VERSION "HNNBNNNYNNNNNNNNNNNNNNNNNNNNNNNNNNNNNNNNNN/4/%%%/4/'%**4NNN///"

NS_ :

BS_:

BU_: AWC BAP_Tester BMC_MLBevo BMS_MV BMS_NV DCDC_800V_PAG DCDC_HV DCDC_HV_02 DCDC_IHEV FCU_MLBevo_FCEV Gateway Gateway_PAG Ladegeraet_2 Ladegeraet_Konzern LE1 LE2 LE2_3_MLBevo_LB LE_MLBevo LE_MLBevo_LB Sub_Gateway TME

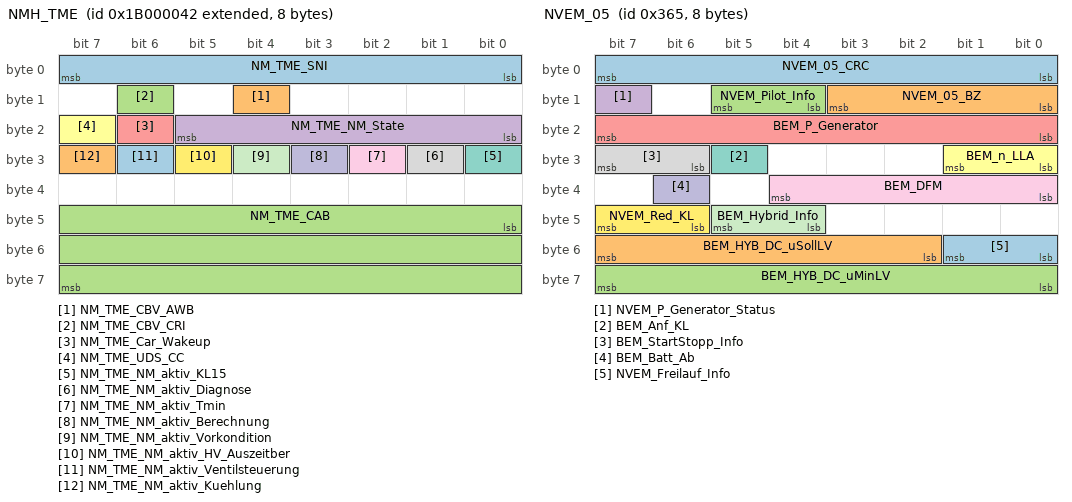
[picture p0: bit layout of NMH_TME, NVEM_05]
BO_ 2600468546 NMH_TME: 8 TME
 SG_ NM_TME_SNI : 0|8@1+ (1,0) [0|255] ""  AWC,BMC_MLBevo,BMS_MV,BMS_NV,DCDC_800V_PAG,DCDC_HV,DCDC_HV_02,DCDC_IHEV,FCU_MLBevo_FCEV,Gateway,Gateway_PAG,Ladegeraet_2,Ladegeraet_Konzern,LE1,LE2,LE2_3_MLBevo_LB,LE_MLBevo,Sub_Gateway
 SG_ NM_TME_CBV_AWB : 12|1@1+ (1,0) [0|1] ""  Gateway,Gateway_PAG
 SG_ NM_TME_CBV_CRI : 14|1@1+ (1,0) [0|1] ""  AWC,BMC_MLBevo,BMS_MV,BMS_NV,DCDC_800V_PAG,DCDC_HV,DCDC_HV_02,DCDC_IHEV,FCU_MLBevo_FCEV,Gateway,Gateway_PAG,Ladegeraet_2,Ladegeraet_Konzern,LE1,LE2,LE2_3_MLBevo_LB,LE_MLBevo,Sub_Gateway
 SG_ NM_TME_NM_State : 16|6@1+ (1,0) [0|63] "" Vector__XXX
 SG_ NM_TME_Car_Wakeup : 22|1@1+ (1,0) [0|1] ""  Gateway,Gateway_PAG
 SG_ NM_TME_UDS_CC : 23|1@1+ (1,0) [0|1] "" Vector__XXX
 SG_ NM_TME_NM_aktiv_KL15 : 24|1@1+ (1,0) [0|1] "" Vector__XXX
 SG_ NM_TME_NM_aktiv_Diagnose : 25|1@1+ (1,0) [0|1] "" Vector__XXX
 SG_ NM_TME_NM_aktiv_Tmin : 26|1@1+ (1,0) [0|1] "" Vector__XXX
 SG_ NM_TME_NM_aktiv_Berechnung : 27|1@1+ (1,0) [0|1] "" Vector__XXX
 SG_ NM_TME_NM_aktiv_Vorkondition : 28|1@1+ (1,0) [0|1] "" Vector__XXX
 SG_ NM_TME_NM_aktiv_HV_Auszeitber : 29|1@1+ (1,0) [0|1] "" Vector__XXX
 SG_ NM_TME_NM_aktiv_Ventilsteuerung : 30|1@1+ (1,0) [0|1] "" Vector__XXX
 SG_ NM_TME_NM_aktiv_Kuehlung : 31|1@1+ (1,0) [0|1] "" Vector__XXX
 SG_ NM_TME_CAB : 40|24@1+ (1,0) [0|16777215] ""  AWC,BMC_MLBevo,BMS_MV,BMS_NV,DCDC_800V_PAG,DCDC_HV,DCDC_HV_02,DCDC_IHEV,FCU_MLBevo_FCEV,Gateway,Gateway_PAG,Ladegeraet_2,Ladegeraet_Konzern,LE1,LE2,LE2_3_MLBevo_LB,LE_MLBevo,Sub_Gateway

BO_ 1635 NVEM_02: 8 Gateway
 SG_ BEM_02_Abschaltstufen : 0|3@1+ (1,0) [0|7] ""  AWC,BMC_MLBevo,DCDC_800V_PAG,DCDC_HV,DCDC_HV_02,Ladegeraet_2,Ladegeraet_Konzern,TME
 SG_ BEM_STH_Zielzeit : 3|4@1+ (5,0) [0|60] "Unit_Minut"  TME
 SG_ BEM_MMI_Vorwarnung : 7|1@1+ (1,0) [0|1] "" Vector__XXX
 SG_ NVEM_Anf_SD_schalten : 15|1@1+ (1,0) [0|1] "" Vector__XXX
 SG_ BEM_Generatordiagnose : 16|2@1+ (1,0) [0|3] "" Vector__XXX
 SG_ BEM_Red_Innengeblaese : 18|2@1+ (1,0) [0|3] ""  TME
 SG_ BEM_STH_Einschaltverbot : 20|1@1+ (1,0) [0|1] ""  TME
 SG_ BEM_HL_Regelung_Status : 21|3@1+ (1,0) [0|7] "" Vector__XXX
 SG_ BEM_Ladezustand : 24|4@1+ (10,0) [0|100] "Unit_PerCent" Vector__XXX
 SG_ BEM_Batteriediagnose : 28|3@1+ (1,0) [0|7] "" Vector__XXX
 SG_ MIB_Stromsparmodus : 31|1@1+ (1,0) [0|1] "" Vector__XXX
 SG_ BEM_REK_aktiv : 37|1@1+ (1,0) [0|1] "" Vector__XXX
 SG_ NVEM_Last_Anf : 38|2@1+ (1,0) [0|3] "" Vector__XXX
 SG_ BEM_UBDM : 40|8@1+ (0.05,5) [5.05|17.7] "Unit_Volt"  AWC,Ladegeraet_2,Ladegeraet_Konzern
 SG_ BEM_UGenSoll : 48|6@1+ (0.1,10.6) [10.6|16] "Unit_Volt" Vector__XXX
 SG_ BEM_Anf_KL15_schalten : 54|2@1+ (1,0) [0|3] "" Vector__XXX
 SG_ NVEM_Batterie_Service : 56|2@1+ (1,0) [0|3] "" Vector__XXX
 SG_ NVEM_Freigabe_OnlineUpdate : 58|1@1+ (1,0) [0|1] ""  AWC
 SG_ NVEM_Freigabe_ORU4 : 59|2@1+ (1,0) [0|3] "" Vector__XXX

BO_ 869 NVEM_05: 8 Gateway
 SG_ NVEM_05_CRC : 0|8@1+ (1,0) [0|255] "" Vector__XXX
 SG_ NVEM_05_BZ : 8|4@1+ (1,0) [0|15] "" Vector__XXX
 SG_ NVEM_Pilot_Info : 12|2@1+ (1,0) [0|3] "" Vector__XXX
 SG_ NVEM_P_Generator_Status : 15|1@1+ (1,0) [0|1] "" Vector__XXX
 SG_ BEM_P_Generator : 16|8@1+ (50,0) [0|12700] "Unit_Watt" Vector__XXX
 SG_ BEM_n_LLA : 24|2@1+ (1,0) [0|3] "" Vector__XXX
 SG_ BEM_Anf_KL : 29|1@1+ (1,0) [0|1] "" Vector__XXX
 SG_ BEM_StartStopp_Info : 30|2@1+ (1,0) [0|3] "" Vector__XXX
 SG_ BEM_DFM : 32|5@1+ (3.225,0.025) [0.025|100] "" Vector__XXX
 SG_ BEM_Batt_Ab : 38|1@1+ (1,0) [0|1] ""  DCDC_800V_PAG,DCDC_IHEV
 SG_ BEM_Hybrid_Info : 44|2@1+ (1,0) [0|3] "" Vector__XXX
 SG_ NVEM_Red_KL : 46|2@1+ (1,0) [0|3] ""  TME
 SG_ NVEM_Freilauf_Info : 48|2@1+ (1,0) [0|3] "" Vector__XXX
 SG_ BEM_HYB_DC_uSollLV : 50|6@1+ (0.1,10.6) [10.6|16] "Unit_Volt"  DCDC_800V_PAG,DCDC_HV,LE_MLBevo
 SG_ BEM_HYB_DC_uMinLV : 56|8@1+ (0.1,0) [0|25.3] "Unit_Volt" Vector__XXX

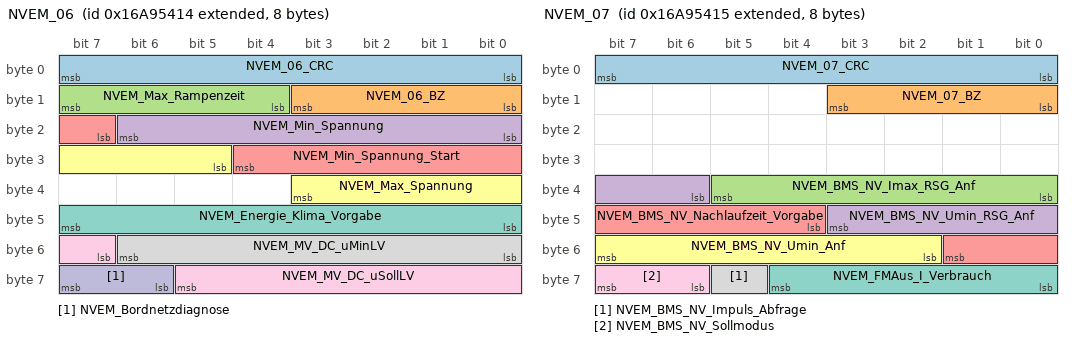
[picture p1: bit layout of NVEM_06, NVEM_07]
BO_ 2527679508 NVEM_06: 8 Gateway
 SG_ NVEM_06_CRC : 0|8@1+ (1,0) [0|255] "" Vector__XXX
 SG_ NVEM_06_BZ : 8|4@1+ (1,0) [0|15] "" Vector__XXX
 SG_ NVEM_Max_Rampenzeit : 12|4@1+ (1,0) [0|15] "" Vector__XXX
 SG_ NVEM_Min_Spannung : 16|7@1+ (0.05,10.6) [10.6|16] "Unit_Volt" Vector__XXX
 SG_ NVEM_Min_Spannung_Start : 23|6@1+ (0.1,7) [7|13.1] "Unit_Volt"  BMS_NV
 SG_ NVEM_Max_Spannung : 29|7@1+ (0.05,10.6) [10.6|16] "Unit_Volt" Vector__XXX
 SG_ NVEM_Energie_Klima_Vorgabe : 40|8@1+ (10,0) [0|2530] "Unit_WattHour" Vector__XXX
 SG_ NVEM_MV_DC_uMinLV : 48|7@1+ (0.1,3.5) [3.5|16] "Unit_Volt"  DCDC_IHEV
 SG_ NVEM_MV_DC_uSollLV : 55|7@1+ (0.05,10.6) [10.6|16] "Unit_Volt"  DCDC_IHEV
 SG_ NVEM_Bordnetzdiagnose : 62|2@1+ (1,0) [0|3] "" Vector__XXX

BO_ 2527679509 NVEM_07: 8 Gateway
 SG_ NVEM_07_CRC : 0|8@1+ (1,0) [0|255] ""  BMS_NV
 SG_ NVEM_07_BZ : 8|4@1+ (1,0) [0|15] ""  BMS_NV
 SG_ NVEM_BMS_NV_Imax_RSG_Anf : 32|6@1+ (20,0) [0|1220] "Unit_Amper"  BMS_NV
 SG_ NVEM_BMS_NV_Umin_RSG_Anf : 38|6@1+ (0.1,7) [7|13.1] "Unit_Volt"  BMS_NV
 SG_ NVEM_BMS_NV_Nachlaufzeit_Vorgabe : 44|6@1+ (1,0) [0|60] "Unit_Minut"  BMS_NV
 SG_ NVEM_BMS_NV_Umin_Anf : 50|6@1+ (0.1,9) [9|15.1] "Unit_Volt"  BMS_NV
 SG_ NVEM_FMAus_I_Verbrauch : 56|5@1+ (5,0) [0|145] "Unit_Amper"  BMS_NV
 SG_ NVEM_BMS_NV_Impuls_Abfrage : 61|1@1+ (1,0) [0|1] ""  BMS_NV
 SG_ NVEM_BMS_NV_Sollmodus : 62|2@1+ (1,0) [0|3] ""  BMS_NV

BO_ 527 NVEM_10: 8 Gateway
 SG_ NVEM_DC_uSoll_NV : 56|8@1+ (0.025,10.6) [10.6|16] "Unit_Volt"  DCDC_HV

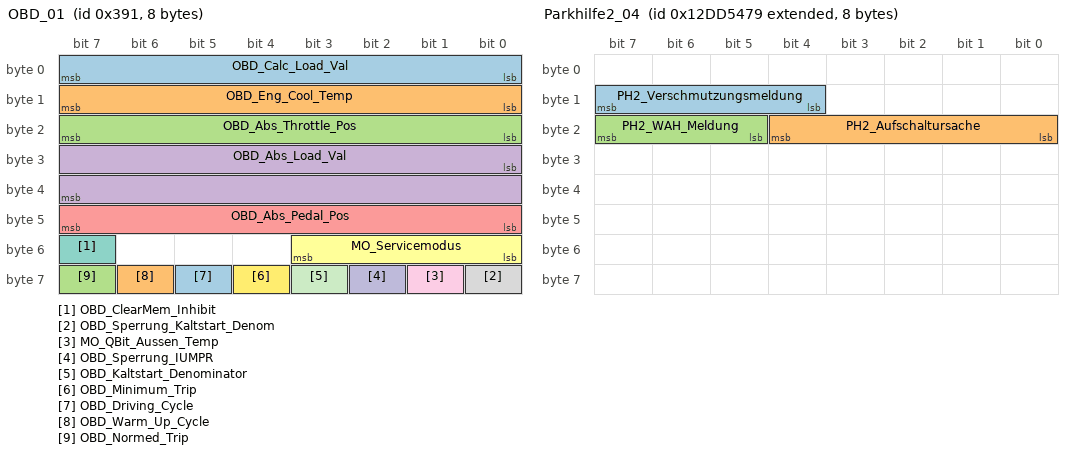
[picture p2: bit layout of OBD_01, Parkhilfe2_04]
BO_ 913 OBD_01: 8 Gateway
 SG_ OBD_Calc_Load_Val : 0|8@1+ (0.392156862745098,0) [0|100] "Unit_PerCent"  BMC_MLBevo,BMS_MV,FCU_MLBevo_FCEV,TME
 SG_ OBD_Eng_Cool_Temp : 8|8@1+ (1,-40) [-40|215] "Unit_DegreCelsi"  BMC_MLBevo,BMS_MV,FCU_MLBevo_FCEV,TME
 SG_ OBD_Abs_Throttle_Pos : 16|8@1+ (0.392156862745098,0) [0|100] "Unit_PerCent"  BMC_MLBevo,BMS_MV,TME
 SG_ OBD_Abs_Load_Val : 24|16@1+ (0.392156862745098,0) [0|25700] "Unit_PerCent"  BMC_MLBevo,BMS_MV,TME
 SG_ OBD_Abs_Pedal_Pos : 40|8@1+ (0.392156862745098,0) [0|100] "Unit_PerCent"  BMC_MLBevo,BMS_MV,FCU_MLBevo_FCEV,TME
 SG_ MO_Servicemodus : 48|4@1+ (1,0) [0|15] "" Vector__XXX
 SG_ OBD_ClearMem_Inhibit : 55|1@1+ (1,0) [0|1] ""  BMC_MLBevo,FCU_MLBevo_FCEV,TME
 SG_ OBD_Sperrung_Kaltstart_Denom : 56|1@1+ (1,0) [0|1] ""  FCU_MLBevo_FCEV,TME
 SG_ MO_QBit_Aussen_Temp : 57|1@1+ (1,0) [0|1] ""  BMC_MLBevo,Ladegeraet_Konzern,TME
 SG_ OBD_Sperrung_IUMPR : 58|1@1+ (1,0) [0|1] ""  AWC,BMC_MLBevo,BMS_MV,FCU_MLBevo_FCEV,Ladegeraet_2,Ladegeraet_Konzern,TME
 SG_ OBD_Kaltstart_Denominator : 59|1@1+ (1,0) [0|1] ""  BMC_MLBevo,BMS_MV,FCU_MLBevo_FCEV,TME
 SG_ OBD_Minimum_Trip : 60|1@1+ (1,0) [0|1] ""  AWC,BMC_MLBevo,BMS_MV,FCU_MLBevo_FCEV,Ladegeraet_2,Ladegeraet_Konzern,TME
 SG_ OBD_Driving_Cycle : 61|1@1+ (1,0) [0|1] ""  AWC,BMC_MLBevo,BMS_MV,FCU_MLBevo_FCEV,Ladegeraet_2,Ladegeraet_Konzern,TME
 SG_ OBD_Warm_Up_Cycle : 62|1@1+ (1,0) [0|1] ""  AWC,BMC_MLBevo,BMS_MV,DCDC_HV_02,DCDC_IHEV,FCU_MLBevo_FCEV,Ladegeraet_2,Ladegeraet_Konzern,TME
 SG_ OBD_Normed_Trip : 63|1@1+ (1,0) [0|1] ""  AWC,BMC_MLBevo,BMS_MV,FCU_MLBevo_FCEV,Ladegeraet_2,Ladegeraet_Konzern,TME

BO_ 2549875343 OBDC_AWC_Req: 8 Gateway
 SG_ OBDC_AWC_Req_Data : 0|64@1+ (1,0) [0|1.84467440737096E+019] ""  AWC

BO_ 2550006415 OBDC_AWC_Resp: 8 AWC
 SG_ OBDC_AWC_Resp_Data : 0|64@1+ (1,0) [0|1.84467440737096E+019] ""  Gateway,Gateway_PAG

BO_ 2549875374 OBDC_BattRegelung_Req: 8 Gateway
 SG_ OBDC_BattRegelung_Req_Data : 0|64@1+ (1,0) [0|1.84467440737096E+019] ""  BMS_NV

BO_ 2550006446 OBDC_BattRegelung_Resp: 8 BMS_NV
 SG_ OBDC_BattRegelung_Resp_Data : 0|64@1+ (1,0) [0|1.84467440737096E+019] ""  Gateway,Gateway_PAG

BO_ 2549875356 OBDC_BMS_48V_Req: 8 Gateway
 SG_ OBDC_BMS_48V_Req_Data : 0|64@1+ (1,0) [0|1.84467440737096E+019] ""  BMS_MV

BO_ 2550006428 OBDC_BMS_48V_Resp: 8 BMS_MV
 SG_ OBDC_BMS_48V_Resp_Data : 0|64@1+ (1,0) [0|1.84467440737096E+019] ""  Gateway,Gateway_PAG

BO_ 2549875399 OBDC_DCDC_HV_02_Req: 8 Gateway
 SG_ OBDC_DCDC_HV_02_Req_Data : 0|64@1+ (1,0) [0|1.84467440737096E+019] ""  DCDC_HV_02

BO_ 2550006471 OBDC_DCDC_HV_02_Resp: 8 DCDC_HV_02
 SG_ OBDC_DCDC_HV_02_Resp_Data : 0|64@1+ (1,0) [0|1.84467440737096E+019] ""  Gateway,Gateway_PAG

BO_ 2549875407 OBDC_DCDC_HV_03_Req: 8 Gateway
 SG_ OBDC_DCDC_HV_03_Req_Data : 0|64@1+ (1,0) [0|1.84467440737096E+019] ""  FCU_MLBevo_FCEV

BO_ 2550006479 OBDC_DCDC_HV_03_Resp: 8 FCU_MLBevo_FCEV
 SG_ OBDC_DCDC_HV_03_Resp_Data : 0|64@1+ (1,0) [0|1.84467440737096E+019] ""  Gateway

BO_ 2549875383 OBDC_DCDC_HV_Req: 8 Gateway
 SG_ OBDC_DCDC_HV_Req_Data : 0|64@1+ (1,0) [0|1.84467440737096E+019] ""  DCDC_800V_PAG,DCDC_HV

BO_ 2550006455 OBDC_DCDC_HV_Resp: 8 DCDC_800V_PAG
 SG_ OBDC_DCDC_HV_Resp_Data : 0|64@1+ (1,0) [0|1.84467440737096E+019] "Unit_None"  Gateway,Gateway_PAG

BO_ 2549875265 OBDC_DCDC_Req: 8 Gateway
 SG_ OBDC_DCDC_Req_Data : 0|64@1+ (1,0) [0|1.84467440737096E+019] ""  DCDC_IHEV

BO_ 2550006337 OBDC_DCDC_Resp: 8 DCDC_IHEV
 SG_ OBDC_DCDC_Resp_Data : 0|64@1+ (1,0) [0|1.84467440737096E+019] ""  Gateway,Gateway_PAG

BO_ 2549875381 OBDC_FCU_Req: 8 Gateway
 SG_ OBDC_FCU_Req_Data : 0|64@1+ (1,0) [0|1.84467440737096E+019] ""  FCU_MLBevo_FCEV

BO_ 2550006453 OBDC_FCU_Resp: 8 FCU_MLBevo_FCEV
 SG_ OBDC_FCU_Resp_Data : 0|64@1+ (1,0) [0|1.84467440737096E+019] ""  Gateway

BO_ 2549940736 OBDC_Funktionaler_Req_All: 8 Gateway
 SG_ OBDC_Funktionaler_Req_All_Data : 0|64@1+ (1,0) [0|1.84467440737096E+019] ""  AWC,BMC_MLBevo,BMS_MV,BMS_NV,DCDC_800V_PAG,DCDC_HV,DCDC_HV_02,DCDC_IHEV,FCU_MLBevo_FCEV,Ladegeraet_2,Ladegeraet_Konzern,TME

BO_ 2549875323 OBDC_Hybrid_01_Req: 8 Gateway
 SG_ OBDC_Hybrid_01_Req_Data : 0|64@1+ (1,0) [0|1.84467440737096E+019] ""  BMC_MLBevo

BO_ 2550006395 OBDC_Hybrid_01_Resp: 8 BMC_MLBevo
 SG_ OBDC_Hybrid_01_Resp_Data : 0|64@1+ (1,0) [0|1.84467440737096E+019] ""  Gateway,Gateway_PAG

BO_ 2549875398 OBDC_Ladegeraet_2_Req: 8 Gateway
 SG_ OBDC_Ladegeraet_2_Req_Data : 0|64@1+ (1,0) [0|1.84467440737096E+019] ""  Ladegeraet_2

BO_ 2550006470 OBDC_Ladegeraet_2_Resp: 8 Ladegeraet_2
 SG_ OBDC_Ladegeraet_2_Resp_Data : 0|64@1+ (1,0) [0|1.84467440737096E+019] ""  Gateway,Gateway_PAG

BO_ 2549875268 OBDC_Ladegeraet_Req: 8 Gateway
 SG_ OBDC_Ladegeraet_Req_Data : 0|64@1+ (1,0) [0|1.84467440737096E+019] ""  Ladegeraet_Konzern

BO_ 2550006340 OBDC_Ladegeraet_Resp: 8 Ladegeraet_Konzern
 SG_ OBDC_Ladegeraet_Resp_Data : 0|64@1+ (1,0) [0|1.84467440737096E+019] ""  Gateway,Gateway_PAG

BO_ 2549903568 OBDC_SSN_BJB_Req: 8 Gateway
 SG_ OBDC_SSN_BJB_Req_Data : 0|64@1+ (1,0) [0|1.84467440737096E+019] ""  BMC_MLBevo

BO_ 2550034640 OBDC_SSN_BJB_Resp: 8 BMC_MLBevo
 SG_ OBDC_SSN_BJB_Resp_Data : 0|64@1+ (1,0) [0|1.84467440737096E+019] ""  Gateway,Gateway_PAG

BO_ 2549903569 OBDC_SSN_CMC_01_Req: 8 Gateway
 SG_ OBDC_SSN_CMC_01_Req_Data : 0|64@1+ (1,0) [0|1.84467440737096E+019] ""  BMC_MLBevo

BO_ 2550034641 OBDC_SSN_CMC_01_Resp: 8 BMC_MLBevo
 SG_ OBDC_SSN_CMC_01_Resp_Data : 0|64@1+ (1,0) [0|1.84467440737096E+019] ""  Gateway,Gateway_PAG

BO_ 2549903570 OBDC_SSN_CMC_02_Req: 8 Gateway
 SG_ OBDC_SSN_CMC_02_Req_Data : 0|64@1+ (1,0) [0|1.84467440737096E+019] ""  BMC_MLBevo

BO_ 2550034642 OBDC_SSN_CMC_02_Resp: 8 BMC_MLBevo
 SG_ OBDC_SSN_CMC_02_Resp_Data : 0|64@1+ (1,0) [0|1.84467440737096E+019] ""  Gateway,Gateway_PAG

BO_ 2549903571 OBDC_SSN_CMC_03_Req: 8 Gateway
 SG_ OBDC_SSN_CMC_03_Req_Data : 0|64@1+ (1,0) [0|1.84467440737096E+019] ""  BMC_MLBevo

BO_ 2550034643 OBDC_SSN_CMC_03_Resp: 8 BMC_MLBevo
 SG_ OBDC_SSN_CMC_03_Resp_Data : 0|64@1+ (1,0) [0|1.84467440737096E+019] ""  Gateway,Gateway_PAG

BO_ 2549903572 OBDC_SSN_CMC_04_Req: 8 Gateway
 SG_ OBDC_SSN_CMC_04_Req_Data : 0|64@1+ (1,0) [0|1.84467440737096E+019] ""  BMC_MLBevo

BO_ 2550034644 OBDC_SSN_CMC_04_Resp: 8 BMC_MLBevo
 SG_ OBDC_SSN_CMC_04_Resp_Data : 0|64@1+ (1,0) [0|1.84467440737096E+019] ""  Gateway,Gateway_PAG

BO_ 2549903573 OBDC_SSN_CMC_05_Req: 8 Gateway
 SG_ OBDC_SSN_CMC_05_Req_Data : 0|64@1+ (1,0) [0|1.84467440737096E+019] ""  BMC_MLBevo

BO_ 2550034645 OBDC_SSN_CMC_05_Resp: 8 BMC_MLBevo
 SG_ OBDC_SSN_CMC_05_Resp_Data : 0|64@1+ (1,0) [0|1.84467440737096E+019] ""  Gateway,Gateway_PAG

BO_ 2549903574 OBDC_SSN_CMC_06_Req: 8 Gateway
 SG_ OBDC_SSN_CMC_06_Req_Data : 0|64@1+ (1,0) [0|1.84467440737096E+019] ""  BMC_MLBevo

BO_ 2550034646 OBDC_SSN_CMC_06_Resp: 8 BMC_MLBevo
 SG_ OBDC_SSN_CMC_06_Resp_Data : 0|64@1+ (1,0) [0|1.84467440737096E+019] ""  Gateway,Gateway_PAG

BO_ 2549903575 OBDC_SSN_CMC_07_Req: 8 Gateway
 SG_ OBDC_SSN_CMC_07_Req_Data : 0|64@1+ (1,0) [0|1.84467440737096E+019] ""  BMC_MLBevo

BO_ 2550034647 OBDC_SSN_CMC_07_Resp: 8 BMC_MLBevo
 SG_ OBDC_SSN_CMC_07_Resp_Data : 0|64@1+ (1,0) [0|1.84467440737096E+019] ""  Gateway,Gateway_PAG

BO_ 2549903576 OBDC_SSN_CMC_08_Req: 8 Gateway
 SG_ OBDC_SSN_CMC_08_Req_Data : 0|64@1+ (1,0) [0|1.84467440737096E+019] ""  BMC_MLBevo

BO_ 2550034648 OBDC_SSN_CMC_08_Resp: 8 BMC_MLBevo
 SG_ OBDC_SSN_CMC_08_Resp_Data : 0|64@1+ (1,0) [0|1.84467440737096E+019] ""  Gateway,Gateway_PAG

BO_ 2549903577 OBDC_SSN_CMC_09_Req: 8 Gateway
 SG_ OBDC_SSN_CMC_09_Req_Data : 0|64@1+ (1,0) [0|1.84467440737096E+019] ""  BMC_MLBevo

BO_ 2550034649 OBDC_SSN_CMC_09_Resp: 8 BMC_MLBevo
 SG_ OBDC_SSN_CMC_09_Resp_Data : 0|64@1+ (1,0) [0|1.84467440737096E+019] ""  Gateway,Gateway_PAG

BO_ 2549903578 OBDC_SSN_CMC_10_Req: 8 Gateway
 SG_ OBDC_SSN_CMC_10_Req_Data : 0|64@1+ (1,0) [0|1.84467440737096E+019] ""  BMC_MLBevo

BO_ 2550034650 OBDC_SSN_CMC_10_Resp: 8 BMC_MLBevo
 SG_ OBDC_SSN_CMC_10_Resp_Data : 0|64@1+ (1,0) [0|1.84467440737096E+019] ""  Gateway,Gateway_PAG

BO_ 2549903579 OBDC_SSN_CMC_11_Req: 8 Gateway
 SG_ OBDC_SSN_CMC_11_Req_Data : 0|64@1+ (1,0) [0|1.84467440737096E+019] ""  BMC_MLBevo

BO_ 2550034651 OBDC_SSN_CMC_11_Resp: 8 BMC_MLBevo
 SG_ OBDC_SSN_CMC_11_Resp_Data : 0|64@1+ (1,0) [0|1.84467440737096E+019] ""  Gateway,Gateway_PAG

BO_ 2549903580 OBDC_SSN_CMC_12_Req: 8 Gateway
 SG_ OBDC_SSN_CMC_12_Req_Data : 0|64@1+ (1,0) [0|1.84467440737096E+019] ""  BMC_MLBevo

BO_ 2550034652 OBDC_SSN_CMC_12_Resp: 8 BMC_MLBevo
 SG_ OBDC_SSN_CMC_12_Resp_Data : 0|64@1+ (1,0) [0|1.84467440737096E+019] ""  Gateway,Gateway_PAG

BO_ 2549903601 OBDC_SSN_CMC_13_Req: 8 Gateway
 SG_ OBDC_SSN_CMC_13_Req_Data : 0|64@1+ (1,0) [0|1.84467440737096E+019] ""  BMC_MLBevo

BO_ 2550034673 OBDC_SSN_CMC_13_Resp: 8 BMC_MLBevo
 SG_ OBDC_SSN_CMC_13_Resp_Data : 0|64@1+ (1,0) [0|1.84467440737096E+019] ""  Gateway,Gateway_PAG

BO_ 2549903602 OBDC_SSN_CMC_14_Req: 8 Gateway
 SG_ OBDC_SSN_CMC_14_Req_Data : 0|64@1+ (1,0) [0|1.84467440737096E+019] ""  BMC_MLBevo

BO_ 2550034674 OBDC_SSN_CMC_14_Resp: 8 BMC_MLBevo
 SG_ OBDC_SSN_CMC_14_Resp_Data : 0|64@1+ (1,0) [0|1.84467440737096E+019] ""  Gateway,Gateway_PAG

BO_ 2549903603 OBDC_SSN_CMC_15_Req: 8 Gateway
 SG_ OBDC_SSN_CMC_15_Req_Data : 0|64@1+ (1,0) [0|1.84467440737096E+019] ""  BMC_MLBevo

BO_ 2550034675 OBDC_SSN_CMC_15_Resp: 8 BMC_MLBevo
 SG_ OBDC_SSN_CMC_15_Resp_Data : 0|64@1+ (1,0) [0|1.84467440737096E+019] ""  Gateway,Gateway_PAG

BO_ 2549875380 OBDC_TelemetrieSG_Req: 8 Gateway
 SG_ OBDC_TelemetrieSG_Req_Data : 0|64@1+ (1,0) [0|1.84467440737096E+019] ""  Sub_Gateway

BO_ 2550006452 OBDC_TelemetrieSG_Resp: 8 Sub_Gateway
 SG_ OBDC_TelemetrieSG_Resp_Data : 0|64@1+ (1,0) [0|1.84467440737096E+019] ""  Gateway

BO_ 2549875266 OBDC_TME_Req: 8 Gateway
 SG_ OBDC_TME_Req_Data : 0|64@1+ (1,0) [0|1.84467440737096E+019] ""  TME

BO_ 2550006338 OBDC_TME_Resp: 8 TME
 SG_ OBDC_TME_Resp_Data : 0|64@1+ (1,0) [0|1.84467440737096E+019] ""  Gateway,Gateway_PAG

BO_ 2589283656 ORU_01: 8 Gateway
 SG_ ORU_Warnung : 58|2@1+ (1,0) [0|3] "" Vector__XXX
 SG_ ORU_Status : 61|3@1+ (1,0) [0|7] ""  AWC,BMC_MLBevo,DCDC_800V_PAG,DCDC_HV,DCDC_HV_02,Ladegeraet_2,Ladegeraet_Konzern,TME

BO_ 872 Parkhilfe2_01: 8 Gateway
 SG_ PH2_Visualisierung : 0|3@1+ (1,0) [0|7] ""  AWC
 SG_ PDC2_Tonausgabe_Front : 4|4@1+ (1,0) [0|15] "" Vector__XXX
 SG_ PDC2_Tonausgabe_Heck : 8|4@1+ (1,0) [0|15] "" Vector__XXX
 SG_ PH2_nachtr_Stopp_An : 12|1@1+ (1,0) [0|1] "" Vector__XXX
 SG_ PH2_Abschaltursache : 13|3@1+ (1,0) [0|7] ""  AWC
 SG_ PH2_Opt_Anzeige_V_ein : 16|1@1+ (1,0) [0|1] "" Vector__XXX
 SG_ PH2_Opt_Anzeige_H_ein : 17|1@1+ (1,0) [0|1] "" Vector__XXX
 SG_ PH2_Opt_Anz_V_Hindernis : 18|1@1+ (1,0) [0|1] "" Vector__XXX
 SG_ PH2_Opt_Anz_H_Hindernis : 19|1@1+ (1,0) [0|1] "" Vector__XXX
 SG_ PH2_Tongeber_V_aktiv : 20|1@1+ (1,0) [0|1] "" Vector__XXX
 SG_ PH2_Tongeber_H_aktiv : 21|1@1+ (1,0) [0|1] "" Vector__XXX
 SG_ PH2_Tongeber_mute : 22|1@1+ (1,0) [0|1] "" Vector__XXX
 SG_ PH2_Anf_Audioabsenkung : 23|1@1+ (1,0) [0|1] "" Vector__XXX
 SG_ PH2_Tongeber_H_verfuegbar : 24|1@1+ (1,0) [0|1] "" Vector__XXX
 SG_ PH2_Taster : 28|2@1+ (1,0) [0|3] "" Vector__XXX
 SG_ PH2_Anf_Verdeck : 30|2@1+ (1,0) [0|3] "" Vector__XXX
 SG_ PH2_Frequenz_hinten : 32|4@1+ (1,0) [0|15] "" Vector__XXX
 SG_ PH2_Lautstaerke_hinten : 36|4@1+ (1,0) [0|15] "" Vector__XXX
 SG_ PH2_Frequenz_vorn : 40|4@1+ (1,0) [0|15] "" Vector__XXX
 SG_ PH2_Lautstaerke_vorn : 44|4@1+ (1,0) [0|15] "" Vector__XXX
 SG_ PH2_StartStopp_Info : 49|2@1+ (1,0) [0|3] "" Vector__XXX
 SG_ PH2_Stoermeldung : 52|4@1+ (1,0) [0|15] "" Vector__XXX
 SG_ PH2_defekt : 56|1@1+ (1,0) [0|1] "" Vector__XXX
 SG_ PH2_gestoert : 57|1@1+ (1,0) [0|1] "" Vector__XXX
 SG_ PH2_Systemzustand : 58|3@1+ (1,0) [0|7] ""  AWC
 SG_ PH2_Display_Kundenwunsch : 61|2@1+ (1,0) [0|3] "" Vector__XXX

BO_ 2463978617 Parkhilfe2_04: 8 Gateway
 SG_ PH2_Verschmutzungsmeldung : 12|4@1+ (1,0) [0|15] "" Vector__XXX
 SG_ PH2_Aufschaltursache : 16|5@1+ (1,0) [0|31] ""  AWC
 SG_ PH2_WAH_Meldung : 21|3@1+ (1,0) [0|7] "" Vector__XXX

BO_ 1175 Parkhilfe_01: 8 Gateway
 SG_ PH_Visualisierung : 0|3@1+ (1,0) [0|7] ""  AWC
 SG_ PDC_Tonausgabe_Front : 4|4@1+ (1,0) [0|15] "" Vector__XXX
 SG_ PDC_Tonausgabe_Heck : 8|4@1+ (1,0) [0|15] "" Vector__XXX
 SG_ PH_nachtr_Stopp_Anf : 12|1@1+ (1,0) [0|1] "" Vector__XXX
 SG_ PH_Abschaltursache : 13|3@1+ (1,0) [0|7] ""  AWC
 SG_ PH_Opt_Anzeige_V_ein : 16|1@1+ (1,0) [0|1] "" Vector__XXX
 SG_ PH_Opt_Anzeige_H_ein : 17|1@1+ (1,0) [0|1] "" Vector__XXX
 SG_ PH_Opt_Anz_V_Hindernis : 18|1@1+ (1,0) [0|1] "" Vector__XXX
 SG_ PH_Opt_Anz_H_Hindernis : 19|1@1+ (1,0) [0|1] "" Vector__XXX
 SG_ PH_Tongeber_V_aktiv : 20|1@1+ (1,0) [0|1] "" Vector__XXX
 SG_ PH_Tongeber_H_aktiv : 21|1@1+ (1,0) [0|1] "" Vector__XXX
 SG_ PH_Tongeber_mute : 22|1@1+ (1,0) [0|1] "" Vector__XXX
 SG_ PH_Anf_Audioabsenkung : 23|1@1+ (1,0) [0|1] "" Vector__XXX
 SG_ PH_Tongeber_H_verfuegbar : 24|1@1+ (1,0) [0|1] "" Vector__XXX
 SG_ PLA_Anf_Aufschaltung_RVC : 25|1@1+ (1,0) [0|1] "" Vector__XXX
 SG_ PH_Taster : 28|2@1+ (1,0) [0|3] "" Vector__XXX
 SG_ PH_Anf_Verdeck : 30|2@1+ (1,0) [0|3] "" Vector__XXX
 SG_ PH_Frequenz_hinten : 32|4@1+ (1,0) [0|15] "" Vector__XXX
 SG_ PH_Lautstaerke_hinten : 36|4@1+ (1,0) [0|15] "" Vector__XXX
 SG_ PH_Frequenz_vorn : 40|4@1+ (1,0) [0|15] "" Vector__XXX
 SG_ PH_Lautstaerke_vorn : 44|4@1+ (1,0) [0|15] "" Vector__XXX
 SG_ PH_StartStopp_Info : 49|2@1+ (1,0) [0|3] "" Vector__XXX
 SG_ PH_Stoermeldung : 52|4@1+ (1,0) [0|15] "" Vector__XXX
 SG_ PH_defekt : 56|1@1+ (1,0) [0|1] "" Vector__XXX
 SG_ PH_gestoert : 57|1@1+ (1,0) [0|1] "" Vector__XXX
 SG_ PH_Systemzustand : 58|3@1+ (1,0) [0|7] ""  AWC
 SG_ PH_Display_Kundenwunsch : 61|2@1+ (1,0) [0|3] "" Vector__XXX

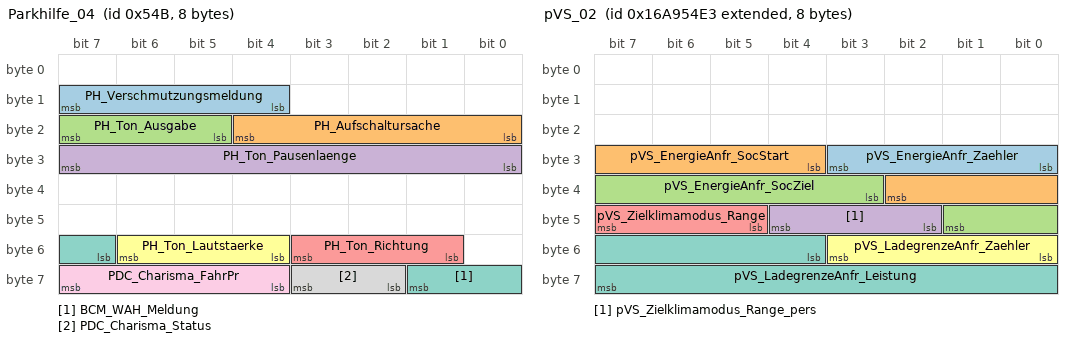
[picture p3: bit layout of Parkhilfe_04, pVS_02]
BO_ 1355 Parkhilfe_04: 8 Gateway
 SG_ PH_Verschmutzungsmeldung : 12|4@1+ (1,0) [0|15] "" Vector__XXX
 SG_ PH_Aufschaltursache : 16|5@1+ (1,0) [0|31] ""  AWC
 SG_ PH_Ton_Ausgabe : 21|3@1+ (1,0) [0|7] "" Vector__XXX
 SG_ PH_Ton_Pausenlaenge : 24|8@1+ (1,0) [0|255] "" Vector__XXX
 SG_ PH_Ton_Richtung : 49|3@1+ (1,0) [0|7] "" Vector__XXX
 SG_ PH_Ton_Lautstaerke : 52|3@1+ (1,0) [0|7] "" Vector__XXX
 SG_ BCM_WAH_Meldung : 55|3@1+ (1,0) [0|7] "" Vector__XXX
 SG_ PDC_Charisma_Status : 58|2@1+ (1,0) [0|3] "" Vector__XXX
 SG_ PDC_Charisma_FahrPr : 60|4@1+ (1,0) [0|15] "" Vector__XXX

BO_ 617 PIF_01: 8 Gateway
 SG_ PIF_Toggle : 0|1@1+ (1,0) [0|1] ""  TME
 SG_ PIF_ST_Status : 1|2@1+ (1,0) [0|3] ""  TME
 SG_ PIF_MT_Status : 3|2@1+ (1,0) [0|3] ""  TME
 SG_ PIF_LT_Status : 5|2@1+ (1,0) [0|3] ""  TME
 SG_ PIF_Identifier : 7|3@1+ (1,0) [0|7] ""  TME
 SG_ PIF_ST_Bin_0 : 10|2@1+ (1,0) [0|3] ""  TME
 SG_ PIF_ST_Bin_1 : 12|2@1+ (1,0) [0|3] ""  TME
 SG_ PIF_ST_Bin_2 : 14|2@1+ (1,0) [0|3] ""  TME
 SG_ PIF_ST_Bin_3 : 16|2@1+ (1,0) [0|3] ""  TME
 SG_ PIF_ST_Bin_4 : 18|2@1+ (1,0) [0|3] ""  TME
 SG_ PIF_ST_Bin_5 : 20|2@1+ (1,0) [0|3] ""  TME
 SG_ PIF_ST_Bin_6 : 22|2@1+ (1,0) [0|3] ""  TME
 SG_ PIF_ST_Bin_7 : 24|2@1+ (1,0) [0|3] ""  TME
 SG_ PIF_ST_Bin_8 : 26|2@1+ (1,0) [0|3] ""  TME
 SG_ PIF_MT_Bin_0 : 28|2@1+ (1,0) [0|3] ""  TME
 SG_ PIF_MT_Bin_1 : 30|2@1+ (1,0) [0|3] ""  TME
 SG_ PIF_MT_Bin_2 : 32|2@1+ (1,0) [0|3] ""  TME
 SG_ PIF_MT_Bin_3 : 34|2@1+ (1,0) [0|3] ""  TME
 SG_ PIF_MT_Bin_4 : 36|2@1+ (1,0) [0|3] ""  TME
 SG_ PIF_MT_Bin_5 : 38|2@1+ (1,0) [0|3] ""  TME
 SG_ PIF_MT_Bin_6 : 40|2@1+ (1,0) [0|3] ""  TME
 SG_ PIF_MT_Bin_7 : 42|2@1+ (1,0) [0|3] ""  TME
 SG_ PIF_MT_Bin_8 : 44|2@1+ (1,0) [0|3] ""  TME
 SG_ PIF_LT_Bin_0 : 46|2@1+ (1,0) [0|3] ""  TME
 SG_ PIF_LT_Bin_1 : 48|2@1+ (1,0) [0|3] ""  TME
 SG_ PIF_LT_Bin_2 : 50|2@1+ (1,0) [0|3] ""  TME
 SG_ PIF_LT_Bin_3 : 52|2@1+ (1,0) [0|3] ""  TME
 SG_ PIF_LT_Bin_4 : 54|2@1+ (1,0) [0|3] ""  TME
 SG_ PIF_LT_Bin_5 : 56|2@1+ (1,0) [0|3] ""  TME
 SG_ PIF_LT_Bin_6 : 58|2@1+ (1,0) [0|3] ""  TME
 SG_ PIF_LT_Bin_7 : 60|2@1+ (1,0) [0|3] ""  TME
 SG_ PIF_LT_Bin_8 : 62|2@1+ (1,0) [0|3] ""  TME

BO_ 2549876804 PnC_Ladegeraet_Req: 8 Ladegeraet_Konzern
 SG_ PnC_Ladegeraet_Req_Data : 0|64@1+ (1,0) [0|1.84467440737096E+019] "Unit_None"  Gateway,Gateway_PAG

BO_ 2550007876 PnC_Ladegeraet_Resp: 8 Gateway
 SG_ PnC_Ladegeraet_Resp_Data : 0|64@1+ (1,0) [0|1.84467440737096E+019] "Unit_None"  Ladegeraet_Konzern

BO_ 2527679715 pVS_02: 8 Gateway_PAG
 SG_ pVS_EnergieAnfr_Zaehler : 24|4@1+ (1,0) [0|13] "Unit_None"  BMC_MLBevo
 SG_ pVS_EnergieAnfr_SocStart : 28|7@1+ (1,0) [0|100] "Unit_PerCent"  BMC_MLBevo
 SG_ pVS_EnergieAnfr_SocZiel : 35|7@1+ (1,0) [0|100] "Unit_PerCent"  BMC_MLBevo
 SG_ pVS_Zielklimamodus_Range_pers : 42|3@1+ (1,0) [0|7] "" Vector__XXX
 SG_ pVS_Zielklimamodus_Range : 45|3@1+ (1,0) [0|7] "" Vector__XXX
 SG_ pVS_LadegrenzeAnfr_Zaehler : 48|4@1+ (1,0) [0|13] "Unit_None"  BMC_MLBevo
 SG_ pVS_LadegrenzeAnfr_Leistung : 52|12@1+ (200,0) [0|818600] "Unit_Watt"  BMC_MLBevo

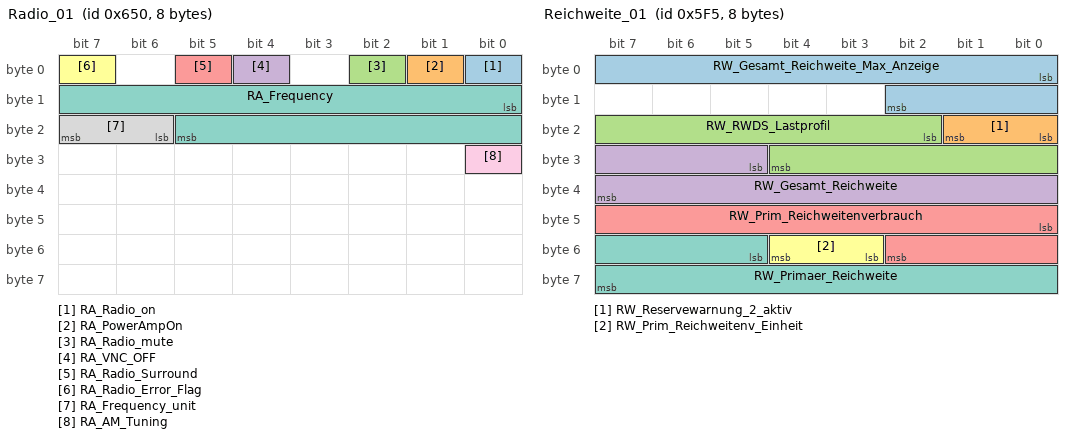
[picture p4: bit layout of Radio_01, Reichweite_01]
BO_ 1616 Radio_01: 8 Gateway
 SG_ RA_Radio_on : 0|1@1+ (1,0) [0|1] ""  DCDC_800V_PAG,DCDC_IHEV
 SG_ RA_PowerAmpOn : 1|1@1+ (1,0) [0|1] "" Vector__XXX
 SG_ RA_Radio_mute : 2|1@1+ (1,0) [0|1] "" Vector__XXX
 SG_ RA_VNC_OFF : 4|1@1+ (1,0) [0|1] "" Vector__XXX
 SG_ RA_Radio_Surround : 5|1@1+ (1,0) [0|1] "" Vector__XXX
 SG_ RA_Radio_Error_Flag : 7|1@1+ (1,0) [0|1] "" Vector__XXX
 SG_ RA_Frequency : 8|14@1+ (1,0) [0|16383] ""  DCDC_800V_PAG,DCDC_IHEV
 SG_ RA_Frequency_unit : 22|2@1+ (1,0) [0|3] ""  DCDC_800V_PAG,DCDC_IHEV
 SG_ RA_AM_Tuning : 24|1@1+ (1,0) [0|1] ""  DCDC_800V_PAG,DCDC_IHEV

BO_ 1525 Reichweite_01: 8 Gateway
 SG_ RW_Gesamt_Reichweite_Max_Anzeige : 0|11@1+ (1,0) [0|2047] ""  Sub_Gateway
 SG_ RW_Reservewarnung_2_aktiv : 16|2@1+ (1,0) [0|3] ""  Sub_Gateway,TME
 SG_ RW_RWDS_Lastprofil : 18|11@1+ (1,0) [0|2045] "Unit_Amper"  BMC_MLBevo,Sub_Gateway
 SG_ RW_Gesamt_Reichweite : 29|11@1+ (1,0) [0|2044] "Unit_KiloMeter"  Ladegeraet_Konzern,Sub_Gateway
 SG_ RW_Prim_Reichweitenverbrauch : 40|11@1+ (0.1,0) [0|204.4] "Unit_None"  Ladegeraet_Konzern,Sub_Gateway
 SG_ RW_Prim_Reichweitenv_Einheit : 51|2@1+ (1,0) [0|3] ""  Sub_Gateway
 SG_ RW_Primaer_Reichweite : 53|11@1+ (1,0) [0|2044] "Unit_KiloMeter"  Ladegeraet_Konzern,Sub_Gateway

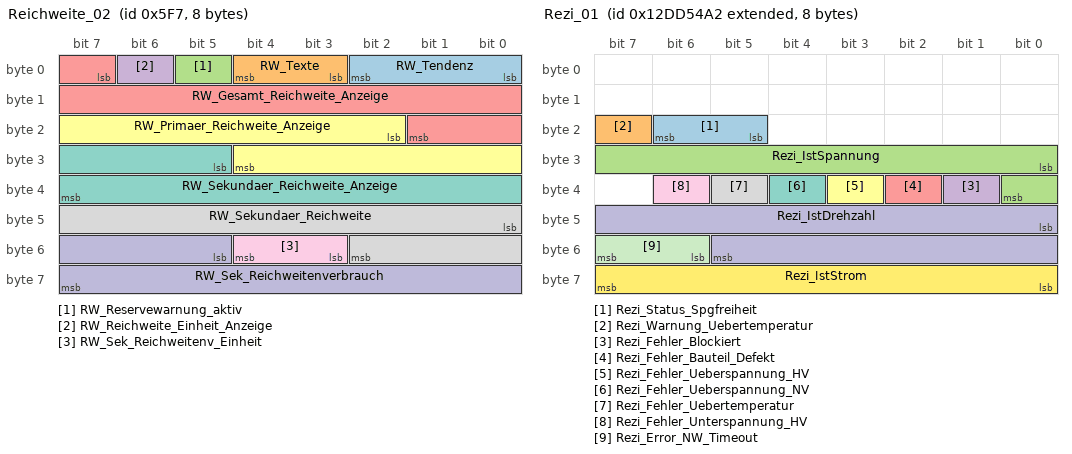
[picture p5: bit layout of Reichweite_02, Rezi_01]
BO_ 1527 Reichweite_02: 8 Gateway
 SG_ RW_Tendenz : 0|3@1+ (1,0) [0|7] ""  Sub_Gateway
 SG_ RW_Texte : 3|2@1+ (1,0) [0|3] ""  Sub_Gateway
 SG_ RW_Reservewarnung_aktiv : 5|1@1+ (1,0) [0|1] ""  Sub_Gateway,TME
 SG_ RW_Reichweite_Einheit_Anzeige : 6|1@1+ (1,0) [0|1] ""  Sub_Gateway
 SG_ RW_Gesamt_Reichweite_Anzeige : 7|11@1+ (1,0) [0|2044] ""  Sub_Gateway
 SG_ RW_Primaer_Reichweite_Anzeige : 18|11@1+ (1,0) [0|2044] ""  Ladegeraet_Konzern,Sub_Gateway
 SG_ RW_Sekundaer_Reichweite_Anzeige : 29|11@1+ (1,0) [0|2044] ""  Sub_Gateway
 SG_ RW_Sekundaer_Reichweite : 40|11@1+ (1,0) [0|2044] "Unit_KiloMeter"  Ladegeraet_Konzern,Sub_Gateway
 SG_ RW_Sek_Reichweitenv_Einheit : 51|2@1+ (1,0) [0|3] ""  Sub_Gateway
 SG_ RW_Sek_Reichweitenverbrauch : 53|11@1+ (0.1,0) [0|204.4] "Unit_None"  Sub_Gateway

BO_ 2463978658 Rezi_01: 8 FCU_MLBevo_FCEV
 SG_ Rezi_Status_Spgfreiheit : 21|2@1+ (1,0) [0|3] ""  Gateway
 SG_ Rezi_Warnung_Uebertemperatur : 23|1@1+ (1,0) [0|1] "" Vector__XXX
 SG_ Rezi_IstSpannung : 24|9@1+ (2,0) [0|1020] "Unit_Volt"  Gateway
 SG_ Rezi_Fehler_Blockiert : 33|1@1+ (1,0) [0|1] "" Vector__XXX
 SG_ Rezi_Fehler_Bauteil_Defekt : 34|1@1+ (1,0) [0|1] "" Vector__XXX
 SG_ Rezi_Fehler_Ueberspannung_HV : 35|1@1+ (1,0) [0|1] "" Vector__XXX
 SG_ Rezi_Fehler_Ueberspannung_NV : 36|1@1+ (1,0) [0|1] "" Vector__XXX
 SG_ Rezi_Fehler_Uebertemperatur : 37|1@1+ (1,0) [0|1] "" Vector__XXX
 SG_ Rezi_Fehler_Unterspannung_HV : 38|1@1+ (1,0) [0|1] "" Vector__XXX
 SG_ Rezi_IstDrehzahl : 40|14@1+ (2,0) [0|32764] "Unit_RevPerMinute" Vector__XXX
 SG_ Rezi_Error_NW_Timeout : 54|2@1+ (1,0) [0|3] "" Vector__XXX
 SG_ Rezi_IstStrom : 56|8@1+ (0.1,0) [0|25.4] "Unit_Amper" Vector__XXX

BO_ 1126 RTM_01: 8 Gateway
 SG_ RTM_Warnstatus : 62|2@1+ (1,0) [0|3] ""  Sub_Gateway

BO_ 2527679790 RTM_02: 8 Sub_Gateway
 SG_ RTM_02_Dummy : 63|1@1+ (1,0) [0|1] ""  Gateway,Gateway_PAG

BO_ 2527679791 RTM_03: 8 Sub_Gateway
 SG_ RTM_03_Dummy : 63|1@1+ (1,0) [0|1] ""  Gateway,Gateway_PAG

BO_ 2527679792 RTM_04: 8 Gateway
 SG_ RTM_04_Dummy : 63|1@1+ (1,0) [0|1] ""  Sub_Gateway

BO_ 1313 STH_01: 8 Gateway
 SG_ STH_Funk_ein : 0|1@1+ (1,0) [0|1] ""  Ladegeraet_Konzern
 SG_ STH_Funk_aus : 1|1@1+ (1,0) [0|1] ""  Ladegeraet_Konzern
 SG_ STH_Zusatzheizung : 2|1@1+ (1,0) [0|1] ""  TME
 SG_ STH_LED : 3|1@1+ (1,0) [0|1] ""  TME
 SG_ STH_Pumpe_ein : 4|1@1+ (1,0) [0|1] ""  TME
 SG_ STH_Geblaese : 5|1@1+ (1,0) [0|1] ""  TME
 SG_ STH_EKP_Anst : 6|1@1+ (1,0) [0|1] "" Vector__XXX
 SG_ STH_Start_folgt : 7|1@1+ (1,0) [0|1] "" Vector__XXX
 SG_ STH_Ventiloeffnungszeit : 8|6@1+ (1,0) [0|63] "Unit_Minut" Vector__XXX
 SG_ STH_Ventil_Status : 14|1@1+ (1,0) [0|1] ""  TME
 SG_ STH_Fehler_ElWaPu : 15|1@1+ (1,0) [0|1] ""  TME
 SG_ STH_Waermeeintrag : 16|6@1+ (1,0) [0|63] "" Vector__XXX
 SG_ STH_Pumpen_Anf_extern : 22|1@1+ (1,0) [0|1] "" Vector__XXX
 SG_ STH_KL_HUP : 23|1@1+ (1,0) [0|1] "" Vector__XXX
 SG_ STH_KVS : 24|13@1+ (1,0) [0|8191] "Unit_MilliLiter" Vector__XXX
 SG_ STH_Fehlerstatus : 37|3@1+ (1,0) [0|7] ""  TME
 SG_ STH_Heizleistung : 40|8@1+ (1,0) [0|255] "" Vector__XXX
 SG_ STH_Wassertemp : 48|8@1+ (0.75,-40) [-40|142.25] "Unit_DegreCelsi"  TME
 SG_ STH_Texte : 56|3@1+ (1,0) [0|7] ""  TME
 SG_ STH_Motorvorwaermung : 59|1@1+ (1,0) [0|1] "" Vector__XXX
 SG_ STH_Servicemode : 60|1@1+ (1,0) [0|1] "" Vector__XXX
 SG_ STH_war_aktiv : 61|1@1+ (1,0) [0|1] "" Vector__XXX
 SG_ STH_KVS_Ueberlauf : 62|1@1+ (1,0) [0|1] "" Vector__XXX
 SG_ STH_SH_ZH : 63|1@1+ (1,0) [0|1] "" Vector__XXX

BO_ 505 STP_03: 8 Gateway
 SG_ STP_03_CRC : 0|8@1+ (1,0) [0|255] "" Vector__XXX
 SG_ STP_03_BZ : 8|4@1+ (1,0) [0|15] "" Vector__XXX
 SG_ STP_Slave_Status : 12|4@1+ (1,0) [0|15] "" Vector__XXX
 SG_ FZE_STP_Abschaltbedingung : 16|3@1+ (1,0) [0|7] "" Vector__XXX
 SG_ ACA_HF_Grund_AV_AB : 19|3@1+ (1,0) [0|7] "" Vector__XXX
 SG_ FZE_STP_Status : 22|2@1+ (1,0) [0|3] "" Vector__XXX
 SG_ STP_Notlaufaktivierung : 25|1@1+ (1,0) [0|1] "" Vector__XXX
 SG_ STP_Funktion_freigegeben : 26|1@1+ (1,0) [0|1] ""  TME
 SG_ ACA_QF_Status_Anzeige : 27|4@1+ (1,0) [0|15] "" Vector__XXX
 SG_ ACF_SwuFahrerUnaufmerksam : 31|1@1+ (1,0) [0|1] "" Vector__XXX
 SG_ ACA_QF_Fahreruebernahme : 32|2@1+ (1,0) [0|3] "" Vector__XXX
 SG_ ACA_HF_Status : 34|4@1+ (1,0) [0|15] "" Vector__XXX
 SG_ FZE_Spurwechsel_erkannt_li : 40|1@1+ (1,0) [0|1] "" Vector__XXX
 SG_ FZE_Spurwechsel_erkannt_re : 41|1@1+ (1,0) [0|1] "" Vector__XXX
 SG_ ACF_Spurwechsel_moeglich : 42|1@1+ (1,0) [0|1] "" Vector__XXX
 SG_ ACF_Spurwechsel_wahrscheinlich : 43|1@1+ (1,0) [0|1] "" Vector__XXX
 SG_ FZE_STP_Aktivierverhinderung : 44|2@1+ (1,0) [0|3] "" Vector__XXX

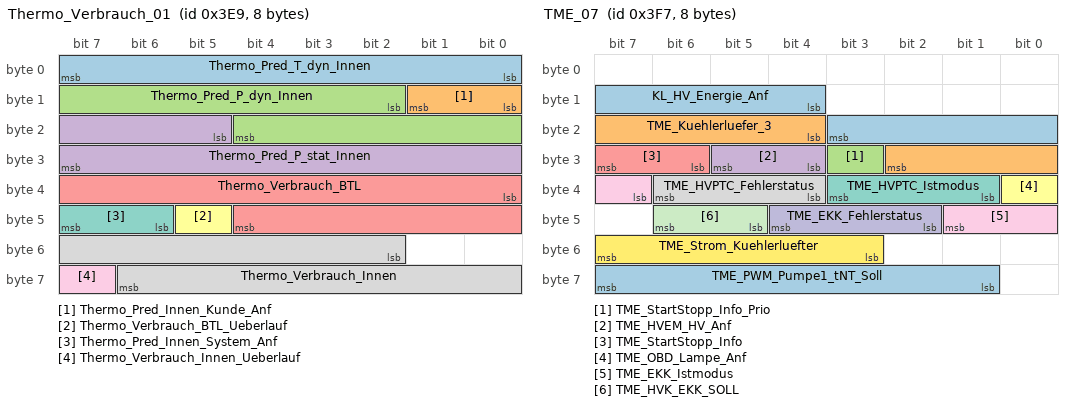
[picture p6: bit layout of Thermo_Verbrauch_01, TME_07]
BO_ 1001 Thermo_Verbrauch_01: 8 TME
 SG_ Thermo_Pred_T_dyn_Innen : 0|8@1+ (1,0) [0|253] "Unit_Minut"  Gateway,Gateway_PAG
 SG_ Thermo_Pred_Innen_Kunde_Anf : 8|2@1+ (1,0) [0|3] "Unit_None"  Gateway,Gateway_PAG
 SG_ Thermo_Pred_P_dyn_Innen : 10|11@1+ (10,0) [0|20450] "Unit_Watt"  Gateway,Gateway_PAG
 SG_ Thermo_Pred_P_stat_Innen : 21|11@1+ (10,0) [0|20450] "Unit_Watt"  Gateway,Gateway_PAG
 SG_ Thermo_Verbrauch_BTL : 32|13@1+ (1,0) [0|8191] "Unit_WattSecond"  Gateway,Gateway_PAG
 SG_ Thermo_Verbrauch_BTL_Ueberlauf : 45|1@1+ (1,0) [0|1] ""  Gateway,Gateway_PAG
 SG_ Thermo_Pred_Innen_System_Anf : 46|2@1+ (1,0) [0|3] "Unit_None"  Gateway,Gateway_PAG
 SG_ Thermo_Verbrauch_Innen : 50|13@1+ (1,0) [0|8191] "Unit_WattSecond"  Gateway,Gateway_PAG
 SG_ Thermo_Verbrauch_Innen_Ueberlauf : 63|1@1+ (1,0) [0|1] ""  Gateway,Gateway_PAG

BO_ 1015 TME_07: 8 TME
 SG_ KL_HV_Energie_Anf : 12|8@1+ (50,0) [0|12600] "Unit_WattHour"  Gateway,Gateway_PAG,Ladegeraet_Konzern
 SG_ TME_Kuehlerluefer_3 : 20|7@1+ (1,0) [0|100] "Unit_PerCent"  Gateway,Gateway_PAG
 SG_ TME_StartStopp_Info_Prio : 27|1@1+ (1,0) [0|1] ""  Gateway,Gateway_PAG
 SG_ TME_HVEM_HV_Anf : 28|2@1+ (1,0) [0|3] ""  Gateway,Gateway_PAG
 SG_ TME_StartStopp_Info : 30|2@1+ (1,0) [0|3] ""  Gateway,Gateway_PAG
 SG_ TME_OBD_Lampe_Anf : 32|1@1+ (1,0) [0|1] ""  Gateway,Gateway_PAG
 SG_ TME_HVPTC_Istmodus : 33|3@1+ (1,0) [0|7] ""  Gateway,Gateway_PAG
 SG_ TME_HVPTC_Fehlerstatus : 36|3@1+ (1,0) [0|7] ""  Gateway,Gateway_PAG
 SG_ TME_EKK_Istmodus : 39|3@1+ (1,0) [0|7] ""  Gateway,Gateway_PAG
 SG_ TME_EKK_Fehlerstatus : 42|3@1+ (1,0) [0|7] ""  Gateway,Gateway_PAG
 SG_ TME_HVK_EKK_SOLL : 45|2@1+ (1,0) [0|3] ""  Gateway,Gateway_PAG
 SG_ TME_Strom_Kuehlerluefter : 51|5@1+ (5,0) [0|145] "Unit_Amper"  Gateway,Gateway_PAG
 SG_ TME_PWM_Pumpe1_tNT_Soll : 57|7@1+ (1,0) [0|100] "Unit_PerCent"  BMC_MLBevo,Gateway,Gateway_PAG

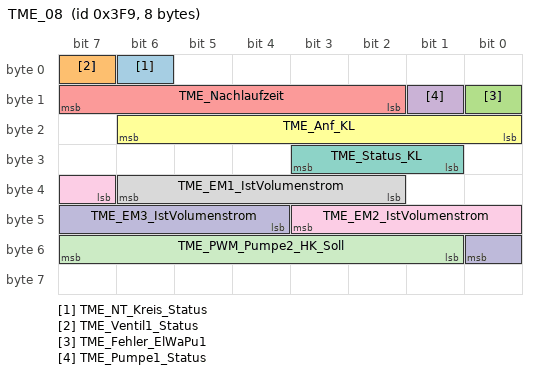
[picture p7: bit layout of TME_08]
BO_ 1017 TME_08: 8 TME
 SG_ TME_NT_Kreis_Status : 6|1@1+ (1,0) [0|1] ""  DCDC_800V_PAG,DCDC_HV,Gateway,Gateway_PAG,LE1,LE2,LE_MLBevo
 SG_ TME_Ventil1_Status : 7|1@1+ (1,0) [0|1] ""  Gateway,Gateway_PAG
 SG_ TME_Fehler_ElWaPu1 : 8|1@1+ (1,0) [0|1] ""  Gateway,Gateway_PAG
 SG_ TME_Pumpe1_Status : 9|1@1+ (1,0) [0|1] ""  Gateway,Gateway_PAG
 SG_ TME_Nachlaufzeit : 10|6@1+ (15,0) [15|945] "Unit_Secon"  Gateway,Gateway_PAG
 SG_ TME_Anf_KL : 16|7@1+ (1,0) [0|100] "Unit_PerCent"  Gateway,Gateway_PAG
 SG_ TME_Status_KL : 25|3@1+ (1,0) [0|7] ""  Gateway,Gateway_PAG
 SG_ TME_EM1_IstVolumenstrom : 34|5@1+ (0.5,0) [0|14.5] "Unit_LiterPerMinut"  Gateway,Gateway_PAG
 SG_ TME_EM2_IstVolumenstrom : 39|5@1+ (0.5,0) [0|14.5] "Unit_LiterPerMinut"  Gateway,Gateway_PAG
 SG_ TME_EM3_IstVolumenstrom : 44|5@1+ (0.5,0) [0|14.5] "Unit_LiterPerMinut"  Gateway,Gateway_PAG
 SG_ TME_PWM_Pumpe2_HK_Soll : 49|7@1+ (1,0) [0|100] "Unit_PerCent"  Gateway,Gateway_PAG

BO_TX_BU_ 1635 : Gateway,Gateway_PAG;
BO_TX_BU_ 869 : Gateway,Gateway_PAG;
BO_TX_BU_ 2527679508 : Gateway,Gateway_PAG;
BO_TX_BU_ 2527679509 : Gateway,Gateway_PAG;
BO_TX_BU_ 527 : Gateway,Gateway_PAG;
BO_TX_BU_ 913 : Gateway,Gateway_PAG;
BO_TX_BU_ 2549875343 : Gateway,Gateway_PAG;
BO_TX_BU_ 2549875374 : Gateway,Gateway_PAG;
BO_TX_BU_ 2549875356 : Gateway,Gateway_PAG;
BO_TX_BU_ 2549875399 : Gateway,Gateway_PAG;
BO_TX_BU_ 2549875383 : Gateway,Gateway_PAG;
BO_TX_BU_ 2550006455 : DCDC_800V_PAG,DCDC_HV;
BO_TX_BU_ 2549875265 : Gateway,Gateway_PAG;
BO_TX_BU_ 2549940736 : Gateway,Gateway_PAG;
BO_TX_BU_ 2549875323 : Gateway,Gateway_PAG;
BO_TX_BU_ 2549875398 : Gateway,Gateway_PAG;
BO_TX_BU_ 2549875268 : Gateway,Gateway_PAG;
BO_TX_BU_ 2549903568 : Gateway,Gateway_PAG;
BO_TX_BU_ 2549903569 : Gateway,Gateway_PAG;
BO_TX_BU_ 2549903570 : Gateway,Gateway_PAG;
BO_TX_BU_ 2549903571 : Gateway,Gateway_PAG;
BO_TX_BU_ 2549903572 : Gateway,Gateway_PAG;
BO_TX_BU_ 2549903573 : Gateway,Gateway_PAG;
BO_TX_BU_ 2549903574 : Gateway,Gateway_PAG;
BO_TX_BU_ 2549903575 : Gateway,Gateway_PAG;
BO_TX_BU_ 2549903576 : Gateway,Gateway_PAG;
BO_TX_BU_ 2549903577 : Gateway,Gateway_PAG;
BO_TX_BU_ 2549903578 : Gateway,Gateway_PAG;
BO_TX_BU_ 2549903579 : Gateway,Gateway_PAG;
BO_TX_BU_ 2549903580 : Gateway,Gateway_PAG;
BO_TX_BU_ 2549903601 : Gateway,Gateway_PAG;
BO_TX_BU_ 2549903602 : Gateway,Gateway_PAG;
BO_TX_BU_ 2549903603 : Gateway,Gateway_PAG;
BO_TX_BU_ 2549875266 : Gateway,Gateway_PAG;
BO_TX_BU_ 2589283656 : Gateway,Gateway_PAG;
BO_TX_BU_ 872 : Gateway,Gateway_PAG;
BO_TX_BU_ 2463978617 : Gateway,Gateway_PAG;
BO_TX_BU_ 1175 : Gateway,Gateway_PAG;
BO_TX_BU_ 1355 : Gateway,Gateway_PAG;
BO_TX_BU_ 617 : Gateway,Gateway_PAG;
BO_TX_BU_ 2550007876 : Gateway,Gateway_PAG;
BO_TX_BU_ 1616 : Gateway,Gateway_PAG;
BO_TX_BU_ 1525 : Gateway,Gateway_PAG;
BO_TX_BU_ 1527 : Gateway,Gateway_PAG;
BO_TX_BU_ 1126 : Gateway,Gateway_PAG;
BO_TX_BU_ 2527679792 : Gateway,Gateway_PAG;
BO_TX_BU_ 1313 : Gateway,Gateway_PAG;
BO_TX_BU_ 505 : Gateway,Gateway_PAG;
CM_ BO_ 2600468546 "CAN_NM_PDU MLBevo";
CM_ SG_ 2600468546 NM_TME_SNI "Source Node-Identifier (SNI) identifiziert den Sender der NM-Botschaft (Knotenadresse) eindeutig im Fahrzeug";
CM_ SG_ 2600468546 NM_TME_CBV_AWB "Das Signal ist zu setzen, wenn das SG aktiv den Bus geweckt hat";
CM_ SG_ 2600468546 NM_TME_CBV_CRI "Das Signal ist dauerhaft gesetzt, wenn das NM-Layout dem neuen NM-Layout für Teilnetzbetrieb entspricht";
CM_ SG_ 2600468546 NM_TME_NM_State "1 = Zustand Repeat Message (<-- Bus-Sleep Mode)
2 = Zustand Repeat Message (<-- Prepare Bus-Sleep Mode)
4 = Zustand Normal Operation (<-- Repeat Message)
8 = Zustand Normal Operation (<-- Ready Sleep)
16 = Zustand Repeat Message (<-- Ready Sleep)
32 ";
CM_ SG_ 2600468546 NM_TME_Car_Wakeup "Car Wakeup (Gateway wertet aus)";
CM_ SG_ 2600468546 NM_TME_UDS_CC "Funktionseinschränkung aufgrund aktivem UDS-Communication Control; siehe VW80124";
CM_ SG_ 2600468546 NM_TME_NM_aktiv_KL15 "Steuergerät hat KL15-EIN erkannt";
CM_ SG_ 2600468546 NM_TME_NM_aktiv_Diagnose "Diagnose befindet sich nach VW80124 in einer NonDefaultDiagnostic-Session, z.B. ExtendedDiagnostic-Session";
CM_ SG_ 2600468546 NM_TME_NM_aktiv_Tmin "Mindestaktivzeit ist noch nicht abgelaufen (bei jedem Weckereignis wird die Mindestaktivzeit neu gestartet)";
CM_ SG_ 2600468546 NM_TME_NM_aktiv_Berechnung "Berechnung für Vorkonditionierung aktiv";
CM_ SG_ 2600468546 NM_TME_NM_aktiv_Vorkondition "Vorkonditionierung aktiv";
CM_ SG_ 2600468546 NM_TME_NM_aktiv_HV_Auszeitber "Nachlauf aufgrund HV Auszeitberechnung ";
CM_ SG_ 2600468546 NM_TME_NM_aktiv_Ventilsteuerung "Ventilsteuerung vor Abschaltung";
CM_ SG_ 2600468546 NM_TME_NM_aktiv_Kuehlung "Nachlaufkühlung der E-Maschinen";
CM_ SG_ 2600468546 NM_TME_CAB "CAB = Clusteraktivbits";
CM_ BO_ 1635 "DLC=8 ab D4 gültig";
CM_ SG_ 1635 BEM_02_Abschaltstufen "Abschaltstufen des Ruhestrommanagements (Initialisierungswert aus EEprom)

Stufe 0 (keine Einschraenkungen)
Stufe 1 (Abschaltung Hochstromverbraucher)
Stufe 2 (Infotainmentabschaltung)
Stufe 3 (Wake-Up-Sperre)

Für den Transport- und Ruhestrommessm";
CM_ SG_ 1635 BEM_STH_Zielzeit "Maximal mögliche Zeit für den Standheizungsbetrieb, um die Startfähigkeit nicht zu gefährden";
CM_ SG_ 1635 BEM_MMI_Vorwarnung "Anzeige Vorwarnung MMI-Abschaltung (Initialisierungswert aus EEprom)
";
CM_ SG_ 1635 NVEM_Anf_SD_schalten "Anforderung Nachlauf für den Steckdosenbetrieb
Initialisierungswert aus EEprom";
CM_ SG_ 1635 BEM_Generatordiagnose "Ansteuerung Generatorwarnleuchte im Kombi
";
CM_ SG_ 1635 BEM_Red_Innengeblaese "Reduzierung Innengebläse
";
CM_ SG_ 1635 BEM_STH_Einschaltverbot "Einschränkung Standheizung/-lüftung durch BEM: Setzt der BEM das Bit, dann darf die Standheizung nicht mehr einschalten
(Die Standheizung muss aber nicht abschalten, sondern darf weiterbrennen)
(Initialisierungswert aus EEprom)
";
CM_ SG_ 1635 BEM_HL_Regelung_Status "Status Regelung Heizleistung
";
CM_ SG_ 1635 BEM_Ladezustand "Ladezustand der Niedervoltbatterie
";
CM_ SG_ 1635 BEM_Batteriediagnose "Anzeige von Textwarnungen";
CM_ SG_ 1635 MIB_Stromsparmodus "Signal beschreibt die Aktivierung für den Stromsparmodus beim MIB.
Bei AUS (= 0) gibt es keine weitere Anforderung an die MIB-Komponenten.
Bei EIN (= 1) werden alle MIB Komponenten in einen Stromsparmodus versetzt.";
CM_ SG_ 1635 BEM_REK_aktiv "Rekuperationsfreigabe vom Energiemanagement
0x0 = keine Rekuperationsfreigabe
0x1 = Rekuperationsfreigabe";
CM_ SG_ 1635 NVEM_Last_Anf "Das NVEM fordert für die Batteriediagnose einen Lastimpuls vom Fahrzeug an, der durch kontrollierte Verbraucherzuschaltungen (z. B. Aktivierung Heckscheibenheizung) generiert wird";
CM_ SG_ 1635 BEM_UBDM "Batteriespannung, gemessen vom Batteriedatenmodul";
CM_ SG_ 1635 BEM_UGenSoll "Sollspannungsvorgabe an den Generator, beinhaltet temperaturoptimierte Batterieladung und Rekuperation";
CM_ SG_ 1635 BEM_Anf_KL15_schalten "Abschaltempfehlung bzw. Verhinderung der automatischen Abschaltung Kl15 durch das BCM";
CM_ SG_ 1635 NVEM_Batterie_Service "Anforderung einer Batterie-Service - Anzeige / Anforderung an die Werkstatt über MOD";
CM_ SG_ 1635 NVEM_Freigabe_OnlineUpdate "Freigabe für Online-Update durch Energiemanagement";
CM_ SG_ 1635 NVEM_Freigabe_ORU4 "Bestätigung oder Ablehnung eines konkreten, angefragten Online Updates durch das Energiemanagements";
CM_ BO_ 869 "ab MQB";
CM_ SG_ 869 NVEM_05_CRC "Für MLB:
Berechnung siehe Lastenheft 'Kommunikationsabsicherung für FlexRay und CAN'
Ab MQB und MLBevo:
Berechnung siehe Lastenheft 'End-to-End Kommunikationsabsicherung'

Endwerte siehe Begleitdokument 'S-PDU Kennungsfolgen'";
CM_ SG_ 869 NVEM_05_BZ "4bit Botschaftszähler, wird mit jeder Sendebotschaft inkrementiert";
CM_ SG_ 869 NVEM_Pilot_Info "NVEM Veto bei reduzierter Leistungsfähigkeit des Energienetzes";
CM_ SG_ 869 NVEM_P_Generator_Status "Das Signal kennzeichnet ob BEM_P_Generator aktuell gefilterte oder ungefilterte Werte überträgt.";
CM_ SG_ 869 BEM_P_Generator "Es gilt: Signalspec BEM_P_Generator v1.0

Mechanische Generatorleistung dient dem Motorsteuergerät zur Berechnung der Motorlast; Genauigkeit ca. +/- (500W + 20% vom Messwert)

MLBevo: Bei NVEM_P_Generator_Status = 1 wird das Signal ohne Filterung ausg";
CM_ SG_ 869 BEM_n_LLA "Es gilt: Signalspec BEM_n_LLA v1.0

Anforderung einer Leerlaufdrehzahlanhebung in drei Stufen. Die Höhe der jeweiligen LL-Drehzahlstufe ist im Motorsteuergerät appliziert.



";
CM_ SG_ 869 BEM_Anf_KL "Es gilt: Signalspec BEM_Anf_KL v1.1
Das BEM fordert über das MSG den Kühlerlüfter-Betrieb an; hierzu wird ein minimaler Leistungswert im MSG appliziert. 
Szenario: bei erkannter abgetrennten Batterie soll durch Ansteuerung des Kühlerlüfters das Energien";
CM_ SG_ 869 BEM_StartStopp_Info "Stopp-Freigabe und Start-Anforderung an den Start-Stopp-Koordinator";
CM_ SG_ 869 BEM_DFM "Generatorauslastungsgrad, vom Generator über LIN an das Gateway gesandt. Das Motorsteuergerät regelt auf dieses Signal die PTC, das Energiemanagement im BSG/BCM kalkuliert die Bordnetzauslastung";
CM_ SG_ 869 BEM_Batt_Ab "Batterieverbindungskontrolle:
0x0: Batterie am Bordnetz
0x1: Batterie ab erkannt";
CM_ SG_ 869 BEM_Hybrid_Info "Einschränkung des Hybridbetriebs durch Energiemanagement
0 = keine Einschränkung des Hybridbetriebs durch das Energiemanagement [Hybridfreigabe]
1 = Motorstart über 12V-Starter nur bei v = 0 km/h möglich
2 = kein Motorstart über 12V-Starter nach elektr";
CM_ SG_ 869 NVEM_Red_KL "Reduzierung der Kühlerlüfteranforderung durch das NVEM an das MSG bei energetisch kritischen Zuständen während Staupilot";
CM_ SG_ 869 NVEM_Freilauf_Info "Freilauf Informationssignal vom NVEM zum Freilaufkoordinator. Das NVEM kann über dieses Signal den Freilauf freigeben, verhindern bzw. explizit anfordern.";
CM_ SG_ 869 BEM_HYB_DC_uSollLV "Sollwert für die Bordnetzspannung im Tiefsetzbetrieb vom Traktionsnetz ins Bordnetz (Hybrid)";
CM_ SG_ 869 BEM_HYB_DC_uMinLV "Abregelgrenze: minimal erlaubte Bordnetzspannung im Hochsetzbetrieb (Hybrid)";
CM_ SG_ 2527679508 NVEM_06_CRC "Für MLB:
'Berechnung siehe Lastenheft 'Kommunikationsabsicherung für FlexRay und CAN''

Ab MQB und MLBevo:
'Berechnung siehe Lastenheft 'End-to-End Kommunikationsabsicherung''

Endwerte siehe Begleitdokument 'S-PDU Kennungsfolgen'";
CM_ SG_ 2527679508 NVEM_06_BZ "4bit Botschaftszähler, wird mit jeder Sendebotschaft inkrementiert";
CM_ SG_ 2527679508 NVEM_Max_Rampenzeit "Vorgabe der max. Rampenzeit für den Generatorbetrieb des 12V-RSG (RSG-Ansteuerung durch Motor-SG)";
CM_ SG_ 2527679508 NVEM_Min_Spannung "Mild_Hybrid: erforderliche Mindestspannung 12V - Netz";
CM_ SG_ 2527679508 NVEM_Min_Spannung_Start "Minimale einzuhaltende Spannung im RSG Wiederstart";
CM_ SG_ 2527679508 NVEM_Max_Spannung "Mild_Hybrid: erlaubte Maximalspannung 12V - Netz
";
CM_ SG_ 2527679508 NVEM_Energie_Klima_Vorgabe "NVEM-Energievorgabe für Klima-Vorkonditionierung";
CM_ SG_ 2527679508 NVEM_MV_DC_uMinLV "Abregelgrenze: minimal erlaubte Bordnetzspannung im Hochsetzbetrieb vom 12V-Bordnetz ins 48V-Netz";
CM_ SG_ 2527679508 NVEM_MV_DC_uSollLV "Sollwert für die 12V-Bordnetzspannung im Tiefsetzbetrieb vom 48V-Netz ins 12V-Bordnetz";
CM_ SG_ 2527679508 NVEM_Bordnetzdiagnose "Wird vom NVEM im NV-Netz ein Bordnetz-Fehler erkannt, so soll dies zu einer mehrstufigen Anzeige führen.";
CM_ SG_ 2527679509 NVEM_07_CRC "Für MLB:
'Berechnung siehe Lastenheft 'Kommunikationsabsicherung für FlexRay und CAN''

Ab MQB und MLBevo:
'Berechnung siehe Lastenheft 'End-to-End Kommunikationsabsicherung''

Endwerte siehe Begleitdokument 'S-PDU Kennungsfolgen'";
CM_ SG_ 2527679509 NVEM_07_BZ "Fortlaufender Botschaftszaehler";
CM_ SG_ 2527679509 NVEM_BMS_NV_Imax_RSG_Anf "prädizierter RSG-Verbrauchsstrom während des 12V-Zustarts";
CM_ SG_ 2527679509 NVEM_BMS_NV_Umin_RSG_Anf "erforderliche Mindestspannung beim RSG-Zustart für die Berechnung des Signals BMS_NV_Qe_Li_Inhalt";
CM_ SG_ 2527679509 NVEM_BMS_NV_Nachlaufzeit_Vorgabe "Zeitvorgabe bis zum Öffnen des Trennelements";
CM_ SG_ 2527679509 NVEM_BMS_NV_Umin_Anf "erforderliche Mindestspannung für die Berechnung des Signals BMS_NV_Qe_Li_Inhalt";
CM_ SG_ 2527679509 NVEM_FMAus_I_Verbrauch "Predezierter Bordneztstromverbrauch während der Freilauf Motor Aus Phase.";
CM_ SG_ 2527679509 NVEM_BMS_NV_Impuls_Abfrage "Trigger zur Lieferung aktueller Daten und Initialisierung der Schleppzeiger für die Signale UMinStart und IMaxStart.";
CM_ SG_ 2527679509 NVEM_BMS_NV_Sollmodus "Anforderung Trennelement oeffnen/ schliessen";
CM_ SG_ 527 NVEM_DC_uSoll_NV "Sollspannung 12V Seite des DC Wandlers, feine Auflösung";
CM_ SG_ 913 OBD_Calc_Load_Val "Calculated Load Value

Übertragung von Meßgrößen an das Getriebesteuergerät für Freeze Frame Abspeicherung bei Getriebefehlern

PID $04 Calculated Load Value; 0 .. 100% mit 100/255 % per bit
";
CM_ SG_ 913 OBD_Eng_Cool_Temp "Engine Coolant Temperature

Übertragung von Meßgrößen an das Getriebesteuergerät für Freeze Frame Abspeicherung bei Getriebefehlern

PID $05 Engine Coolant Temperature; -40 .. +215°C mit 1°C/bit und 40°C Offset";
CM_ SG_ 913 OBD_Abs_Throttle_Pos "Absolute Throttle Position

Übertragung von Meßgrößen an das Getriebesteuergerät für Freeze Frame Abspeicherung bei Getriebefehlern

PID $11 Absolute Throttle Position; 0 .. 100% mit 100/255 %/bit";
CM_ SG_ 913 OBD_Abs_Load_Val "Absolute Load Value

Übertragung von Meßgrößen an das Getriebesteuergerät für Freeze Frame Abspeicherung bei Getriebefehlern

PID $43 Absolute Load Value; 0 .. 25700%  mit 100/255 %/bit";
CM_ SG_ 913 OBD_Abs_Pedal_Pos "Absolute Pedal Position

Übertragung von Meßgrößen an das Getriebesteuergerät für Freeze Frame Abspeicherung bei Getriebefehlern

PID $49 Accelerator Pedal Position D; 0 .. 100% mit 100/255 %/bit";
CM_ SG_ 913 MO_Servicemodus "Ausgabe aktiver Service-Mode";
CM_ SG_ 913 OBD_ClearMem_Inhibit "Bei FSP_Loeschen_zulässig müssen alle OBD-ECUs im Gesamtfahrzeug einen Service 04hex Request (Ereignisspeicher löschen) korrekt ausführen. 

In MLB-, MLBevo-, MQB-Fahrzeugkonzepten muss der MIL-Master/Motorsteuergerät bei Kl.15 ein, projektabhängig, kon";
CM_ SG_ 913 OBD_Sperrung_Kaltstart_Denom "Information vom MIL Master, dass die Bildung des EVAP Denominators  im Motor nicht möglich ist und damit der noECM-Denominator gesperrt werden darf.";
CM_ SG_ 913 MO_QBit_Aussen_Temp "QBit der Aussentemperatur. Gesetzt bei Ersatzwert, Init oder Fehler.";
CM_ SG_ 913 OBD_Sperrung_IUMPR "Wenn der General Denominator auf Grund eines Fehlers in den Eingangsgrößen gesperrt wird, wird diese Information über Bussystem als OBD-Statusinformation OBD_Sperrung_IUMPR für andere OBD-Steuergeräte bereitgestellt. 

Das MSG (MIL-Master) setzt dieses ";
CM_ SG_ 913 OBD_Kaltstart_Denominator "Bestimmte Diagnosen werden nur unter Kaltstartbedingungen durchgeführt, der entsprechende Denominator bei IUMPR-pflichtigen Systemen wird anhand dieses vom MSG gebildeten Signals inkrementiert. (Entspricht EVAP-Denominator)";
CM_ SG_ 913 OBD_Minimum_Trip "Grundlage OBD-Gesetz CCR 1968.2 (d)(4.3) Denominator Specifications
Bildung des General Denominator 'Normed Trip':
 600 sec. (kumulativ) Zeit nach Motorstart
 300 sec. (kumulativ) mit Fahrzeuggeschwindigkeit > 25 mph (40 km/h)
 30 sec. (kontinuierlich";
CM_ SG_ 913 OBD_Warm_Up_Cycle "Mit dem Warm-Up-Cycle wird der zentrale Verlernzähler vom Gateway inkrementiert";
CM_ SG_ 913 OBD_Normed_Trip "Gesetzlich definierte 'Normed Condition' erfüllt, 'General Denominator' darf erhöht werden";
CM_ SG_ 2549875399 OBDC_DCDC_HV_02_Req_Data "TP-Kanal für den Onboard Datensammler";
CM_ SG_ 2550006471 OBDC_DCDC_HV_02_Resp_Data "TP-Kanal für den Onboard Datensammler";
CM_ SG_ 2549875407 OBDC_DCDC_HV_03_Req_Data "TP-Kanal für den Onboard Datensammler";
CM_ SG_ 2550006479 OBDC_DCDC_HV_03_Resp_Data "TP-Kanal für den Onboard Datensammler";
CM_ SG_ 2549875383 OBDC_DCDC_HV_Req_Data "TP-Kanal für den Onboard Datensammler";
CM_ SG_ 2550006455 OBDC_DCDC_HV_Resp_Data "TP-Kanal für den Onboard Datensammler";
CM_ SG_ 2549875265 OBDC_DCDC_Req_Data "TP-Kanal für den Onboard Datensammler";
CM_ SG_ 2550006337 OBDC_DCDC_Resp_Data "TP-Kanal für den Onboard Datensammler";
CM_ SG_ 2549875381 OBDC_FCU_Req_Data "TP-Kanal für den Onboard Datensammler";
CM_ SG_ 2550006453 OBDC_FCU_Resp_Data "TP-Kanal für den Onboard Datensammler";
CM_ BO_ 2549940736 "VDC funktionaler Request auf CANHS";
CM_ SG_ 2549940736 OBDC_Funktionaler_Req_All_Data "VDC funktionaler Request auf CANHS";
CM_ SG_ 2549875398 OBDC_Ladegeraet_2_Req_Data "TP-Kanal für den Onboard Datensammler";
CM_ SG_ 2550006470 OBDC_Ladegeraet_2_Resp_Data "TP-Kanal für den Onboard Datensammler";
CM_ SG_ 2549903568 OBDC_SSN_BJB_Req_Data "Request FID- zu NA- Kommunikation zw. OnboardDiagnoseClient und DK2F Sub-System-Knoten BJB";
CM_ SG_ 2550034640 OBDC_SSN_BJB_Resp_Data "Response FID- zu NA- Kommunikation zw. OnboardDiagnoseClient und DK2F Sub-System-Knoten BJB";
CM_ SG_ 2549903569 OBDC_SSN_CMC_01_Req_Data "Request FID- zu NA- Kommunikation zw. OnboardDiagnoseClient und DK2F Sub-System-Knoten CMC_01 ... 16";
CM_ SG_ 2550034641 OBDC_SSN_CMC_01_Resp_Data "Response FID- zu NA- Kommunikation zw. OnboardDiagnoseClient und DK2F Sub-System-Knoten CMC_01 ... 16";
CM_ SG_ 2549903570 OBDC_SSN_CMC_02_Req_Data "Request FID- zu NA- Kommunikation zw. OnboardDiagnoseClient und DK2F Sub-System-Knoten CMC_01 ... 16";
CM_ SG_ 2550034642 OBDC_SSN_CMC_02_Resp_Data "Response FID- zu NA- Kommunikation zw. OnboardDiagnoseClient und DK2F Sub-System-Knoten CMC_01 ... 16";
CM_ SG_ 2549903571 OBDC_SSN_CMC_03_Req_Data "Request FID- zu NA- Kommunikation zw. OnboardDiagnoseClient und DK2F Sub-System-Knoten CMC_01 ... 16";
CM_ SG_ 2550034643 OBDC_SSN_CMC_03_Resp_Data "Response FID- zu NA- Kommunikation zw. OnboardDiagnoseClient und DK2F Sub-System-Knoten CMC_01 ... 16";
CM_ SG_ 2549903572 OBDC_SSN_CMC_04_Req_Data "Request FID- zu NA- Kommunikation zw. OnboardDiagnoseClient und DK2F Sub-System-Knoten CMC_01 ... 16";
CM_ SG_ 2550034644 OBDC_SSN_CMC_04_Resp_Data "Response FID- zu NA- Kommunikation zw. OnboardDiagnoseClient und DK2F Sub-System-Knoten CMC_01 ... 16";
CM_ SG_ 2549903573 OBDC_SSN_CMC_05_Req_Data "Request FID- zu NA- Kommunikation zw. OnboardDiagnoseClient und DK2F Sub-System-Knoten CMC_01 ... 16";
CM_ SG_ 2550034645 OBDC_SSN_CMC_05_Resp_Data "Response FID- zu NA- Kommunikation zw. OnboardDiagnoseClient und DK2F Sub-System-Knoten CMC_01 ... 16";
CM_ SG_ 2549903574 OBDC_SSN_CMC_06_Req_Data "Request FID- zu NA- Kommunikation zw. OnboardDiagnoseClient und DK2F Sub-System-Knoten CMC_01 ... 16";
CM_ SG_ 2550034646 OBDC_SSN_CMC_06_Resp_Data "Response FID- zu NA- Kommunikation zw. OnboardDiagnoseClient und DK2F Sub-System-Knoten CMC_01 ... 16";
CM_ SG_ 2549903575 OBDC_SSN_CMC_07_Req_Data "Request FID- zu NA- Kommunikation zw. OnboardDiagnoseClient und DK2F Sub-System-Knoten CMC_01 ... 16";
CM_ SG_ 2550034647 OBDC_SSN_CMC_07_Resp_Data "Response FID- zu NA- Kommunikation zw. OnboardDiagnoseClient und DK2F Sub-System-Knoten CMC_01 ... 16";
CM_ SG_ 2549903576 OBDC_SSN_CMC_08_Req_Data "Request FID- zu NA- Kommunikation zw. OnboardDiagnoseClient und DK2F Sub-System-Knoten CMC_01 ... 16";
CM_ SG_ 2550034648 OBDC_SSN_CMC_08_Resp_Data "Response FID- zu NA- Kommunikation zw. OnboardDiagnoseClient und DK2F Sub-System-Knoten CMC_01 ... 16";
CM_ SG_ 2549903577 OBDC_SSN_CMC_09_Req_Data "Request FID- zu NA- Kommunikation zw. OnboardDiagnoseClient und DK2F Sub-System-Knoten CMC_01 ... 16";
CM_ SG_ 2550034649 OBDC_SSN_CMC_09_Resp_Data "Response FID- zu NA- Kommunikation zw. OnboardDiagnoseClient und DK2F Sub-System-Knoten CMC_01 ... 16";
CM_ SG_ 2549903578 OBDC_SSN_CMC_10_Req_Data "Request FID- zu NA- Kommunikation zw. OnboardDiagnoseClient und DK2F Sub-System-Knoten CMC_01 ... 16";
CM_ SG_ 2550034650 OBDC_SSN_CMC_10_Resp_Data "Response FID- zu NA- Kommunikation zw. OnboardDiagnoseClient und DK2F Sub-System-Knoten CMC_01 ... 16";
CM_ SG_ 2549903579 OBDC_SSN_CMC_11_Req_Data "Request FID- zu NA- Kommunikation zw. OnboardDiagnoseClient und DK2F Sub-System-Knoten CMC_01 ... 16";
CM_ SG_ 2550034651 OBDC_SSN_CMC_11_Resp_Data "Response FID- zu NA- Kommunikation zw. OnboardDiagnoseClient und DK2F Sub-System-Knoten CMC_01 ... 16";
CM_ SG_ 2549903580 OBDC_SSN_CMC_12_Req_Data "Request FID- zu NA- Kommunikation zw. OnboardDiagnoseClient und DK2F Sub-System-Knoten CMC_01 ... 16";
CM_ SG_ 2550034652 OBDC_SSN_CMC_12_Resp_Data "Response FID- zu NA- Kommunikation zw. OnboardDiagnoseClient und DK2F Sub-System-Knoten CMC_01 ... 16";
CM_ SG_ 2549903601 OBDC_SSN_CMC_13_Req_Data "Request FID- zu NA- Kommunikation zw. OnboardDiagnoseClient und DK2F Sub-System-Knoten CMC_01 ... 16";
CM_ SG_ 2550034673 OBDC_SSN_CMC_13_Resp_Data "Response FID- zu NA- Kommunikation zw. OnboardDiagnoseClient und DK2F Sub-System-Knoten CMC_01 ... 16";
CM_ SG_ 2549903602 OBDC_SSN_CMC_14_Req_Data "Request FID- zu NA- Kommunikation zw. OnboardDiagnoseClient und DK2F Sub-System-Knoten CMC_01 ... 16";
CM_ SG_ 2550034674 OBDC_SSN_CMC_14_Resp_Data "Response FID- zu NA- Kommunikation zw. OnboardDiagnoseClient und DK2F Sub-System-Knoten CMC_01 ... 16";
CM_ SG_ 2549903603 OBDC_SSN_CMC_15_Req_Data "Request FID- zu NA- Kommunikation zw. OnboardDiagnoseClient und DK2F Sub-System-Knoten CMC_01 ... 16";
CM_ SG_ 2550034675 OBDC_SSN_CMC_15_Resp_Data "Response FID- zu NA- Kommunikation zw. OnboardDiagnoseClient und DK2F Sub-System-Knoten CMC_01 ... 16";
CM_ SG_ 2549875380 OBDC_TelemetrieSG_Req_Data "TP-Kanal für den Onboard Datensammler";
CM_ SG_ 2550006452 OBDC_TelemetrieSG_Resp_Data "TP-Kanal für den Onboard Datensammler";
CM_ SG_ 2589283656 ORU_Warnung "Wenn durch Störungen der Funktion Online Remote Update nicht sichergestellt ist, dass vor Kunde keine Funktionseinschränkungen auftreten, muss der Benutzer des Fahrzeugs entsprechend gewarnt werden.";
CM_ SG_ 2589283656 ORU_Status "Broadcast des Status der Konzernfunktion Online Remote Update";
CM_ SG_ 872 PH2_Visualisierung "Signal zeigt den Partnersteuergeräten RearView/TopView/ARA/... den aktuellen Status der Visualisierung des OPS. Die Partnersteuergeräte können dadurch auch ihre Aufschaltung an dieses Signal koppeln.";
CM_ SG_ 872 PDC2_Tonausgabe_Front "In Abhängigkeit der Systemaktivitäten werden unterschiedliche Tonwarnungen ausgegeben. 
Kombi spielt entsprechende WAV.-Datei über internen Audiomaster ab.

0 = kein Ton
1 = Intervallton 1
2 = Intervallton 2
3 = Intervallton 3
4 = Intervallton 4
5";
CM_ SG_ 872 PDC2_Tonausgabe_Heck "In Abhängigkeit der Systemaktivitäten werden unterschiedliche Tonwarnungen ausgegeben. 
Kombi spielt entsprechende WAV.-Datei über internen Audiomaster ab.

0 = kein Ton
1 = Intervallton 1
2 = Intervallton 2
3 = Intervallton 3
4 = Intervallton 4
5";
CM_ SG_ 872 PH2_nachtr_Stopp_An "Dieses Signal dient dem Motor als Trigger, dass ein nachträglicher Motorstopp eingeleitet werden kann, wenn es die Bedingungen des StSt Koordinators dies zulassen. ";
CM_ SG_ 872 PH2_Abschaltursache "Abschaltursache bleibt bis zur nächsten Aktivierung bzw. bis KL15 aus gesetzt
Im Fehlerfall (blinkende LED) wird '7' gesendet obwohl das System noch aktiv ist, bei 'geheiltem' Fehler wird sofort wieder der Zustand '0' gesendet";
CM_ SG_ 872 PH2_Opt_Anzeige_V_ein "OPS vorne ist im Display aktiv bzw. Anzeigemodule vorne sind eingeschaltet. Funktion nur bei gesicherter Rückmeldung vom ASG gegeben.";
CM_ SG_ 872 PH2_Opt_Anzeige_H_ein "OPS hinten ist im Display aktiv bzw. Anzeigemodule hinten sind eingeschaltet. Funktion nur bei gesicherter Rückmeldung vom ASG gegeben.";
CM_ SG_ 872 PH2_Opt_Anz_V_Hindernis "mindestens 1 Segment wird für den vorderen Detekionsbereich dargestellt, also ein Hindernis ist im Detektionsbereich. Funktion nur bei gesicherter Rückmeldung vom ASG gegeben.";
CM_ SG_ 872 PH2_Opt_Anz_H_Hindernis "mindestens 1 Segment wird für den hinteren Detekionsbereich dargestellt, also ein Hindernis ist im Detektionsbereich. Funktion nur bei gesicherter Rückmeldung vom ASG gegeben.";
CM_ SG_ 872 PH2_Tongeber_V_aktiv "Rohsignal für 'Tongeber vorne wird angesteuert', verlängerbar mit Nachlauftimer.
Bit wird nicht während des Stellgliedtests angesteuert.";
CM_ SG_ 872 PH2_Tongeber_H_aktiv "Rohsignal für 'Tongeber hinten wird angesteuert', verlängerbar mit Nachlauftimer.
Bit wird nicht während des Stellgliedtests angesteuert.";
CM_ SG_ 872 PH2_Tongeber_mute "Die Akustikausgabe des Systems wird unterdrückt, z.B. Wählhebel in 'P', Parlbremse geschlossen (8-Kanal-System)";
CM_ SG_ 872 PH2_Anf_Audioabsenkung "Es gibt zwei unterschiedliche Nachlauftimer für dieses Bit:
1. normale Funktion
2. Demotonausgabe";
CM_ SG_ 872 PH2_Tongeber_H_verfuegbar "Tongeber ist für die Tonausgabe für externe Funktionen verfügbar. PDC ist aktiv und Tongeber ist nicht gestört.";
CM_ SG_ 872 PH2_Taster "Taster Status (für RVC/TopView)";
CM_ SG_ 872 PH2_Anf_Verdeck "Anforderung an ein Verdeck-System, die vom Fahrer angeforderte Öffnung/Schließung zu verhindern";
CM_ SG_ 872 PH2_Frequenz_hinten "Uebertragung der aktuell im APS Steuergeraet gespeicherten Werte fuer Tongeber Frequenz hinten
Anzeige der aktuell verwendeten Parameter (nicht zwingend die abgespeicherten - da Werte erst 2s nach der letzten Änderung gespeichert werden!)";
CM_ SG_ 872 PH2_Lautstaerke_hinten "Uebertragung der aktuell im APS Steuergeraet gespeicherten Werte fuer Tongeber Lautstaerke hinten
Anzeige der aktuell verwendeten Parameter (nicht zwingend die abgespeicherten - da Werte erst 2s nach der letzten Änderung gespeichert werden!)";
CM_ SG_ 872 PH2_Frequenz_vorn "Uebertragung der aktuell im APS Steuergeraet gespeicherten Werte fuer Tongeber Frequenz vorne
Anzeige der aktuell verwendeten Parameter (nicht zwingend die abgespeicherten - da Werte erst 2s nach der letzten Änderung gespeichert werden!)";
CM_ SG_ 872 PH2_Lautstaerke_vorn "Uebertragung der aktuell im APS Steuergeraet gespeicherten Werte fuer Tongeber Lautstaerke vorn.
Anzeige der aktuell verwendeten Parameter (nicht zwingend die abgespeicherten - da Werte erst 2s nach der letzten Änderung gespeichert werden!)";
CM_ SG_ 872 PH2_StartStopp_Info "Stopp-Freigabe und Start-Anforderung an den Start-Stopp-Koordinator";
CM_ SG_ 872 PH2_Stoermeldung "Meldung einer Störung der PDC an das Kombi";
CM_ SG_ 872 PH2_defekt "Zeigt an das sich die Parkhilfe im Fehlerzustand befindet. Signal bleibt bis zur nächsten 'Gut-Aktivierung' gesetzt.
Spezialfall: Sensordefekt hinten bei Anhängerbetrieb. Anhänger wird abgesteckt Fehler wird gesetzt. Fehlerfall bleibt bis Behebung des De";
CM_ SG_ 872 PH2_gestoert "Eine Störung ist aufgetreten, der die Parkhilfe in einen 'gestört-Zustand' versetzt, z.B. massiver Fremdultraschall, Vereisung, Schnee.Derzeit nur für Störschall benutzt, da keinerlei andere Erkennung implementiert.";
CM_ SG_ 872 PH2_Systemzustand "Aktivierungsursache wird für die Dauer der Aktivierung gemeldet.
Im Fehlerfall bei atkviem System wechselt das Signal auf '7'
(siehe auch 'Abschaltursache')";
CM_ SG_ 872 PH2_Display_Kundenwunsch "Anzeige der bei Aktivierung verwendeten Parameter bzgl. Kundenwunsch Displayanziege. Änderungen werden erst bei erneuter Aktivierung aktualisiert.";
CM_ SG_ 2463978617 PH2_Verschmutzungsmeldung "Meldung einer Verschmutzung/Vereisung der PDC an das Kombi";
CM_ SG_ 2463978617 PH2_Aufschaltursache "Der Grund für die Aufschaltung der Einparkhilfe wird angegeben, z.B. bei der Aktivierung der Einparkhilfe durch eine andere Funktion, wird diese Funktion als Aktivierungsursache für die Dauer der Aktivierung gemeldet.
Das Signal wird den PH_Systemzustand";
CM_ SG_ 2463978617 PH2_WAH_Meldung "Steuert die HMI-Meldungen im Kombi für den Wiederanfahrhinweis";
CM_ BO_ 1175 "neue Struktur ab MQB ohne KD-Fehler";
CM_ SG_ 1175 PH_Visualisierung "Signal zeigt den Partnersteuergeräten RearView/TopView/ARA/... den aktuellen Status der Visualisierung des OPS. Die Partnersteuergeräte können dadurch auch ihre Aufschaltung an dieses Signal koppeln.";
CM_ SG_ 1175 PDC_Tonausgabe_Front "In Abhängigkeit der Systemaktivitäten werden unterschiedliche Tonwarnungen ausgegeben. 
Kombi spielt entsprechende WAV.-Datei über internen Audiomaster ab.

0 = kein Ton
1 = Intervallton 1
2 = Intervallton 2
3 = Intervallton 3
4 = Intervallton 4
5";
CM_ SG_ 1175 PDC_Tonausgabe_Heck "In Abhängigkeit der Systemaktivitäten werden unterschiedliche Tonwarnungen ausgegeben. 
Kombi spielt entsprechende WAV.-Datei über internen Audiomaster ab.

0 = kein Ton
1 = Intervallton 1
2 = Intervallton 2
3 = Intervallton 3
4 = Intervallton 4
5";
CM_ SG_ 1175 PH_nachtr_Stopp_Anf "Dieses Signal dient dem Motor als Trigger, dass ein nachträglicher Motorstopp eingeleitet werden kann, wenn es die Bedingungen des StSt Koordinators dies zulassen. ";
CM_ SG_ 1175 PH_Abschaltursache "Abschaltursache bleibt bis zur nächsten Aktivierung bzw. bis KL15 aus gesetzt
Im Fehlerfall (blinkende LED) wird '7' gesendet obwohl das System noch aktiv ist, bei 'geheiltem' Fehler wird sofort wieder der Zustand '0' gesendet";
CM_ SG_ 1175 PH_Opt_Anzeige_V_ein "OPS vorne ist im Display aktiv bzw. Anzeigemodule vorne sind eingeschaltet. Funktion nur bei gesicherter Rückmeldung vom ASG gegeben.";
CM_ SG_ 1175 PH_Opt_Anzeige_H_ein "OPS hinten ist im Display aktiv bzw. Anzeigemodule hinten sind eingeschaltet. Funktion nur bei gesicherter Rückmeldung vom ASG gegeben.";
CM_ SG_ 1175 PH_Opt_Anz_V_Hindernis "mindestens 1 Segment wird für den vorderen Detekionsbereich dargestellt, also ein Hindernis ist im Detektionsbereich. Funktion nur bei gesicherter Rückmeldung vom ASG gegeben.";
CM_ SG_ 1175 PH_Opt_Anz_H_Hindernis "mindestens 1 Segment wird für den hinteren Detekionsbereich dargestellt, also ein Hindernis ist im Detektionsbereich. Funktion nur bei gesicherter Rückmeldung vom ASG gegeben.";
CM_ SG_ 1175 PH_Tongeber_V_aktiv "Rohsignal für 'Tongeber vorne wird angesteuert', verlängerbar mit Nachlauftimer.
Bit wird nicht während des Stellgliedtests angesteuert.";
CM_ SG_ 1175 PH_Tongeber_H_aktiv "Rohsignal für 'Tongeber hinten wird angesteuert', verlängerbar mit Nachlauftimer.
Bit wird nicht während des Stellgliedtests angesteuert.";
CM_ SG_ 1175 PH_Tongeber_mute "Die Akustikausgabe des Systems wird unterdrückt, z.B. Wählhebel in 'P', Parlbremse geschlossen (8-Kanal-System)";
CM_ SG_ 1175 PH_Anf_Audioabsenkung "Es gibt zwei unterschiedliche Nachlauftimer für dieses Bit:
1. normale Funktion
2. Demotonausgabe";
CM_ SG_ 1175 PH_Tongeber_H_verfuegbar "Tongeber ist für die Tonausgabe für externe Funktionen verfügbar. PDC ist aktiv und Tongeber ist nicht gestört.";
CM_ SG_ 1175 PLA_Anf_Aufschaltung_RVC "Anforderung der Aufschaltung RVC durch PLA";
CM_ SG_ 1175 PH_Taster "Taster Status (für RVC/TopView)";
CM_ SG_ 1175 PH_Anf_Verdeck "Anforderung an ein Verdeck-System, die vom Fahrer angeforderte Öffnung/Schließung zu verhindern";
CM_ SG_ 1175 PH_Frequenz_hinten "Uebertragung der aktuell im APS Steuergeraet gespeicherten Werte fuer Tongeber Frequenz hinten
Anzeige der aktuell verwendeten Parameter (nicht zwingend die abgespeicherten - da Werte erst 2s nach der letzten Änderung gespeichert werden!)";
CM_ SG_ 1175 PH_Lautstaerke_hinten "Uebertragung der aktuell im APS Steuergeraet gespeicherten Werte fuer Tongeber Lautstaerke hinten
Anzeige der aktuell verwendeten Parameter (nicht zwingend die abgespeicherten - da Werte erst 2s nach der letzten Änderung gespeichert werden!)";
CM_ SG_ 1175 PH_Frequenz_vorn "Uebertragung der aktuell im APS Steuergeraet gespeicherten Werte fuer Tongeber Frequenz vorne
Anzeige der aktuell verwendeten Parameter (nicht zwingend die abgespeicherten - da Werte erst 2s nach der letzten Änderung gespeichert werden!)";
CM_ SG_ 1175 PH_Lautstaerke_vorn "Uebertragung der aktuell im APS Steuergeraet gespeicherten Werte fuer Tongeber Lautstaerke vorn.
Anzeige der aktuell verwendeten Parameter (nicht zwingend die abgespeicherten - da Werte erst 2s nach der letzten Änderung gespeichert werden!)";
CM_ SG_ 1175 PH_StartStopp_Info "Stopp-Freigabe und Start-Anforderung an den Start-Stopp-Koordinator";
CM_ SG_ 1175 PH_Stoermeldung "Meldung einer Störung der PDC an das Kombi";
CM_ SG_ 1175 PH_defekt "Zeigt an das sich die Parkhilfe im Fehlerzustand befindet. Signal bleibt bis zur nächsten 'Gut-Aktivierung' gesetzt.
Spezialfall: Sensordefekt hinten bei Anhängerbetrieb. Anhänger wird abgesteckt Fehler wird gesetzt. Fehlerfall bleibt bis Behebung des De";
CM_ SG_ 1175 PH_gestoert "Eine Störung ist aufgetreten, der die Parkhilfe in einen 'gestört-Zustand' versetzt, z.B. massiver Fremdultraschall, Vereisung, Schnee.Derzeit nur für Störschall benutzt, da keinerlei andere Erkennung implementiert.";
CM_ SG_ 1175 PH_Systemzustand "Aktivierungsursache wird für die Dauer der Aktivierung gemeldet.
Im Fehlerfall bei atkviem System wechselt das Signal auf '7'
(siehe auch 'Abschaltursache')";
CM_ SG_ 1175 PH_Display_Kundenwunsch "Anzeige der bei Aktivierung verwendeten Parameter bzgl. Kundenwunsch Displayanziege. Änderungen werden erst bei erneuter Aktivierung aktualisiert.";
CM_ BO_ 1355 "neue Struktur ab MQB ohne KD-Fehler";
CM_ SG_ 1355 PH_Verschmutzungsmeldung "Meldung einer Verschmutzung/Vereisung der PDC an das Kombi";
CM_ SG_ 1355 PH_Aufschaltursache "Der Grund für die Aufschaltung der Einparkhilfe wird angegeben, z.B. bei der Aktivierung der Einparkhilfe durch eine andere Funktion, wird diese Funktion als Aktivierungsursache für die Dauer der Aktivierung gemeldet.
Das Signal wird den PH_Systemzustand";
CM_ SG_ 1355 PH_Ton_Ausgabe "Anforderung einer Tonausgabe beim MIB3 durch die Parkhilfe";
CM_ SG_ 1355 PH_Ton_Pausenlaenge "Pause zwischen den angeforderten Tönen beim MIB3 durch die Parkhilfe. Nur für Intervalltöne, nicht relevant für Dauerton und Quittierungston.";
CM_ SG_ 1355 PH_Ton_Richtung "Abspielrichtung des angeforderten Ton beim MIB3 durch die Parkhilfe";
CM_ SG_ 1355 PH_Ton_Lautstaerke "Wunschlautstärke der Tonanforderung beim MIB3 durch die Parkhilfe.";
CM_ SG_ 1355 BCM_WAH_Meldung "Steuert die HMI-Meldungen im Kombi für den Wiederanfahrhinweis";
CM_ SG_ 1355 PDC_Charisma_Status "Charisma Systemstatus des Charisma-Teilnehmers";
CM_ SG_ 1355 PDC_Charisma_FahrPr "Istwert der Kennline (siehe System-LAH MQB FPA)";
CM_ SG_ 617 PIF_Toggle "Alive Counter der PIF-Funktion";
CM_ SG_ 617 PIF_ST_Status "Status der Short-Term Botschaft (0 - 10 s Prädiktionshorizont)";
CM_ SG_ 617 PIF_MT_Status "Status der Mid-Term Botschaft (0 - 10 s Prädiktionshorizont)";
CM_ SG_ 617 PIF_LT_Status "Status der Long-Term Botschaft (0 - 10 s Prädiktionshorizont)";
CM_ SG_ 617 PIF_Identifier "Mux Identifier PIF Botschaft";
CM_ SG_ 617 PIF_ST_Bin_0 "Wahrscheinlichkeit für Bereich 0 im Short-Term Horizont. Übermittelte Größe entsprechend PIF_Mux";
CM_ SG_ 617 PIF_ST_Bin_1 "Wahrscheinlichkeit für Bereich 1 im Short-Term Horizont. Übermittelte Größe entsprechend PIF_Mux";
CM_ SG_ 617 PIF_ST_Bin_2 "Wahrscheinlichkeit für diesen Bereich im Short-Term Horizont. Übermittelte Größe entsprechend PIF_Mux";
CM_ SG_ 617 PIF_ST_Bin_3 "Wahrscheinlichkeit für diesen Bereich im Short-Term Horizont. Übermittelte Größe entsprechend PIF_Mux";
CM_ SG_ 617 PIF_ST_Bin_4 "Wahrscheinlichkeit für diesen Bereich im Short-Term Horizont. Übermittelte Größe entsprechend PIF_Mux";
CM_ SG_ 617 PIF_ST_Bin_5 "Wahrscheinlichkeit für diesen Bereich im Short-Term Horizont. Übermittelte Größe entsprechend PIF_Mux";
CM_ SG_ 617 PIF_ST_Bin_6 "Wahrscheinlichkeit für diesen Bereich im Short-Term Horizont. Übermittelte Größe entsprechend PIF_Mux";
CM_ SG_ 617 PIF_ST_Bin_7 "Wahrscheinlichkeit für diesen Bereich im Short-Term Horizont. Übermittelte Größe entsprechend PIF_Mux";
CM_ SG_ 617 PIF_ST_Bin_8 "Wahrscheinlichkeit für diesen Bereich im Short-Term Horizont. Übermittelte Größe entsprechend PIF_Mux";
CM_ SG_ 617 PIF_MT_Bin_0 "Wahrscheinlichkeit für Bereich 0 im Mid-Term Horizont. Übermittelte Größe entsprechend PIF_Mux";
CM_ SG_ 617 PIF_MT_Bin_1 "Wahrscheinlichkeit für Bereich 0 im Mid-Term Horizont. Übermittelte Größe entsprechend PIF_Mux";
CM_ SG_ 617 PIF_MT_Bin_2 "Wahrscheinlichkeit für Bereich 0 im Mid-Term Horizont. Übermittelte Größe entsprechend PIF_Mux";
CM_ SG_ 617 PIF_MT_Bin_3 "Wahrscheinlichkeit für Bereich 0 im Mid-Term Horizont. Übermittelte Größe entsprechend PIF_Mux";
CM_ SG_ 617 PIF_MT_Bin_4 "Wahrscheinlichkeit für Bereich 0 im Mid-Term Horizont. Übermittelte Größe entsprechend PIF_Mux";
CM_ SG_ 617 PIF_MT_Bin_5 "Wahrscheinlichkeit für Bereich 0 im Mid-Term Horizont. Übermittelte Größe entsprechend PIF_Mux";
CM_ SG_ 617 PIF_MT_Bin_6 "Wahrscheinlichkeit für Bereich 0 im Mid-Term Horizont. Übermittelte Größe entsprechend PIF_Mux";
CM_ SG_ 617 PIF_MT_Bin_7 "Wahrscheinlichkeit für Bereich 0 im Mid-Term Horizont. Übermittelte Größe entsprechend PIF_Mux";
CM_ SG_ 617 PIF_MT_Bin_8 "Wahrscheinlichkeit für Bereich 0 im Mid-Term Horizont. Übermittelte Größe entsprechend PIF_Mux";
CM_ SG_ 617 PIF_LT_Bin_0 "Wahrscheinlichkeit im Long-Term Horizont. Übermittelte Größe entsprechend PIF_Mux";
CM_ SG_ 617 PIF_LT_Bin_1 "Wahrscheinlichkeit im Long-Term Horizont. Übermittelte Größe entsprechend PIF_Mux";
CM_ SG_ 617 PIF_LT_Bin_2 "Wahrscheinlichkeit im Long-Term Horizont. Übermittelte Größe entsprechend PIF_Mux";
CM_ SG_ 617 PIF_LT_Bin_3 "Wahrscheinlichkeit im Long-Term Horizont. Übermittelte Größe entsprechend PIF_Mux";
CM_ SG_ 617 PIF_LT_Bin_4 "Wahrscheinlichkeit im Long-Term Horizont. Übermittelte Größe entsprechend PIF_Mux";
CM_ SG_ 617 PIF_LT_Bin_5 "Wahrscheinlichkeit im Long-Term Horizont. Übermittelte Größe entsprechend PIF_Mux";
CM_ SG_ 617 PIF_LT_Bin_6 "Wahrscheinlichkeit im Long-Term Horizont. Übermittelte Größe entsprechend PIF_Mux";
CM_ SG_ 617 PIF_LT_Bin_7 "Wahrscheinlichkeit im Long-Term Horizont. Übermittelte Größe entsprechend PIF_Mux";
CM_ SG_ 617 PIF_LT_Bin_8 "Wahrscheinlichkeit im Long-Term Horizont. Übermittelte Größe entsprechend PIF_Mux";
CM_ SG_ 2549876804 PnC_Ladegeraet_Req_Data "Plug and Charge request an Ladegeraet";
CM_ SG_ 2550007876 PnC_Ladegeraet_Resp_Data "Plug and Charge response an Ladegeraet";
CM_ SG_ 2527679715 pVS_EnergieAnfr_Zaehler "Fortlaufender Zähler für die Anfrage Energie durch die Funktion pVS.";
CM_ SG_ 2527679715 pVS_EnergieAnfr_SocStart "Energieanfrage zur Erstellung einer Ladekurve: Start-SoC";
CM_ SG_ 2527679715 pVS_EnergieAnfr_SocZiel "Energieanfrage zur Erstellung einer Ladekurve: Ziel-SOC";
CM_ SG_ 2527679715 pVS_Zielklimamodus_Range_pers "Vom Nutzer konfigurierter Zielklimamodus (personalisiert) welchen die Klimaanlage im Fahrprogramm Range (ohne pVS) annehmen soll, wenn Sie nicht bereits in einem Energieeffizienterem Klimamodus ist.";
CM_ SG_ 2527679715 pVS_Zielklimamodus_Range "Zielklimamodus welchen die Klimaanlage im Fahrprogramm Range annehmen soll, wenn Sie nicht bereits in einem Energieeffizienterem Klimamodus ist.";
CM_ SG_ 2527679715 pVS_LadegrenzeAnfr_Zaehler "Fortlaufender Zähler für die Anfrage Ladegrenze für die Funktion pVS (Erzeugung einer Ladekurve)";
CM_ SG_ 2527679715 pVS_LadegrenzeAnfr_Leistung "Anfrage Ladeleistung mit welcher bis zu SOC aus BMS_LadegrenzeAntw_SOC geladen werden kann.
Anfrage wird von pVS zur Erstellung einer Ladekurve versendet.";
CM_ SG_ 1616 RA_Radio_on "1 = user perceived On";
CM_ SG_ 1616 RA_PowerAmpOn "1 = Request for Amplifier; 0 = Amplifier mute/off";
CM_ SG_ 1616 RA_Radio_mute "1=Radio is muted for telephone";
CM_ SG_ 1616 RA_VNC_OFF "VNC = Vehicle Noice Cancellation;
1 = VNC OFF; 0 = VNC ON
requests the Amp to switch VNC off";
CM_ SG_ 1616 RA_Radio_Surround "1 = Surround ON; 0 = Surround OFF
requests the Amp to switch Surroundmode";
CM_ SG_ 1616 RA_Radio_Error_Flag "1 = mindestens ein Kundendienstfehlerspeicher Eintrag vorhanden";
CM_ SG_ 1616 RA_Frequency "Übermittlung der gehörten Audiofrequenz (AM)
wird mit RA_Frequency_unit multipliziert.
Auf dem Bus werden nur eingerastete Frequenzen übertragen. Bei aktivem Tuning (RA_AM_Tuning = 1) wird 0 übertragen.";
CM_ SG_ 1616 RA_Frequency_unit "Faktor für RA_Frequency
bei AM: Faktor 0 = 1kHz
sonst   Faktor 1 = 100kHz

";
CM_ SG_ 1616 RA_AM_Tuning "Das Signal kennzeichnet einen aktiven AM Suchlauf. Während des Suchlaufes wird die Frequenz = 0 übertragen.
0 = frequency locked => Störquelle vermeidet die aktuelle Frequenz
1 = AM tuning in progress => Störquelle abschalten";
CM_ SG_ 1525 RW_Gesamt_Reichweite_Max_Anzeige "Angabe der Maximalen Anzeige der gesamten Reichweite.
Ergänzt das Signal RW_Gesamt_Reichweite_Anzeige";
CM_ SG_ 1525 RW_Reservewarnung_2_aktiv "Ansteuerung der Reservewarnung im Kombiinstrument (Leuchte und MFA-Warnhinweis). Wird gesetzt bei Erreichen / Unterschreiten eines unteren Reichweitenschwellwerts und zurückgenommen bei Erreich.
Zusätzlich erfolgt eine logische Verknüpfung mit einer akti";
CM_ SG_ 1525 RW_RWDS_Lastprofil "Lastprofil zur Bestimmung der notwendigen Nachladeenergie (Reichweitendurchschnittstrom)";
CM_ SG_ 1525 RW_Gesamt_Reichweite "Reichweite für primär und sekundär Reichweite (eventuell Gewichtet)";
CM_ SG_ 1525 RW_Prim_Reichweitenverbrauch "Für primäre Reichweitenberechnung zugrunde gelegter Verbrauch";
CM_ SG_ 1525 RW_Prim_Reichweitenv_Einheit "Für primäre  Reichweitenberechnung (KBI_Prim_Reichweitenverbrauch) zugrunde gelegte Einheit";
CM_ SG_ 1525 RW_Primaer_Reichweite "Reichweite der primären Antriebsart";
CM_ SG_ 1527 RW_Tendenz "Signalisierung der RW-Tendenz auf Basis der aktuellen Fahrweise. ";
CM_ SG_ 1527 RW_Texte "Signal zum Steuern von reichweitenbezogenen Hinweistexten für Pop-Up Anzeigen im Kombiinstrument";
CM_ SG_ 1527 RW_Reservewarnung_aktiv "Ansteuerung der Reservewarnung im Kombiinstrument (Leuchte und MFA-Warnhinweis). Wird gesetzt bei Erreichen / Unterschreiten eines unteren Reichweitenschwellwerts und zurückgenommen bei Erreichen / Überschreiten eines oberen Reichweitenschwellwerts.";
CM_ SG_ 1527 RW_Reichweite_Einheit_Anzeige "Einheit für Primaer-/Sekundaer-/Gesamt- Reichweite zur Anzeige im Kombi";
CM_ SG_ 1527 RW_Gesamt_Reichweite_Anzeige "Reichweite für primär und sekundär Reichweite (eventuell Gewichtet) zur Anzeige im Kombi";
CM_ SG_ 1527 RW_Primaer_Reichweite_Anzeige "Reichweite der primären Antriebsart zur Anzeige im Kombi";
CM_ SG_ 1527 RW_Sekundaer_Reichweite_Anzeige "Reichweite der sekundaeren Antriebsart zur Anzeige im Kombi";
CM_ SG_ 1527 RW_Sekundaer_Reichweite "Reichweite der sekundaeren Antriebsart";
CM_ SG_ 1527 RW_Sek_Reichweitenv_Einheit "Für sekundäre Reichweitenberechnung (KBI_Sek_Reichweitenverbrauch) zugrunde gelegte Einheit";
CM_ SG_ 1527 RW_Sek_Reichweitenverbrauch "Für sekundäre Reichweitenberechnung zugrunde gelegter Verbrauch";
CM_ SG_ 2463978658 Rezi_Status_Spgfreiheit "Status der HV-Spannungsfreiheitserfassungsfunktion in der LE des Rezi";
CM_ SG_ 2463978658 Rezi_Warnung_Uebertemperatur "Warnung bei überschreiten einer definierten Temperaturschwelle, gesendet von Rezi";
CM_ SG_ 2463978658 Rezi_IstSpannung "DC-Spannung des H2-Rezirkulationsgebläses, gesendet von Rezi";
CM_ SG_ 2463978658 Rezi_Fehler_Blockiert "Läufer des H2-Rezirkulationsgebläses ist blockiert, gesendet von Rezi";
CM_ SG_ 2463978658 Rezi_Fehler_Bauteil_Defekt "Fehler bei Bauteildefekt (elekrischer Fehler, o.ä.), gesendet von Rezi";
CM_ SG_ 2463978658 Rezi_Fehler_Ueberspannung_HV "Überspannung im HV-DC-Netz, gesendet von Rezi";
CM_ SG_ 2463978658 Rezi_Fehler_Ueberspannung_NV "Überspannung im NV-Netz, gesendet von Rezi";
CM_ SG_ 2463978658 Rezi_Fehler_Uebertemperatur "Fehlermeldung bei überschreiten einer definierten Temperaturschwelle, gesendet von Rezi";
CM_ SG_ 2463978658 Rezi_Fehler_Unterspannung_HV "Unterspannung im HV-DC-Netz, gesendet von Rezi";
CM_ SG_ 2463978658 Rezi_IstDrehzahl "aktuelle Drehzahl des H2-Rezirkulationsgebläses, gesendet von Rezi";
CM_ SG_ 2463978658 Rezi_Error_NW_Timeout "Fehler in CAN-Kommunikation, gesendet von Rezi";
CM_ SG_ 2463978658 Rezi_IstStrom "DC-Strom des H2-Rezirkulationsgebläses, gesendet von Rezi";
CM_ SG_ 1126 RTM_Warnstatus "Signalisiert die RTM-Warnstufe.";
CM_ SG_ 1313 STH_LED "Funktionslampe";
CM_ SG_ 1313 STH_EKP_Anst "STH sendet die Anforderung zur Ansteuerung der EKP an den Motor, um Kraftstoffbehälter der STH zu befüllen.";
CM_ SG_ 1313 STH_Start_folgt "Thema Start/Stop: Im Stop-Modus muß das KBT einen Wiederstart anfordern, da ein STH-Start notwendig ist.";
CM_ SG_ 1313 STH_Ventiloeffnungszeit "Die Standheizung sendet an den Motor die Information darüber wie lange das Magnetventil die Wasserkreisläufe von 'klein' aus 'gross' geschaltet hat. ";
CM_ SG_ 1313 STH_Ventil_Status "Statusrückmeldung Ansteuerung 3/2 Wege-Ventil";
CM_ SG_ 1313 STH_Fehler_ElWaPu "Fehler der el. Zusatzwasserpumpe der zur Deaktivierung der Wasserpumpe führt ";
CM_ SG_ 1313 STH_Waermeeintrag "Signal enthält die Brenndauer in 1min-Schritten, über welche die Standheizung gelaufen ist";
CM_ SG_ 1313 STH_Pumpen_Anf_extern "Anforderung der motorseitigen elektr. (externen) Wasserpumpe zur Kreislaufunterstützung im Standheizbetrieb";
CM_ SG_ 1313 STH_KL_HUP "Signal HUP Aktivierung an Klima

0 = HUP aus
1 = HUP ein";
CM_ SG_ 1313 STH_KVS "Kraftstoffverbrauch";
CM_ SG_ 1313 STH_Fehlerstatus "Übermittlung der unterschiedlichen Fehlerzustände der Standheizung";
CM_ SG_ 1313 STH_Heizleistung "Heizleistung in %";
CM_ SG_ 1313 STH_Texte "Anforderung der unterschiedlichen Anzeigetexte im Mitteldisplay des Kombi.

0: Keine Anzeige
1: Kein Standheizungs- bzw Lueftungsbetrieb wegen Batteriemanagementeinschraenkung
2: Kein Standheizungs- bzw Lueftungsbetrieb wegen Kraftstoffmangels
3: Kei";
CM_ SG_ 1313 STH_Motorvorwaermung "Info an der Motor, dass der Aufheizvorgang mit Motorvorwärmung erfolgt ist";
CM_ SG_ 1313 STH_war_aktiv "Bit beeinhaltet die Info, dass die Standheizung während der letzten halbe Stunde aktiv war.";
CM_ SG_ 1313 STH_SH_ZH "0 = Heizgerät ist Standheizung
1 = Heizgerät ist Zuheizer
Gerätekennung WZH oder ZH
";
CM_ SG_ 505 STP_03_CRC "End-to-End Absicherung";
CM_ SG_ 505 STP_03_BZ "Botschaftszähler
Botschaft asynchron geroutet. Zählerwert kann springen.";
CM_ SG_ 505 STP_Slave_Status "Zustandsbeschreibung für STP-Slave-State-Machine";
CM_ SG_ 505 FZE_STP_Abschaltbedingung "Es liegt eine FZE Bedienhandlung für eine Abschaltung vor";
CM_ SG_ 505 ACA_HF_Grund_AV_AB "Abschaltbedingung und Aktivierverhinderung";
CM_ SG_ 505 FZE_STP_Status "'Initialisierung / Auskodiert
FZE_STP Signale können verwendet werden
Es liegt ein reversibler Fehler für STP Signale vor
Es liegt ein irreversibler Fehler für STP Signale vor'
";
CM_ SG_ 505 STP_Notlaufaktivierung "Aktivierung des Notlaufs im ESC/EBKV durch den STP";
CM_ SG_ 505 STP_Funktion_freigegeben "Gibt in ASIL D an, ob die Funktion Staupilot zum Betrieb freigegeben ist.";
CM_ SG_ 505 ACA_QF_Status_Anzeige "Status der ACA Querführung, angepasst für die HMI Ansteuerung im ACC-SG";
CM_ SG_ 505 ACF_SwuFahrerUnaufmerksam "Erkannte Fahrerunaufmerksamkeit von der FZE (ACF)";
CM_ SG_ 505 ACA_QF_Fahreruebernahme "Anforderung einer Fahrerübernhame durch die ACA Querführung für die HMI Ansteuerung im ACC-SG";
CM_ SG_ 505 ACA_HF_Status "Status der Hands-Off-Querfuehrung";
CM_ SG_ 505 FZE_Spurwechsel_erkannt_li "Spurwechsel nach links erkannt.";
CM_ SG_ 505 FZE_Spurwechsel_erkannt_re "Spurwechsel nach rechts erkannt.";
CM_ SG_ 505 ACF_Spurwechsel_moeglich "Spurwechselmöglichkeit in Überholrichtung (verkehrssinnabh.) gegeben";
CM_ SG_ 505 ACF_Spurwechsel_wahrscheinlich "Spurwechsel in Überholrichtung (verkehrssinnabh.) wahrscheinlich";
CM_ SG_ 505 FZE_STP_Aktivierverhinderung "Aktivierverhinderungen STP aus Sicht der FZE";
CM_ SG_ 1001 Thermo_Pred_T_dyn_Innen "Zeit bis zum Übergang vom dynamischen in stationären Betrieb";
CM_ SG_ 1001 Thermo_Pred_Innen_Kunde_Anf "Änderung der Prädiktion iniziiert durch Kundenaktion";
CM_ SG_ 1001 Thermo_Pred_P_dyn_Innen "Dynamsiche Leistung für Headup / Cooldown";
CM_ SG_ 1001 Thermo_Pred_P_stat_Innen "Stationäre Leistung für Heizen / Kühlen";
CM_ SG_ 1001 Thermo_Verbrauch_BTL "Verbrauch für Heizen und Kühlen der Bauteile";
CM_ SG_ 1001 Thermo_Verbrauch_BTL_Ueberlauf "Überlauf-Bit Verbrauch Bauteil";
CM_ SG_ 1001 Thermo_Pred_Innen_System_Anf "Systemseitig initiierte Änderung der Prädiktion; Signal ist einheitsloser Zähler mit Überlauf. 
Eine Inkrementierung steht für die Änderung der Umgebungsbedingungen mit dazugehöriger Klimaleistungsänderung.";
CM_ SG_ 1001 Thermo_Verbrauch_Innen "Verbrauch für Heizen und Kühlen Innenraum";
CM_ SG_ 1001 Thermo_Verbrauch_Innen_Ueberlauf "Überlauf-Bit Verbrauch Innenraum";
CM_ SG_ 1015 KL_HV_Energie_Anf "Anforderung HV - Energiebedarf, für VoKo 
";
CM_ SG_ 1015 TME_Kuehlerluefer_3 "Soll-PWM für Lüfter3";
CM_ SG_ 1015 TME_StartStopp_Info_Prio "Priorität der Stopp-Freigabe und Start-Anforderung an den Start-Stopp-Koordinator";
CM_ SG_ 1015 TME_HVEM_HV_Anf "Anforderung 'HV-Netz aktivieren' wegen Innenraumkonditionierung mit HV-Komponente";
CM_ SG_ 1015 TME_StartStopp_Info "Stopp-Freigabe und Start-Anforderung an den Start-Stopp-Koordinator";
CM_ SG_ 1015 TME_OBD_Lampe_Anf "MIL-Request durch TME-Steuergerät";
CM_ SG_ 1015 TME_HVPTC_Istmodus "aktuelle Ist-Betriebsart der HV-PTC";
CM_ SG_ 1015 TME_HVPTC_Fehlerstatus "aktueller Fehlerstatus des HVPTC";
CM_ SG_ 1015 TME_EKK_Istmodus "aktuelle IstModus des elektrischen Klimakompressors";
CM_ SG_ 1015 TME_EKK_Fehlerstatus "aktueller Fehlerstatus des EKK";
CM_ SG_ 1015 TME_HVK_EKK_SOLL "Anforderung an HVK den HV EKK abzuschalten.";
CM_ SG_ 1015 TME_Strom_Kuehlerluefter "aktueller Kühlerlüfterstrom, +-20% ";
CM_ SG_ 1015 TME_PWM_Pumpe1_tNT_Soll "Soll-PWM für Pumpe 1 im Tiefniedertemperaturkreis";
CM_ SG_ 1017 TME_NT_Kreis_Status "Status gibt an ob der NT Kreis funktional i.O ist. (Komponenten i.O)";
CM_ SG_ 1017 TME_Ventil1_Status "Statusrückmeldung Ansteuerung 3/2 Wege-Ventil";
CM_ SG_ 1017 TME_Fehler_ElWaPu1 "Fehler der el. Zusatzwasserpumpe der zur Deaktivierung der Wasserpumpe führt";
CM_ SG_ 1017 TME_Pumpe1_Status "Rückmeldung des Heizungspumpenstatus";
CM_ SG_ 1017 TME_Nachlaufzeit "Nachlaufzeit TME für SKE am MSG";
CM_ SG_ 1017 TME_Anf_KL "Max. Kühlerlüfteransteuerung der TME in %";
CM_ SG_ 1017 TME_Status_KL "Fehlerstatus des Kühlerlüftermodules";
CM_ SG_ 1017 TME_EM1_IstVolumenstrom "Aktueller Ist-Wert des Vorlaufvolumenstromes LE/EM 1";
CM_ SG_ 1017 TME_EM2_IstVolumenstrom "Aktueller Ist-Wert des Vorlaufvolumenstromes LE/EM 2";
CM_ SG_ 1017 TME_EM3_IstVolumenstrom "Aktueller Ist-Wert des Vorlaufvolumenstromes LE/EM 3";
CM_ SG_ 1017 TME_PWM_Pumpe2_HK_Soll "Soll-PWM für Heizkreispumpe vor Motorchiller";
BA_DEF_ BO_  "DiagRequest" ENUM  "No","Yes";
BA_DEF_ BO_  "DiagResponse" ENUM  "No","Yes";
BA_DEF_ BO_  "DiagState" ENUM  "No","Yes";
BA_DEF_ BO_  "GenMsgChkConstant" HEX 0 4095;
BA_DEF_ BO_  "GenMsgCycleTime" INT 0 65535;
BA_DEF_ BO_  "GenMsgCycleTimeFast" INT 0 65535;
BA_DEF_ BO_  "GenMsgDelayTime" INT 0 100000;
BA_DEF_ BO_  "GenMsgILSupport" ENUM  "No","Yes";
BA_DEF_ BO_  "GenMsgNrOfRepetition" INT 0 100;
BA_DEF_ BO_  "GenMsgPDUConstants" STRING ;
BA_DEF_ BO_  "GenMsgSendType" ENUM  "Cyclic","not_used","not_used","not_used","not_used","not_used","not_used","IfActive","NoMsgSendType";
BA_DEF_ BO_  "GenMsgStartDelayTime" INT 0 100000;
BA_DEF_ BO_  "NmMessage" ENUM  "No","Yes";
BA_DEF_ BO_  "NmhMessage" ENUM  "No","Yes";
BA_DEF_ BO_  "MsgType" ENUM  "Application","NM ","NMH","TP2.0","ISO-TP ","BAP","EID","KS","XCP_PRE_CONFIGURED","XCP_RUNTIME_CONFIGURED";
BA_DEF_ BO_  "VAGTP20_API" HEX 0 255;
BA_DEF_ BO_  "VAGTP20_DynConnection" ENUM  "No","Yes";
BA_DEF_ BO_  "VAGTP20_DynSetup" ENUM  "No","Yes";
BA_DEF_ BO_  "VAGTP20_StatConnection" ENUM  "No","Yes";
BA_DEF_ SG_  "GenSigActiveRepetitions" INT -2147483648 2147483647;
BA_DEF_ SG_  "GenSigInactiveValue" INT -2147483648 2147483647;
BA_DEF_ SG_  "GenSigSendType" ENUM  "Cyclic","OnWrite","OnWriteWithRepetition","OnChange","OnChangeWithRepetition","IfActive","IfActiveWithRepetition","NoSigSendType","OnChangeAndIfActive","OnChangeAndIfActiveWithRepetition";
BA_DEF_ SG_  "GenSigStartValue" INT -2147483648 2147483647;
BA_DEF_ SG_  "NWM-WakeupAllowed" ENUM  "No","Yes";
BA_DEF_ SG_  "GenSigFuncType" ENUM  "NoFunction","MsgCounter","CRC-8","XOR","XOR-2","DatedBit","SW-Kl15","CHK","Constant","Protocol","CRC-8-SAE_J1850","CRC-32","DataLength","DataID","MsgCounter16","SOK-Signatur","Cluster";
BA_DEF_ SG_  "GenSigSwitchedByIgnition" ENUM  "No","Yes";
BA_DEF_ SG_  "Fehlerwert" HEX 0 2147483647;
BA_DEF_ SG_  "GenSigMissingSourceValue" HEX 0 2147483647;
BA_DEF_REL_ BU_SG_REL_  "GenSigTimeoutTime" INT 0 65535;
BA_DEF_DEF_REL_ "GenSigTimeoutTime" 0;
BA_DEF_DEF_  "DiagRequest" "No";
BA_DEF_DEF_  "DiagResponse" "No";
BA_DEF_DEF_  "DiagState" "No";
BA_DEF_DEF_  "GenMsgChkConstant" 0;
BA_DEF_DEF_  "GenMsgCycleTime" 0;
BA_DEF_DEF_  "GenMsgCycleTimeFast" 0;
BA_DEF_DEF_  "GenMsgDelayTime" 0;
BA_DEF_DEF_  "GenMsgILSupport" "No";
BA_DEF_DEF_  "GenMsgNrOfRepetition" 0;
BA_DEF_DEF_  "GenMsgPDUConstants" "";
BA_DEF_DEF_  "GenMsgSendType" "NoMsgSendType";
BA_DEF_DEF_  "GenMsgStartDelayTime" 0;
BA_DEF_DEF_  "NmMessage" "No";
BA_DEF_DEF_  "NmhMessage" "No";
BA_DEF_DEF_  "MsgType" "Application";
BA_DEF_DEF_  "VAGTP20_API" 0;
BA_DEF_DEF_  "VAGTP20_DynConnection" "No";
BA_DEF_DEF_  "VAGTP20_DynSetup" "No";
BA_DEF_DEF_  "VAGTP20_StatConnection" "No";
BA_DEF_DEF_  "GenSigActiveRepetitions" 0;
BA_DEF_DEF_  "GenSigInactiveValue" 0;
BA_DEF_DEF_  "GenSigSendType" "NoSigSendType";
BA_DEF_DEF_  "GenSigStartValue" 0;
BA_DEF_DEF_  "NWM-WakeupAllowed" "No";
BA_DEF_DEF_  "GenSigFuncType" "NoFunction";
BA_DEF_DEF_  "GenSigSwitchedByIgnition" "Yes";
BA_DEF_DEF_  "Fehlerwert" 0;
BA_DEF_DEF_  "GenSigMissingSourceValue" 0;
BA_ "MsgType" BO_ 2600468546 2;
BA_ "NmhMessage" BO_ 2600468546 1;
BA_ "GenMsgSendType" BO_ 2600468546 7;
BA_ "GenMsgCycleTimeFast" BO_ 2600468546 10;
BA_ "GenMsgCycleTime" BO_ 2600468546 200;
BA_ "GenMsgStartDelayTime" BO_ 1635 10;
BA_ "GenMsgSendType" BO_ 1635 0;
BA_ "GenMsgILSupport" BO_ 1635 1;
BA_ "GenMsgCycleTime" BO_ 1635 100;
BA_ "GenMsgStartDelayTime" BO_ 869 5;
BA_ "GenMsgSendType" BO_ 869 0;
BA_ "GenMsgPDUConstants" BO_ 869 "0xe3,0x0a,0x29,0xd3,0x96,0xaa,0xeb,0x89,0xe6,0x5f,0x14,0xc4,0xe9,0x27,0x0b,0x2d";
BA_ "GenMsgILSupport" BO_ 869 1;
BA_ "GenMsgCycleTime" BO_ 869 50;
BA_ "GenMsgStartDelayTime" BO_ 2527679508 10;
BA_ "GenMsgSendType" BO_ 2527679508 0;
BA_ "GenMsgPDUConstants" BO_ 2527679508 "0xa3,0xed,0x65,0xcf,0xc5,0x26,0x54,0x1a,0x99,0x3c,0x01,0x84,0xf4,0x46,0x9c,0x28";
BA_ "GenMsgILSupport" BO_ 2527679508 1;
BA_ "GenMsgDelayTime" BO_ 2527679508 80;
BA_ "GenMsgCycleTime" BO_ 2527679508 100;
BA_ "GenMsgStartDelayTime" BO_ 2527679509 50;
BA_ "GenMsgSendType" BO_ 2527679509 0;
BA_ "GenMsgPDUConstants" BO_ 2527679509 "0x01,0x40,0xf0,0x21,0x22,0x92,0x44,0x1a,0x85,0xeb,0x7b,0xcd,0x7c,0x59,0xc5,0xc2";
BA_ "GenMsgILSupport" BO_ 2527679509 1;
BA_ "GenMsgDelayTime" BO_ 2527679509 50;
BA_ "GenMsgCycleTime" BO_ 2527679509 500;
BA_ "GenMsgStartDelayTime" BO_ 527 50;
BA_ "GenMsgSendType" BO_ 527 0;
BA_ "GenMsgPDUConstants" BO_ 527 "0xd4,0x22,0xad,0x3f,0x25,0xaa,0x62,0x5b,0xdc,0x73,0xed,0xc3,0x9a,0x14,0x2f,0x3e";
BA_ "GenMsgILSupport" BO_ 527 1;
BA_ "GenMsgCycleTime" BO_ 527 50;
BA_ "GenMsgSendType" BO_ 913 0;
BA_ "GenMsgILSupport" BO_ 913 1;
BA_ "GenMsgCycleTime" BO_ 913 80;
BA_ "MsgType" BO_ 2549875343 4;
BA_ "DiagRequest" BO_ 2549875343 1;
BA_ "MsgType" BO_ 2550006415 4;
BA_ "DiagResponse" BO_ 2550006415 1;
BA_ "MsgType" BO_ 2549875374 4;
BA_ "DiagRequest" BO_ 2549875374 1;
BA_ "MsgType" BO_ 2550006446 4;
BA_ "DiagResponse" BO_ 2550006446 1;
BA_ "MsgType" BO_ 2549875356 4;
BA_ "DiagRequest" BO_ 2549875356 1;
BA_ "MsgType" BO_ 2550006428 4;
BA_ "DiagResponse" BO_ 2550006428 1;
BA_ "MsgType" BO_ 2549875399 4;
BA_ "DiagRequest" BO_ 2549875399 1;
BA_ "MsgType" BO_ 2550006471 4;
BA_ "DiagResponse" BO_ 2550006471 1;
BA_ "MsgType" BO_ 2549875407 4;
BA_ "DiagRequest" BO_ 2549875407 1;
BA_ "MsgType" BO_ 2550006479 4;
BA_ "DiagResponse" BO_ 2550006479 1;
BA_ "MsgType" BO_ 2549875383 4;
BA_ "DiagRequest" BO_ 2549875383 1;
BA_ "MsgType" BO_ 2550006455 4;
BA_ "DiagResponse" BO_ 2550006455 1;
BA_ "MsgType" BO_ 2549875265 4;
BA_ "DiagRequest" BO_ 2549875265 1;
BA_ "MsgType" BO_ 2550006337 4;
BA_ "DiagResponse" BO_ 2550006337 1;
BA_ "MsgType" BO_ 2549875381 4;
BA_ "DiagRequest" BO_ 2549875381 1;
BA_ "MsgType" BO_ 2550006453 4;
BA_ "DiagResponse" BO_ 2550006453 1;
BA_ "MsgType" BO_ 2549940736 4;
BA_ "DiagState" BO_ 2549940736 1;
BA_ "MsgType" BO_ 2549875323 4;
BA_ "DiagRequest" BO_ 2549875323 1;
BA_ "MsgType" BO_ 2550006395 4;
BA_ "DiagResponse" BO_ 2550006395 1;
BA_ "MsgType" BO_ 2549875398 4;
BA_ "DiagRequest" BO_ 2549875398 1;
BA_ "MsgType" BO_ 2550006470 4;
BA_ "DiagResponse" BO_ 2550006470 1;
BA_ "MsgType" BO_ 2549875268 4;
BA_ "DiagRequest" BO_ 2549875268 1;
BA_ "MsgType" BO_ 2550006340 4;
BA_ "DiagResponse" BO_ 2550006340 1;
BA_ "MsgType" BO_ 2549903568 4;
BA_ "DiagRequest" BO_ 2549903568 1;
BA_ "MsgType" BO_ 2550034640 4;
BA_ "DiagResponse" BO_ 2550034640 1;
BA_ "MsgType" BO_ 2549903569 4;
BA_ "DiagRequest" BO_ 2549903569 1;
BA_ "MsgType" BO_ 2550034641 4;
BA_ "DiagResponse" BO_ 2550034641 1;
BA_ "MsgType" BO_ 2549903570 4;
BA_ "DiagRequest" BO_ 2549903570 1;
BA_ "MsgType" BO_ 2550034642 4;
BA_ "DiagResponse" BO_ 2550034642 1;
BA_ "MsgType" BO_ 2549903571 4;
BA_ "DiagRequest" BO_ 2549903571 1;
BA_ "MsgType" BO_ 2550034643 4;
BA_ "DiagResponse" BO_ 2550034643 1;
BA_ "MsgType" BO_ 2549903572 4;
BA_ "DiagRequest" BO_ 2549903572 1;
BA_ "MsgType" BO_ 2550034644 4;
BA_ "DiagResponse" BO_ 2550034644 1;
BA_ "MsgType" BO_ 2549903573 4;
BA_ "DiagRequest" BO_ 2549903573 1;
BA_ "MsgType" BO_ 2550034645 4;
BA_ "DiagResponse" BO_ 2550034645 1;
BA_ "MsgType" BO_ 2549903574 4;
BA_ "DiagRequest" BO_ 2549903574 1;
BA_ "MsgType" BO_ 2550034646 4;
BA_ "DiagResponse" BO_ 2550034646 1;
BA_ "MsgType" BO_ 2549903575 4;
BA_ "DiagRequest" BO_ 2549903575 1;
BA_ "MsgType" BO_ 2550034647 4;
BA_ "DiagResponse" BO_ 2550034647 1;
BA_ "MsgType" BO_ 2549903576 4;
BA_ "DiagRequest" BO_ 2549903576 1;
BA_ "MsgType" BO_ 2550034648 4;
BA_ "DiagResponse" BO_ 2550034648 1;
BA_ "MsgType" BO_ 2549903577 4;
BA_ "DiagRequest" BO_ 2549903577 1;
BA_ "MsgType" BO_ 2550034649 4;
BA_ "DiagResponse" BO_ 2550034649 1;
BA_ "MsgType" BO_ 2549903578 4;
BA_ "DiagRequest" BO_ 2549903578 1;
BA_ "MsgType" BO_ 2550034650 4;
BA_ "DiagResponse" BO_ 2550034650 1;
BA_ "MsgType" BO_ 2549903579 4;
BA_ "DiagRequest" BO_ 2549903579 1;
BA_ "MsgType" BO_ 2550034651 4;
BA_ "DiagResponse" BO_ 2550034651 1;
BA_ "MsgType" BO_ 2549903580 4;
BA_ "DiagRequest" BO_ 2549903580 1;
BA_ "MsgType" BO_ 2550034652 4;
BA_ "DiagResponse" BO_ 2550034652 1;
BA_ "MsgType" BO_ 2549903601 4;
BA_ "DiagRequest" BO_ 2549903601 1;
BA_ "MsgType" BO_ 2550034673 4;
BA_ "DiagResponse" BO_ 2550034673 1;
BA_ "MsgType" BO_ 2549903602 4;
BA_ "DiagRequest" BO_ 2549903602 1;
BA_ "MsgType" BO_ 2550034674 4;
BA_ "DiagResponse" BO_ 2550034674 1;
BA_ "MsgType" BO_ 2549903603 4;
BA_ "DiagRequest" BO_ 2549903603 1;
BA_ "MsgType" BO_ 2550034675 4;
BA_ "DiagResponse" BO_ 2550034675 1;
BA_ "MsgType" BO_ 2549875380 4;
BA_ "DiagRequest" BO_ 2549875380 1;
BA_ "MsgType" BO_ 2550006452 4;
BA_ "DiagResponse" BO_ 2550006452 1;
BA_ "MsgType" BO_ 2549875266 4;
BA_ "DiagRequest" BO_ 2549875266 1;
BA_ "MsgType" BO_ 2550006338 4;
BA_ "DiagResponse" BO_ 2550006338 1;
BA_ "GenMsgStartDelayTime" BO_ 2589283656 160;
BA_ "GenMsgSendType" BO_ 2589283656 0;
BA_ "GenMsgILSupport" BO_ 2589283656 1;
BA_ "GenMsgDelayTime" BO_ 2589283656 160;
BA_ "GenMsgCycleTime" BO_ 2589283656 960;
BA_ "GenMsgSendType" BO_ 872 0;
BA_ "GenMsgILSupport" BO_ 872 1;
BA_ "GenMsgDelayTime" BO_ 872 40;
BA_ "GenMsgCycleTime" BO_ 872 1000;
BA_ "GenMsgSendType" BO_ 2463978617 0;
BA_ "GenMsgILSupport" BO_ 2463978617 1;
BA_ "GenMsgDelayTime" BO_ 2463978617 40;
BA_ "GenMsgCycleTime" BO_ 2463978617 500;
BA_ "GenMsgSendType" BO_ 1175 0;
BA_ "GenMsgILSupport" BO_ 1175 1;
BA_ "GenMsgDelayTime" BO_ 1175 50;
BA_ "GenMsgCycleTime" BO_ 1175 1000;
BA_ "GenMsgSendType" BO_ 1355 0;
BA_ "GenMsgILSupport" BO_ 1355 1;
BA_ "GenMsgDelayTime" BO_ 1355 20;
BA_ "GenMsgCycleTime" BO_ 1355 500;
BA_ "GenMsgSendType" BO_ 617 0;
BA_ "GenMsgILSupport" BO_ 617 1;
BA_ "GenMsgCycleTime" BO_ 617 80;
BA_ "MsgType" BO_ 2549876804 4;
BA_ "MsgType" BO_ 2550007876 4;
BA_ "GenMsgSendType" BO_ 2527679715 0;
BA_ "GenMsgILSupport" BO_ 2527679715 1;
BA_ "GenMsgDelayTime" BO_ 2527679715 200;
BA_ "GenMsgCycleTime" BO_ 2527679715 1000;
BA_ "GenMsgSendType" BO_ 1616 0;
BA_ "GenMsgILSupport" BO_ 1616 1;
BA_ "GenMsgDelayTime" BO_ 1616 50;
BA_ "GenMsgCycleTime" BO_ 1616 1000;
BA_ "GenMsgStartDelayTime" BO_ 1525 85;
BA_ "GenMsgSendType" BO_ 1525 0;
BA_ "GenMsgILSupport" BO_ 1525 1;
BA_ "GenMsgCycleTime" BO_ 1525 500;
BA_ "GenMsgStartDelayTime" BO_ 1527 85;
BA_ "GenMsgSendType" BO_ 1527 0;
BA_ "GenMsgILSupport" BO_ 1527 1;
BA_ "GenMsgDelayTime" BO_ 1527 100;
BA_ "GenMsgCycleTime" BO_ 1527 500;
BA_ "GenMsgSendType" BO_ 2463978658 0;
BA_ "GenMsgILSupport" BO_ 2463978658 1;
BA_ "GenMsgDelayTime" BO_ 2463978658 10;
BA_ "GenMsgCycleTime" BO_ 2463978658 100;
BA_ "GenMsgStartDelayTime" BO_ 1126 160;
BA_ "GenMsgSendType" BO_ 1126 0;
BA_ "GenMsgILSupport" BO_ 1126 1;
BA_ "GenMsgDelayTime" BO_ 1126 100;
BA_ "GenMsgCycleTime" BO_ 1126 500;
BA_ "GenMsgSendType" BO_ 2527679790 0;
BA_ "GenMsgILSupport" BO_ 2527679790 1;
BA_ "GenMsgDelayTime" BO_ 2527679790 50;
BA_ "GenMsgCycleTime" BO_ 2527679790 500;
BA_ "GenMsgSendType" BO_ 2527679791 0;
BA_ "GenMsgILSupport" BO_ 2527679791 1;
BA_ "GenMsgCycleTime" BO_ 2527679791 500;
BA_ "GenMsgSendType" BO_ 2527679792 0;
BA_ "GenMsgILSupport" BO_ 2527679792 1;
BA_ "GenMsgDelayTime" BO_ 2527679792 50;
BA_ "GenMsgCycleTime" BO_ 2527679792 500;
BA_ "GenMsgSendType" BO_ 1313 0;
BA_ "GenMsgILSupport" BO_ 1313 1;
BA_ "GenMsgCycleTime" BO_ 1313 200;
BA_ "GenMsgSendType" BO_ 505 0;
BA_ "GenMsgPDUConstants" BO_ 505 "0x14,0xf8,0xf6,0x94,0x2a,0x12,0x39,0x3d,0x98,0x3f,0xfb,0x9d,0x36,0xca,0x1d,0xe0";
BA_ "GenMsgILSupport" BO_ 505 1;
BA_ "GenMsgCycleTime" BO_ 505 500;
BA_ "GenMsgSendType" BO_ 1001 0;
BA_ "GenMsgILSupport" BO_ 1001 1;
BA_ "GenMsgCycleTime" BO_ 1001 100;
BA_ "GenMsgSendType" BO_ 1015 0;
BA_ "GenMsgILSupport" BO_ 1015 1;
BA_ "GenMsgCycleTime" BO_ 1015 100;
BA_ "GenMsgSendType" BO_ 1017 0;
BA_ "GenMsgILSupport" BO_ 1017 1;
BA_ "GenMsgCycleTime" BO_ 1017 200;
BA_ "GenSigSwitchedByIgnition" SG_ 2600468546 NM_TME_SNI 0;
BA_ "GenSigStartValue" SG_ 2600468546 NM_TME_SNI 66;
BA_ "GenSigSwitchedByIgnition" SG_ 2600468546 NM_TME_CBV_AWB 0;
BA_ "GenSigSwitchedByIgnition" SG_ 2600468546 NM_TME_CBV_CRI 0;
BA_ "GenSigSwitchedByIgnition" SG_ 2600468546 NM_TME_NM_State 0;
BA_ "GenSigSwitchedByIgnition" SG_ 2600468546 NM_TME_Car_Wakeup 0;
BA_ "GenSigSendType" SG_ 2600468546 NM_TME_Car_Wakeup 3;
BA_ "GenSigSwitchedByIgnition" SG_ 2600468546 NM_TME_UDS_CC 0;
BA_ "GenSigSwitchedByIgnition" SG_ 2600468546 NM_TME_NM_aktiv_KL15 0;
BA_ "GenSigSwitchedByIgnition" SG_ 2600468546 NM_TME_NM_aktiv_Diagnose 0;
BA_ "GenSigSwitchedByIgnition" SG_ 2600468546 NM_TME_NM_aktiv_Tmin 0;
BA_ "GenSigSwitchedByIgnition" SG_ 2600468546 NM_TME_NM_aktiv_Berechnung 0;
BA_ "GenSigSwitchedByIgnition" SG_ 2600468546 NM_TME_NM_aktiv_Vorkondition 0;
BA_ "GenSigSwitchedByIgnition" SG_ 2600468546 NM_TME_NM_aktiv_HV_Auszeitber 0;
BA_ "GenSigSwitchedByIgnition" SG_ 2600468546 NM_TME_NM_aktiv_Ventilsteuerung 0;
BA_ "GenSigSwitchedByIgnition" SG_ 2600468546 NM_TME_NM_aktiv_Kuehlung 0;
BA_ "GenSigSendType" SG_ 2600468546 NM_TME_NM_aktiv_Kuehlung 0;
BA_ "GenSigSwitchedByIgnition" SG_ 2600468546 NM_TME_CAB 0;
BA_ "GenSigSendType" SG_ 2600468546 NM_TME_CAB 4;
BA_ "GenSigActiveRepetitions" SG_ 2600468546 NM_TME_CAB 3;
BA_ "GenSigSwitchedByIgnition" SG_ 1635 BEM_02_Abschaltstufen 0;
BA_ "GenSigSendType" SG_ 1635 BEM_02_Abschaltstufen 0;
BA_ "Fehlerwert" SG_ 1635 BEM_STH_Zielzeit 15;
BA_ "GenSigSwitchedByIgnition" SG_ 1635 BEM_STH_Zielzeit 0;
BA_ "GenSigStartValue" SG_ 1635 BEM_STH_Zielzeit 14;
BA_ "GenSigSendType" SG_ 1635 BEM_STH_Zielzeit 0;
BA_ "GenSigSwitchedByIgnition" SG_ 1635 BEM_MMI_Vorwarnung 0;
BA_ "GenSigSendType" SG_ 1635 BEM_MMI_Vorwarnung 0;
BA_ "GenSigSwitchedByIgnition" SG_ 1635 NVEM_Anf_SD_schalten 0;
BA_ "GenSigSendType" SG_ 1635 NVEM_Anf_SD_schalten 0;
BA_ "GenSigSwitchedByIgnition" SG_ 1635 BEM_Generatordiagnose 0;
BA_ "GenSigSendType" SG_ 1635 BEM_Generatordiagnose 0;
BA_ "GenSigSwitchedByIgnition" SG_ 1635 BEM_Red_Innengeblaese 0;
BA_ "GenSigSendType" SG_ 1635 BEM_Red_Innengeblaese 0;
BA_ "GenSigSwitchedByIgnition" SG_ 1635 BEM_STH_Einschaltverbot 0;
BA_ "GenSigSendType" SG_ 1635 BEM_STH_Einschaltverbot 0;
BA_ "GenSigSwitchedByIgnition" SG_ 1635 BEM_HL_Regelung_Status 0;
BA_ "GenSigSendType" SG_ 1635 BEM_HL_Regelung_Status 0;
BA_ "Fehlerwert" SG_ 1635 BEM_Ladezustand 15;
BA_ "GenSigSwitchedByIgnition" SG_ 1635 BEM_Ladezustand 0;
BA_ "GenSigStartValue" SG_ 1635 BEM_Ladezustand 14;
BA_ "GenSigSendType" SG_ 1635 BEM_Ladezustand 0;
BA_ "Fehlerwert" SG_ 1635 BEM_Batteriediagnose 7;
BA_ "GenSigSwitchedByIgnition" SG_ 1635 BEM_Batteriediagnose 0;
BA_ "GenSigSendType" SG_ 1635 BEM_Batteriediagnose 0;
BA_ "GenSigSwitchedByIgnition" SG_ 1635 MIB_Stromsparmodus 0;
BA_ "GenSigSendType" SG_ 1635 MIB_Stromsparmodus 0;
BA_ "GenSigSwitchedByIgnition" SG_ 1635 BEM_REK_aktiv 0;
BA_ "GenSigSendType" SG_ 1635 BEM_REK_aktiv 0;
BA_ "GenSigSwitchedByIgnition" SG_ 1635 NVEM_Last_Anf 0;
BA_ "GenSigSendType" SG_ 1635 NVEM_Last_Anf 0;
BA_ "Fehlerwert" SG_ 1635 BEM_UBDM 255;
BA_ "GenSigSwitchedByIgnition" SG_ 1635 BEM_UBDM 0;
BA_ "GenSigSendType" SG_ 1635 BEM_UBDM 0;
BA_ "GenSigSwitchedByIgnition" SG_ 1635 BEM_UGenSoll 0;
BA_ "GenSigSendType" SG_ 1635 BEM_UGenSoll 0;
BA_ "GenSigSwitchedByIgnition" SG_ 1635 BEM_Anf_KL15_schalten 0;
BA_ "GenSigSendType" SG_ 1635 BEM_Anf_KL15_schalten 0;
BA_ "GenSigSwitchedByIgnition" SG_ 1635 NVEM_Batterie_Service 0;
BA_ "GenSigSendType" SG_ 1635 NVEM_Batterie_Service 0;
BA_ "GenSigSwitchedByIgnition" SG_ 1635 NVEM_Freigabe_OnlineUpdate 0;
BA_ "GenSigSendType" SG_ 1635 NVEM_Freigabe_OnlineUpdate 0;
BA_ "GenSigSwitchedByIgnition" SG_ 1635 NVEM_Freigabe_ORU4 0;
BA_ "GenSigSendType" SG_ 1635 NVEM_Freigabe_ORU4 0;
BA_ "GenSigSwitchedByIgnition" SG_ 869 NVEM_05_CRC 0;
BA_ "GenSigFuncType" SG_ 869 NVEM_05_CRC 2;
BA_ "GenSigSendType" SG_ 869 NVEM_05_CRC 0;
BA_ "GenSigSwitchedByIgnition" SG_ 869 NVEM_05_BZ 0;
BA_ "GenSigFuncType" SG_ 869 NVEM_05_BZ 1;
BA_ "GenSigSendType" SG_ 869 NVEM_05_BZ 0;
BA_ "GenSigSwitchedByIgnition" SG_ 869 NVEM_Pilot_Info 0;
BA_ "GenSigSendType" SG_ 869 NVEM_Pilot_Info 0;
BA_ "GenSigSwitchedByIgnition" SG_ 869 NVEM_P_Generator_Status 0;
BA_ "GenSigSendType" SG_ 869 NVEM_P_Generator_Status 0;
BA_ "Fehlerwert" SG_ 869 BEM_P_Generator 255;
BA_ "GenSigSwitchedByIgnition" SG_ 869 BEM_P_Generator 0;
BA_ "GenSigSendType" SG_ 869 BEM_P_Generator 0;
BA_ "GenSigSwitchedByIgnition" SG_ 869 BEM_n_LLA 0;
BA_ "GenSigSendType" SG_ 869 BEM_n_LLA 0;
BA_ "GenSigSwitchedByIgnition" SG_ 869 BEM_Anf_KL 0;
BA_ "GenSigSendType" SG_ 869 BEM_Anf_KL 0;
BA_ "GenSigSwitchedByIgnition" SG_ 869 BEM_StartStopp_Info 0;
BA_ "GenSigSendType" SG_ 869 BEM_StartStopp_Info 0;
BA_ "GenSigSwitchedByIgnition" SG_ 869 BEM_DFM 0;
BA_ "GenSigSendType" SG_ 869 BEM_DFM 0;
BA_ "GenSigSwitchedByIgnition" SG_ 869 BEM_Batt_Ab 0;
BA_ "GenSigSendType" SG_ 869 BEM_Batt_Ab 0;
BA_ "GenSigSwitchedByIgnition" SG_ 869 BEM_Hybrid_Info 0;
BA_ "GenSigSendType" SG_ 869 BEM_Hybrid_Info 0;
BA_ "GenSigSwitchedByIgnition" SG_ 869 NVEM_Red_KL 0;
BA_ "GenSigSendType" SG_ 869 NVEM_Red_KL 0;
BA_ "GenSigSwitchedByIgnition" SG_ 869 NVEM_Freilauf_Info 0;
BA_ "GenSigSendType" SG_ 869 NVEM_Freilauf_Info 0;
BA_ "GenSigSwitchedByIgnition" SG_ 869 BEM_HYB_DC_uSollLV 0;
BA_ "GenSigStartValue" SG_ 869 BEM_HYB_DC_uSollLV 37;
BA_ "GenSigSendType" SG_ 869 BEM_HYB_DC_uSollLV 0;
BA_ "Fehlerwert" SG_ 869 BEM_HYB_DC_uMinLV 255;
BA_ "GenSigSwitchedByIgnition" SG_ 869 BEM_HYB_DC_uMinLV 0;
BA_ "GenSigStartValue" SG_ 869 BEM_HYB_DC_uMinLV 254;
BA_ "GenSigSendType" SG_ 869 BEM_HYB_DC_uMinLV 0;
BA_ "GenSigSwitchedByIgnition" SG_ 2527679508 NVEM_06_CRC 0;
BA_ "GenSigFuncType" SG_ 2527679508 NVEM_06_CRC 2;
BA_ "GenSigSendType" SG_ 2527679508 NVEM_06_CRC 0;
BA_ "GenSigSwitchedByIgnition" SG_ 2527679508 NVEM_06_BZ 0;
BA_ "GenSigFuncType" SG_ 2527679508 NVEM_06_BZ 1;
BA_ "GenSigSendType" SG_ 2527679508 NVEM_06_BZ 0;
BA_ "GenSigSwitchedByIgnition" SG_ 2527679508 NVEM_Max_Rampenzeit 0;
BA_ "GenSigStartValue" SG_ 2527679508 NVEM_Max_Rampenzeit 6;
BA_ "GenSigSendType" SG_ 2527679508 NVEM_Max_Rampenzeit 0;
BA_ "Fehlerwert" SG_ 2527679508 NVEM_Min_Spannung 127;
BA_ "GenSigSwitchedByIgnition" SG_ 2527679508 NVEM_Min_Spannung 0;
BA_ "GenSigStartValue" SG_ 2527679508 NVEM_Min_Spannung 126;
BA_ "GenSigSendType" SG_ 2527679508 NVEM_Min_Spannung 0;
BA_ "Fehlerwert" SG_ 2527679508 NVEM_Min_Spannung_Start 63;
BA_ "GenSigSwitchedByIgnition" SG_ 2527679508 NVEM_Min_Spannung_Start 0;
BA_ "GenSigStartValue" SG_ 2527679508 NVEM_Min_Spannung_Start 62;
BA_ "GenSigSendType" SG_ 2527679508 NVEM_Min_Spannung_Start 3;
BA_ "Fehlerwert" SG_ 2527679508 NVEM_Max_Spannung 127;
BA_ "GenSigSwitchedByIgnition" SG_ 2527679508 NVEM_Max_Spannung 0;
BA_ "GenSigStartValue" SG_ 2527679508 NVEM_Max_Spannung 126;
BA_ "GenSigSendType" SG_ 2527679508 NVEM_Max_Spannung 0;
BA_ "Fehlerwert" SG_ 2527679508 NVEM_Energie_Klima_Vorgabe 255;
BA_ "GenSigSwitchedByIgnition" SG_ 2527679508 NVEM_Energie_Klima_Vorgabe 0;
BA_ "GenSigStartValue" SG_ 2527679508 NVEM_Energie_Klima_Vorgabe 254;
BA_ "GenSigSendType" SG_ 2527679508 NVEM_Energie_Klima_Vorgabe 0;
BA_ "Fehlerwert" SG_ 2527679508 NVEM_MV_DC_uMinLV 127;
BA_ "GenSigSwitchedByIgnition" SG_ 2527679508 NVEM_MV_DC_uMinLV 0;
BA_ "GenSigStartValue" SG_ 2527679508 NVEM_MV_DC_uMinLV 126;
BA_ "GenSigSendType" SG_ 2527679508 NVEM_MV_DC_uMinLV 0;
BA_ "Fehlerwert" SG_ 2527679508 NVEM_MV_DC_uSollLV 127;
BA_ "GenSigSwitchedByIgnition" SG_ 2527679508 NVEM_MV_DC_uSollLV 0;
BA_ "GenSigStartValue" SG_ 2527679508 NVEM_MV_DC_uSollLV 126;
BA_ "GenSigSendType" SG_ 2527679508 NVEM_MV_DC_uSollLV 0;
BA_ "GenSigSwitchedByIgnition" SG_ 2527679508 NVEM_Bordnetzdiagnose 0;
BA_ "GenSigSendType" SG_ 2527679508 NVEM_Bordnetzdiagnose 0;
BA_ "GenSigSwitchedByIgnition" SG_ 2527679509 NVEM_07_CRC 0;
BA_ "GenSigFuncType" SG_ 2527679509 NVEM_07_CRC 2;
BA_ "GenSigSendType" SG_ 2527679509 NVEM_07_CRC 0;
BA_ "GenSigSwitchedByIgnition" SG_ 2527679509 NVEM_07_BZ 0;
BA_ "GenSigFuncType" SG_ 2527679509 NVEM_07_BZ 1;
BA_ "GenSigSendType" SG_ 2527679509 NVEM_07_BZ 0;
BA_ "Fehlerwert" SG_ 2527679509 NVEM_BMS_NV_Imax_RSG_Anf 63;
BA_ "GenSigSwitchedByIgnition" SG_ 2527679509 NVEM_BMS_NV_Imax_RSG_Anf 0;
BA_ "GenSigStartValue" SG_ 2527679509 NVEM_BMS_NV_Imax_RSG_Anf 62;
BA_ "GenSigSendType" SG_ 2527679509 NVEM_BMS_NV_Imax_RSG_Anf 3;
BA_ "Fehlerwert" SG_ 2527679509 NVEM_BMS_NV_Umin_RSG_Anf 63;
BA_ "GenSigSwitchedByIgnition" SG_ 2527679509 NVEM_BMS_NV_Umin_RSG_Anf 0;
BA_ "GenSigStartValue" SG_ 2527679509 NVEM_BMS_NV_Umin_RSG_Anf 62;
BA_ "GenSigSendType" SG_ 2527679509 NVEM_BMS_NV_Umin_RSG_Anf 3;
BA_ "Fehlerwert" SG_ 2527679509 NVEM_BMS_NV_Nachlaufzeit_Vorgabe 63;
BA_ "GenSigSwitchedByIgnition" SG_ 2527679509 NVEM_BMS_NV_Nachlaufzeit_Vorgabe 0;
BA_ "GenSigStartValue" SG_ 2527679509 NVEM_BMS_NV_Nachlaufzeit_Vorgabe 62;
BA_ "GenSigSendType" SG_ 2527679509 NVEM_BMS_NV_Nachlaufzeit_Vorgabe 3;
BA_ "Fehlerwert" SG_ 2527679509 NVEM_BMS_NV_Umin_Anf 63;
BA_ "GenSigSwitchedByIgnition" SG_ 2527679509 NVEM_BMS_NV_Umin_Anf 0;
BA_ "GenSigStartValue" SG_ 2527679509 NVEM_BMS_NV_Umin_Anf 62;
BA_ "GenSigSendType" SG_ 2527679509 NVEM_BMS_NV_Umin_Anf 3;
BA_ "Fehlerwert" SG_ 2527679509 NVEM_FMAus_I_Verbrauch 31;
BA_ "GenSigSwitchedByIgnition" SG_ 2527679509 NVEM_FMAus_I_Verbrauch 0;
BA_ "GenSigStartValue" SG_ 2527679509 NVEM_FMAus_I_Verbrauch 30;
BA_ "GenSigSendType" SG_ 2527679509 NVEM_FMAus_I_Verbrauch 0;
BA_ "GenSigSwitchedByIgnition" SG_ 2527679509 NVEM_BMS_NV_Impuls_Abfrage 0;
BA_ "GenSigSendType" SG_ 2527679509 NVEM_BMS_NV_Impuls_Abfrage 3;
BA_ "GenSigSwitchedByIgnition" SG_ 2527679509 NVEM_BMS_NV_Sollmodus 0;
BA_ "GenSigStartValue" SG_ 2527679509 NVEM_BMS_NV_Sollmodus 3;
BA_ "GenSigSendType" SG_ 2527679509 NVEM_BMS_NV_Sollmodus 3;
BA_ "Fehlerwert" SG_ 527 NVEM_DC_uSoll_NV 255;
BA_ "GenSigSwitchedByIgnition" SG_ 527 NVEM_DC_uSoll_NV 0;
BA_ "GenSigStartValue" SG_ 527 NVEM_DC_uSoll_NV 116;
BA_ "GenSigSendType" SG_ 527 NVEM_DC_uSoll_NV 0;
BA_ "GenSigSwitchedByIgnition" SG_ 913 OBD_Calc_Load_Val 0;
BA_ "GenSigStartValue" SG_ 913 OBD_Calc_Load_Val 255;
BA_ "GenSigSendType" SG_ 913 OBD_Calc_Load_Val 0;
BA_ "GenSigSwitchedByIgnition" SG_ 913 OBD_Eng_Cool_Temp 0;
BA_ "GenSigStartValue" SG_ 913 OBD_Eng_Cool_Temp 255;
BA_ "GenSigSendType" SG_ 913 OBD_Eng_Cool_Temp 0;
BA_ "GenSigSwitchedByIgnition" SG_ 913 OBD_Abs_Throttle_Pos 0;
BA_ "GenSigStartValue" SG_ 913 OBD_Abs_Throttle_Pos 255;
BA_ "GenSigSendType" SG_ 913 OBD_Abs_Throttle_Pos 0;
BA_ "GenSigSwitchedByIgnition" SG_ 913 OBD_Abs_Load_Val 0;
BA_ "GenSigStartValue" SG_ 913 OBD_Abs_Load_Val 65535;
BA_ "GenSigSendType" SG_ 913 OBD_Abs_Load_Val 0;
BA_ "GenSigSwitchedByIgnition" SG_ 913 OBD_Abs_Pedal_Pos 0;
BA_ "GenSigStartValue" SG_ 913 OBD_Abs_Pedal_Pos 255;
BA_ "GenSigSendType" SG_ 913 OBD_Abs_Pedal_Pos 0;
BA_ "GenSigSendType" SG_ 913 MO_Servicemodus 0;
BA_ "GenSigSwitchedByIgnition" SG_ 913 OBD_ClearMem_Inhibit 0;
BA_ "GenSigSendType" SG_ 913 OBD_ClearMem_Inhibit 0;
BA_ "GenSigSwitchedByIgnition" SG_ 913 OBD_Sperrung_Kaltstart_Denom 0;
BA_ "GenSigSendType" SG_ 913 OBD_Sperrung_Kaltstart_Denom 0;
BA_ "GenSigSwitchedByIgnition" SG_ 913 MO_QBit_Aussen_Temp 0;
BA_ "GenSigStartValue" SG_ 913 MO_QBit_Aussen_Temp 1;
BA_ "GenSigSendType" SG_ 913 MO_QBit_Aussen_Temp 0;
BA_ "GenSigSwitchedByIgnition" SG_ 913 OBD_Sperrung_IUMPR 0;
BA_ "GenSigSendType" SG_ 913 OBD_Sperrung_IUMPR 0;
BA_ "GenSigSwitchedByIgnition" SG_ 913 OBD_Kaltstart_Denominator 0;
BA_ "GenSigSendType" SG_ 913 OBD_Kaltstart_Denominator 0;
BA_ "GenSigSwitchedByIgnition" SG_ 913 OBD_Minimum_Trip 0;
BA_ "GenSigSendType" SG_ 913 OBD_Minimum_Trip 0;
BA_ "GenSigSwitchedByIgnition" SG_ 913 OBD_Driving_Cycle 0;
BA_ "GenSigSendType" SG_ 913 OBD_Driving_Cycle 0;
BA_ "GenSigSwitchedByIgnition" SG_ 913 OBD_Warm_Up_Cycle 0;
BA_ "GenSigSendType" SG_ 913 OBD_Warm_Up_Cycle 0;
BA_ "GenSigSwitchedByIgnition" SG_ 913 OBD_Normed_Trip 0;
BA_ "GenSigSendType" SG_ 913 OBD_Normed_Trip 0;
BA_ "GenSigSwitchedByIgnition" SG_ 2549875343 OBDC_AWC_Req_Data 0;
BA_ "GenSigSendType" SG_ 2549875343 OBDC_AWC_Req_Data 3;
BA_ "GenSigSwitchedByIgnition" SG_ 2550006415 OBDC_AWC_Resp_Data 0;
BA_ "GenSigSendType" SG_ 2550006415 OBDC_AWC_Resp_Data 3;
BA_ "GenSigSwitchedByIgnition" SG_ 2549875374 OBDC_BattRegelung_Req_Data 0;
BA_ "GenSigFuncType" SG_ 2549875374 OBDC_BattRegelung_Req_Data 9;
BA_ "GenSigSendType" SG_ 2549875374 OBDC_BattRegelung_Req_Data 3;
BA_ "GenSigSwitchedByIgnition" SG_ 2550006446 OBDC_BattRegelung_Resp_Data 0;
BA_ "GenSigFuncType" SG_ 2550006446 OBDC_BattRegelung_Resp_Data 9;
BA_ "GenSigSendType" SG_ 2550006446 OBDC_BattRegelung_Resp_Data 3;
BA_ "GenSigSwitchedByIgnition" SG_ 2549875356 OBDC_BMS_48V_Req_Data 0;
BA_ "GenSigSendType" SG_ 2549875356 OBDC_BMS_48V_Req_Data 3;
BA_ "GenSigSwitchedByIgnition" SG_ 2550006428 OBDC_BMS_48V_Resp_Data 0;
BA_ "GenSigSendType" SG_ 2550006428 OBDC_BMS_48V_Resp_Data 3;
BA_ "GenSigSwitchedByIgnition" SG_ 2549875399 OBDC_DCDC_HV_02_Req_Data 0;
BA_ "GenSigSendType" SG_ 2549875399 OBDC_DCDC_HV_02_Req_Data 3;
BA_ "GenSigSwitchedByIgnition" SG_ 2550006471 OBDC_DCDC_HV_02_Resp_Data 0;
BA_ "GenSigSendType" SG_ 2550006471 OBDC_DCDC_HV_02_Resp_Data 3;
BA_ "GenSigSwitchedByIgnition" SG_ 2549875407 OBDC_DCDC_HV_03_Req_Data 0;
BA_ "GenSigSendType" SG_ 2549875407 OBDC_DCDC_HV_03_Req_Data 3;
BA_ "GenSigSwitchedByIgnition" SG_ 2550006479 OBDC_DCDC_HV_03_Resp_Data 0;
BA_ "GenSigSendType" SG_ 2550006479 OBDC_DCDC_HV_03_Resp_Data 3;
BA_ "GenSigSwitchedByIgnition" SG_ 2549875383 OBDC_DCDC_HV_Req_Data 0;
BA_ "GenSigFuncType" SG_ 2549875383 OBDC_DCDC_HV_Req_Data 9;
BA_ "GenSigSendType" SG_ 2549875383 OBDC_DCDC_HV_Req_Data 3;
BA_ "GenSigSwitchedByIgnition" SG_ 2550006455 OBDC_DCDC_HV_Resp_Data 0;
BA_ "GenSigSendType" SG_ 2550006455 OBDC_DCDC_HV_Resp_Data 3;
BA_ "GenSigSwitchedByIgnition" SG_ 2549875265 OBDC_DCDC_Req_Data 0;
BA_ "GenSigSendType" SG_ 2549875265 OBDC_DCDC_Req_Data 3;
BA_ "GenSigSwitchedByIgnition" SG_ 2550006337 OBDC_DCDC_Resp_Data 0;
BA_ "GenSigSendType" SG_ 2550006337 OBDC_DCDC_Resp_Data 3;
BA_ "GenSigSwitchedByIgnition" SG_ 2549875381 OBDC_FCU_Req_Data 0;
BA_ "GenSigSendType" SG_ 2549875381 OBDC_FCU_Req_Data 3;
BA_ "GenSigSwitchedByIgnition" SG_ 2550006453 OBDC_FCU_Resp_Data 0;
BA_ "GenSigSendType" SG_ 2550006453 OBDC_FCU_Resp_Data 3;
BA_ "GenSigSwitchedByIgnition" SG_ 2549940736 OBDC_Funktionaler_Req_All_Data 0;
BA_ "GenSigFuncType" SG_ 2549940736 OBDC_Funktionaler_Req_All_Data 9;
BA_ "GenSigSendType" SG_ 2549940736 OBDC_Funktionaler_Req_All_Data 3;
BA_ "GenSigSwitchedByIgnition" SG_ 2549875323 OBDC_Hybrid_01_Req_Data 0;
BA_ "GenSigFuncType" SG_ 2549875323 OBDC_Hybrid_01_Req_Data 9;
BA_ "GenSigSendType" SG_ 2549875323 OBDC_Hybrid_01_Req_Data 3;
BA_ "GenSigSwitchedByIgnition" SG_ 2550006395 OBDC_Hybrid_01_Resp_Data 0;
BA_ "GenSigFuncType" SG_ 2550006395 OBDC_Hybrid_01_Resp_Data 9;
BA_ "GenSigSendType" SG_ 2550006395 OBDC_Hybrid_01_Resp_Data 3;
BA_ "GenSigSwitchedByIgnition" SG_ 2549875398 OBDC_Ladegeraet_2_Req_Data 0;
BA_ "GenSigSendType" SG_ 2549875398 OBDC_Ladegeraet_2_Req_Data 3;
BA_ "GenSigSwitchedByIgnition" SG_ 2550006470 OBDC_Ladegeraet_2_Resp_Data 0;
BA_ "GenSigSendType" SG_ 2550006470 OBDC_Ladegeraet_2_Resp_Data 3;
BA_ "GenSigSwitchedByIgnition" SG_ 2549875268 OBDC_Ladegeraet_Req_Data 0;
BA_ "GenSigFuncType" SG_ 2549875268 OBDC_Ladegeraet_Req_Data 9;
BA_ "GenSigSendType" SG_ 2549875268 OBDC_Ladegeraet_Req_Data 3;
BA_ "GenSigSwitchedByIgnition" SG_ 2550006340 OBDC_Ladegeraet_Resp_Data 0;
BA_ "GenSigFuncType" SG_ 2550006340 OBDC_Ladegeraet_Resp_Data 9;
BA_ "GenSigSendType" SG_ 2550006340 OBDC_Ladegeraet_Resp_Data 3;
BA_ "GenSigSwitchedByIgnition" SG_ 2549903568 OBDC_SSN_BJB_Req_Data 0;
BA_ "GenSigFuncType" SG_ 2549903568 OBDC_SSN_BJB_Req_Data 9;
BA_ "GenSigSendType" SG_ 2549903568 OBDC_SSN_BJB_Req_Data 3;
BA_ "GenSigSwitchedByIgnition" SG_ 2550034640 OBDC_SSN_BJB_Resp_Data 0;
BA_ "GenSigFuncType" SG_ 2550034640 OBDC_SSN_BJB_Resp_Data 9;
BA_ "GenSigSendType" SG_ 2550034640 OBDC_SSN_BJB_Resp_Data 3;
BA_ "GenSigSwitchedByIgnition" SG_ 2549903569 OBDC_SSN_CMC_01_Req_Data 0;
BA_ "GenSigFuncType" SG_ 2549903569 OBDC_SSN_CMC_01_Req_Data 9;
BA_ "GenSigSendType" SG_ 2549903569 OBDC_SSN_CMC_01_Req_Data 3;
BA_ "GenSigSwitchedByIgnition" SG_ 2550034641 OBDC_SSN_CMC_01_Resp_Data 0;
BA_ "GenSigFuncType" SG_ 2550034641 OBDC_SSN_CMC_01_Resp_Data 9;
BA_ "GenSigSendType" SG_ 2550034641 OBDC_SSN_CMC_01_Resp_Data 3;
BA_ "GenSigSwitchedByIgnition" SG_ 2549903570 OBDC_SSN_CMC_02_Req_Data 0;
BA_ "GenSigFuncType" SG_ 2549903570 OBDC_SSN_CMC_02_Req_Data 9;
BA_ "GenSigSendType" SG_ 2549903570 OBDC_SSN_CMC_02_Req_Data 3;
BA_ "GenSigSwitchedByIgnition" SG_ 2550034642 OBDC_SSN_CMC_02_Resp_Data 0;
BA_ "GenSigFuncType" SG_ 2550034642 OBDC_SSN_CMC_02_Resp_Data 9;
BA_ "GenSigSendType" SG_ 2550034642 OBDC_SSN_CMC_02_Resp_Data 3;
BA_ "GenSigSwitchedByIgnition" SG_ 2549903571 OBDC_SSN_CMC_03_Req_Data 0;
BA_ "GenSigFuncType" SG_ 2549903571 OBDC_SSN_CMC_03_Req_Data 9;
BA_ "GenSigSendType" SG_ 2549903571 OBDC_SSN_CMC_03_Req_Data 3;
BA_ "GenSigSwitchedByIgnition" SG_ 2550034643 OBDC_SSN_CMC_03_Resp_Data 0;
BA_ "GenSigFuncType" SG_ 2550034643 OBDC_SSN_CMC_03_Resp_Data 9;
BA_ "GenSigSendType" SG_ 2550034643 OBDC_SSN_CMC_03_Resp_Data 3;
BA_ "GenSigSwitchedByIgnition" SG_ 2549903572 OBDC_SSN_CMC_04_Req_Data 0;
BA_ "GenSigFuncType" SG_ 2549903572 OBDC_SSN_CMC_04_Req_Data 9;
BA_ "GenSigSendType" SG_ 2549903572 OBDC_SSN_CMC_04_Req_Data 3;
BA_ "GenSigSwitchedByIgnition" SG_ 2550034644 OBDC_SSN_CMC_04_Resp_Data 0;
BA_ "GenSigFuncType" SG_ 2550034644 OBDC_SSN_CMC_04_Resp_Data 9;
BA_ "GenSigSendType" SG_ 2550034644 OBDC_SSN_CMC_04_Resp_Data 3;
BA_ "GenSigSwitchedByIgnition" SG_ 2549903573 OBDC_SSN_CMC_05_Req_Data 0;
BA_ "GenSigFuncType" SG_ 2549903573 OBDC_SSN_CMC_05_Req_Data 9;
BA_ "GenSigSendType" SG_ 2549903573 OBDC_SSN_CMC_05_Req_Data 3;
BA_ "GenSigSwitchedByIgnition" SG_ 2550034645 OBDC_SSN_CMC_05_Resp_Data 0;
BA_ "GenSigFuncType" SG_ 2550034645 OBDC_SSN_CMC_05_Resp_Data 9;
BA_ "GenSigSendType" SG_ 2550034645 OBDC_SSN_CMC_05_Resp_Data 3;
BA_ "GenSigSwitchedByIgnition" SG_ 2549903574 OBDC_SSN_CMC_06_Req_Data 0;
BA_ "GenSigFuncType" SG_ 2549903574 OBDC_SSN_CMC_06_Req_Data 9;
BA_ "GenSigSendType" SG_ 2549903574 OBDC_SSN_CMC_06_Req_Data 3;
BA_ "GenSigSwitchedByIgnition" SG_ 2550034646 OBDC_SSN_CMC_06_Resp_Data 0;
BA_ "GenSigFuncType" SG_ 2550034646 OBDC_SSN_CMC_06_Resp_Data 9;
BA_ "GenSigSendType" SG_ 2550034646 OBDC_SSN_CMC_06_Resp_Data 3;
BA_ "GenSigSwitchedByIgnition" SG_ 2549903575 OBDC_SSN_CMC_07_Req_Data 0;
BA_ "GenSigFuncType" SG_ 2549903575 OBDC_SSN_CMC_07_Req_Data 9;
BA_ "GenSigSendType" SG_ 2549903575 OBDC_SSN_CMC_07_Req_Data 3;
BA_ "GenSigSwitchedByIgnition" SG_ 2550034647 OBDC_SSN_CMC_07_Resp_Data 0;
BA_ "GenSigFuncType" SG_ 2550034647 OBDC_SSN_CMC_07_Resp_Data 9;
BA_ "GenSigSendType" SG_ 2550034647 OBDC_SSN_CMC_07_Resp_Data 3;
BA_ "GenSigSwitchedByIgnition" SG_ 2549903576 OBDC_SSN_CMC_08_Req_Data 0;
BA_ "GenSigFuncType" SG_ 2549903576 OBDC_SSN_CMC_08_Req_Data 9;
BA_ "GenSigSendType" SG_ 2549903576 OBDC_SSN_CMC_08_Req_Data 3;
BA_ "GenSigSwitchedByIgnition" SG_ 2550034648 OBDC_SSN_CMC_08_Resp_Data 0;
BA_ "GenSigFuncType" SG_ 2550034648 OBDC_SSN_CMC_08_Resp_Data 9;
BA_ "GenSigSendType" SG_ 2550034648 OBDC_SSN_CMC_08_Resp_Data 3;
BA_ "GenSigSwitchedByIgnition" SG_ 2549903577 OBDC_SSN_CMC_09_Req_Data 0;
BA_ "GenSigFuncType" SG_ 2549903577 OBDC_SSN_CMC_09_Req_Data 9;
BA_ "GenSigSendType" SG_ 2549903577 OBDC_SSN_CMC_09_Req_Data 3;
BA_ "GenSigSwitchedByIgnition" SG_ 2550034649 OBDC_SSN_CMC_09_Resp_Data 0;
BA_ "GenSigFuncType" SG_ 2550034649 OBDC_SSN_CMC_09_Resp_Data 9;
BA_ "GenSigSendType" SG_ 2550034649 OBDC_SSN_CMC_09_Resp_Data 3;
BA_ "GenSigSwitchedByIgnition" SG_ 2549903578 OBDC_SSN_CMC_10_Req_Data 0;
BA_ "GenSigFuncType" SG_ 2549903578 OBDC_SSN_CMC_10_Req_Data 9;
BA_ "GenSigSendType" SG_ 2549903578 OBDC_SSN_CMC_10_Req_Data 3;
BA_ "GenSigSwitchedByIgnition" SG_ 2550034650 OBDC_SSN_CMC_10_Resp_Data 0;
BA_ "GenSigFuncType" SG_ 2550034650 OBDC_SSN_CMC_10_Resp_Data 9;
BA_ "GenSigSendType" SG_ 2550034650 OBDC_SSN_CMC_10_Resp_Data 3;
BA_ "GenSigSwitchedByIgnition" SG_ 2549903579 OBDC_SSN_CMC_11_Req_Data 0;
BA_ "GenSigFuncType" SG_ 2549903579 OBDC_SSN_CMC_11_Req_Data 9;
BA_ "GenSigSendType" SG_ 2549903579 OBDC_SSN_CMC_11_Req_Data 3;
BA_ "GenSigSwitchedByIgnition" SG_ 2550034651 OBDC_SSN_CMC_11_Resp_Data 0;
BA_ "GenSigFuncType" SG_ 2550034651 OBDC_SSN_CMC_11_Resp_Data 9;
BA_ "GenSigSendType" SG_ 2550034651 OBDC_SSN_CMC_11_Resp_Data 3;
BA_ "GenSigSwitchedByIgnition" SG_ 2549903580 OBDC_SSN_CMC_12_Req_Data 0;
BA_ "GenSigFuncType" SG_ 2549903580 OBDC_SSN_CMC_12_Req_Data 9;
BA_ "GenSigSendType" SG_ 2549903580 OBDC_SSN_CMC_12_Req_Data 3;
BA_ "GenSigSwitchedByIgnition" SG_ 2550034652 OBDC_SSN_CMC_12_Resp_Data 0;
BA_ "GenSigFuncType" SG_ 2550034652 OBDC_SSN_CMC_12_Resp_Data 9;
BA_ "GenSigSendType" SG_ 2550034652 OBDC_SSN_CMC_12_Resp_Data 3;
BA_ "GenSigSwitchedByIgnition" SG_ 2549903601 OBDC_SSN_CMC_13_Req_Data 0;
BA_ "GenSigFuncType" SG_ 2549903601 OBDC_SSN_CMC_13_Req_Data 9;
BA_ "GenSigSendType" SG_ 2549903601 OBDC_SSN_CMC_13_Req_Data 3;
BA_ "GenSigSwitchedByIgnition" SG_ 2550034673 OBDC_SSN_CMC_13_Resp_Data 0;
BA_ "GenSigFuncType" SG_ 2550034673 OBDC_SSN_CMC_13_Resp_Data 9;
BA_ "GenSigSendType" SG_ 2550034673 OBDC_SSN_CMC_13_Resp_Data 3;
BA_ "GenSigSwitchedByIgnition" SG_ 2549903602 OBDC_SSN_CMC_14_Req_Data 0;
BA_ "GenSigFuncType" SG_ 2549903602 OBDC_SSN_CMC_14_Req_Data 9;
BA_ "GenSigSendType" SG_ 2549903602 OBDC_SSN_CMC_14_Req_Data 3;
BA_ "GenSigSwitchedByIgnition" SG_ 2550034674 OBDC_SSN_CMC_14_Resp_Data 0;
BA_ "GenSigFuncType" SG_ 2550034674 OBDC_SSN_CMC_14_Resp_Data 9;
BA_ "GenSigSendType" SG_ 2550034674 OBDC_SSN_CMC_14_Resp_Data 3;
BA_ "GenSigSwitchedByIgnition" SG_ 2549903603 OBDC_SSN_CMC_15_Req_Data 0;
BA_ "GenSigFuncType" SG_ 2549903603 OBDC_SSN_CMC_15_Req_Data 9;
BA_ "GenSigSendType" SG_ 2549903603 OBDC_SSN_CMC_15_Req_Data 3;
BA_ "GenSigSwitchedByIgnition" SG_ 2550034675 OBDC_SSN_CMC_15_Resp_Data 0;
BA_ "GenSigFuncType" SG_ 2550034675 OBDC_SSN_CMC_15_Resp_Data 9;
BA_ "GenSigSendType" SG_ 2550034675 OBDC_SSN_CMC_15_Resp_Data 3;
BA_ "GenSigSwitchedByIgnition" SG_ 2549875380 OBDC_TelemetrieSG_Req_Data 0;
BA_ "GenSigFuncType" SG_ 2549875380 OBDC_TelemetrieSG_Req_Data 9;
BA_ "GenSigSendType" SG_ 2549875380 OBDC_TelemetrieSG_Req_Data 3;
BA_ "GenSigSwitchedByIgnition" SG_ 2550006452 OBDC_TelemetrieSG_Resp_Data 0;
BA_ "GenSigFuncType" SG_ 2550006452 OBDC_TelemetrieSG_Resp_Data 9;
BA_ "GenSigSendType" SG_ 2550006452 OBDC_TelemetrieSG_Resp_Data 3;
BA_ "GenSigSwitchedByIgnition" SG_ 2549875266 OBDC_TME_Req_Data 0;
BA_ "GenSigFuncType" SG_ 2549875266 OBDC_TME_Req_Data 9;
BA_ "GenSigSendType" SG_ 2549875266 OBDC_TME_Req_Data 3;
BA_ "GenSigSwitchedByIgnition" SG_ 2550006338 OBDC_TME_Resp_Data 0;
BA_ "GenSigFuncType" SG_ 2550006338 OBDC_TME_Resp_Data 9;
BA_ "GenSigSendType" SG_ 2550006338 OBDC_TME_Resp_Data 3;
BA_ "GenSigSwitchedByIgnition" SG_ 2589283656 ORU_Warnung 0;
BA_ "GenSigSendType" SG_ 2589283656 ORU_Warnung 3;
BA_ "GenSigSwitchedByIgnition" SG_ 2589283656 ORU_Status 0;
BA_ "GenSigSendType" SG_ 2589283656 ORU_Status 3;
BA_ "Fehlerwert" SG_ 872 PH2_Visualisierung 7;
BA_ "GenSigStartValue" SG_ 872 PH2_Visualisierung 6;
BA_ "GenSigSendType" SG_ 872 PH2_Visualisierung 3;
BA_ "GenSigSendType" SG_ 872 PDC2_Tonausgabe_Front 0;
BA_ "GenSigSendType" SG_ 872 PDC2_Tonausgabe_Heck 0;
BA_ "GenSigSendType" SG_ 872 PH2_nachtr_Stopp_An 0;
BA_ "GenSigSendType" SG_ 872 PH2_Abschaltursache 3;
BA_ "GenSigSendType" SG_ 872 PH2_Opt_Anzeige_V_ein 0;
BA_ "GenSigSendType" SG_ 872 PH2_Opt_Anzeige_H_ein 0;
BA_ "GenSigSendType" SG_ 872 PH2_Opt_Anz_V_Hindernis 0;
BA_ "GenSigSendType" SG_ 872 PH2_Opt_Anz_H_Hindernis 0;
BA_ "GenSigSendType" SG_ 872 PH2_Tongeber_V_aktiv 0;
BA_ "GenSigSendType" SG_ 872 PH2_Tongeber_H_aktiv 0;
BA_ "GenSigSendType" SG_ 872 PH2_Tongeber_mute 0;
BA_ "GenSigSendType" SG_ 872 PH2_Anf_Audioabsenkung 0;
BA_ "GenSigSendType" SG_ 872 PH2_Tongeber_H_verfuegbar 0;
BA_ "Fehlerwert" SG_ 872 PH2_Taster 3;
BA_ "GenSigSendType" SG_ 872 PH2_Taster 0;
BA_ "GenSigSendType" SG_ 872 PH2_Anf_Verdeck 0;
BA_ "GenSigSendType" SG_ 872 PH2_Frequenz_hinten 0;
BA_ "GenSigSendType" SG_ 872 PH2_Lautstaerke_hinten 0;
BA_ "GenSigSendType" SG_ 872 PH2_Frequenz_vorn 0;
BA_ "GenSigSendType" SG_ 872 PH2_Lautstaerke_vorn 0;
BA_ "GenSigSendType" SG_ 872 PH2_StartStopp_Info 0;
BA_ "GenSigSendType" SG_ 872 PH2_Stoermeldung 0;
BA_ "GenSigSendType" SG_ 872 PH2_defekt 0;
BA_ "GenSigSendType" SG_ 872 PH2_gestoert 0;
BA_ "GenSigSendType" SG_ 872 PH2_Systemzustand 3;
BA_ "GenSigSendType" SG_ 872 PH2_Display_Kundenwunsch 0;
BA_ "GenSigSendType" SG_ 2463978617 PH2_Verschmutzungsmeldung 3;
BA_ "GenSigSendType" SG_ 2463978617 PH2_Aufschaltursache 3;
BA_ "GenSigSendType" SG_ 2463978617 PH2_WAH_Meldung 3;
BA_ "Fehlerwert" SG_ 1175 PH_Visualisierung 7;
BA_ "GenSigStartValue" SG_ 1175 PH_Visualisierung 6;
BA_ "GenSigSendType" SG_ 1175 PH_Visualisierung 3;
BA_ "GenSigSendType" SG_ 1175 PDC_Tonausgabe_Front 0;
BA_ "GenSigSendType" SG_ 1175 PDC_Tonausgabe_Heck 0;
BA_ "GenSigSendType" SG_ 1175 PH_nachtr_Stopp_Anf 0;
BA_ "GenSigSendType" SG_ 1175 PH_Abschaltursache 3;
BA_ "GenSigSendType" SG_ 1175 PH_Opt_Anzeige_V_ein 0;
BA_ "GenSigSendType" SG_ 1175 PH_Opt_Anzeige_H_ein 0;
BA_ "GenSigSendType" SG_ 1175 PH_Opt_Anz_V_Hindernis 0;
BA_ "GenSigSendType" SG_ 1175 PH_Opt_Anz_H_Hindernis 0;
BA_ "GenSigSendType" SG_ 1175 PH_Tongeber_V_aktiv 0;
BA_ "GenSigSendType" SG_ 1175 PH_Tongeber_H_aktiv 0;
BA_ "GenSigSendType" SG_ 1175 PH_Tongeber_mute 0;
BA_ "GenSigSendType" SG_ 1175 PH_Anf_Audioabsenkung 0;
BA_ "GenSigSendType" SG_ 1175 PH_Tongeber_H_verfuegbar 0;
BA_ "GenSigSendType" SG_ 1175 PLA_Anf_Aufschaltung_RVC 0;
BA_ "Fehlerwert" SG_ 1175 PH_Taster 3;
BA_ "GenSigSendType" SG_ 1175 PH_Taster 0;
BA_ "GenSigSendType" SG_ 1175 PH_Anf_Verdeck 0;
BA_ "GenSigSendType" SG_ 1175 PH_Frequenz_hinten 0;
BA_ "GenSigSendType" SG_ 1175 PH_Lautstaerke_hinten 0;
BA_ "GenSigSendType" SG_ 1175 PH_Frequenz_vorn 0;
BA_ "GenSigSendType" SG_ 1175 PH_Lautstaerke_vorn 0;
BA_ "GenSigSendType" SG_ 1175 PH_StartStopp_Info 0;
BA_ "GenSigSendType" SG_ 1175 PH_Stoermeldung 0;
BA_ "GenSigSendType" SG_ 1175 PH_defekt 0;
BA_ "GenSigSendType" SG_ 1175 PH_gestoert 0;
BA_ "GenSigSendType" SG_ 1175 PH_Systemzustand 3;
BA_ "GenSigSendType" SG_ 1175 PH_Display_Kundenwunsch 0;
BA_ "GenSigSendType" SG_ 1355 PH_Verschmutzungsmeldung 3;
BA_ "GenSigSendType" SG_ 1355 PH_Aufschaltursache 3;
BA_ "Fehlerwert" SG_ 1355 PH_Ton_Ausgabe 7;
BA_ "GenSigSendType" SG_ 1355 PH_Ton_Ausgabe 3;
BA_ "Fehlerwert" SG_ 1355 PH_Ton_Pausenlaenge 127;
BA_ "GenSigSendType" SG_ 1355 PH_Ton_Pausenlaenge 3;
BA_ "GenSigSendType" SG_ 1355 PH_Ton_Richtung 3;
BA_ "GenSigSendType" SG_ 1355 PH_Ton_Lautstaerke 3;
BA_ "GenSigSendType" SG_ 1355 BCM_WAH_Meldung 3;
BA_ "GenSigSendType" SG_ 1355 PDC_Charisma_Status 3;
BA_ "GenSigSendType" SG_ 1355 PDC_Charisma_FahrPr 3;
BA_ "GenSigSendType" SG_ 617 PIF_Toggle 0;
BA_ "GenSigSendType" SG_ 617 PIF_ST_Status 0;
BA_ "GenSigSendType" SG_ 617 PIF_MT_Status 0;
BA_ "GenSigSendType" SG_ 617 PIF_LT_Status 0;
BA_ "GenSigSendType" SG_ 617 PIF_Identifier 0;
BA_ "GenSigSendType" SG_ 617 PIF_ST_Bin_0 0;
BA_ "GenSigSendType" SG_ 617 PIF_ST_Bin_1 0;
BA_ "GenSigSendType" SG_ 617 PIF_ST_Bin_2 0;
BA_ "GenSigSendType" SG_ 617 PIF_ST_Bin_3 0;
BA_ "GenSigSendType" SG_ 617 PIF_ST_Bin_4 0;
BA_ "GenSigSendType" SG_ 617 PIF_ST_Bin_5 0;
BA_ "GenSigSendType" SG_ 617 PIF_ST_Bin_6 0;
BA_ "GenSigSendType" SG_ 617 PIF_ST_Bin_7 0;
BA_ "GenSigSendType" SG_ 617 PIF_ST_Bin_8 0;
BA_ "GenSigSendType" SG_ 617 PIF_MT_Bin_0 0;
BA_ "GenSigSendType" SG_ 617 PIF_MT_Bin_1 0;
BA_ "GenSigSendType" SG_ 617 PIF_MT_Bin_2 0;
BA_ "GenSigSendType" SG_ 617 PIF_MT_Bin_3 0;
BA_ "GenSigSendType" SG_ 617 PIF_MT_Bin_4 0;
BA_ "GenSigSendType" SG_ 617 PIF_MT_Bin_5 0;
BA_ "GenSigSendType" SG_ 617 PIF_MT_Bin_6 0;
BA_ "GenSigSendType" SG_ 617 PIF_MT_Bin_7 0;
BA_ "GenSigSendType" SG_ 617 PIF_MT_Bin_8 0;
BA_ "GenSigSendType" SG_ 617 PIF_LT_Bin_0 0;
BA_ "GenSigSendType" SG_ 617 PIF_LT_Bin_1 0;
BA_ "GenSigSendType" SG_ 617 PIF_LT_Bin_2 0;
BA_ "GenSigSendType" SG_ 617 PIF_LT_Bin_3 0;
BA_ "GenSigSendType" SG_ 617 PIF_LT_Bin_4 0;
BA_ "GenSigSendType" SG_ 617 PIF_LT_Bin_5 0;
BA_ "GenSigSendType" SG_ 617 PIF_LT_Bin_6 0;
BA_ "GenSigSendType" SG_ 617 PIF_LT_Bin_7 0;
BA_ "GenSigSendType" SG_ 617 PIF_LT_Bin_8 0;
BA_ "GenSigSwitchedByIgnition" SG_ 2549876804 PnC_Ladegeraet_Req_Data 0;
BA_ "GenSigSendType" SG_ 2549876804 PnC_Ladegeraet_Req_Data 3;
BA_ "GenSigSwitchedByIgnition" SG_ 2550007876 PnC_Ladegeraet_Resp_Data 0;
BA_ "GenSigSendType" SG_ 2550007876 PnC_Ladegeraet_Resp_Data 3;
BA_ "Fehlerwert" SG_ 2527679715 pVS_EnergieAnfr_Zaehler 15;
BA_ "GenSigSwitchedByIgnition" SG_ 2527679715 pVS_EnergieAnfr_Zaehler 0;
BA_ "GenSigStartValue" SG_ 2527679715 pVS_EnergieAnfr_Zaehler 14;
BA_ "GenSigSendType" SG_ 2527679715 pVS_EnergieAnfr_Zaehler 0;
BA_ "Fehlerwert" SG_ 2527679715 pVS_EnergieAnfr_SocStart 127;
BA_ "GenSigSwitchedByIgnition" SG_ 2527679715 pVS_EnergieAnfr_SocStart 0;
BA_ "GenSigStartValue" SG_ 2527679715 pVS_EnergieAnfr_SocStart 126;
BA_ "GenSigSendType" SG_ 2527679715 pVS_EnergieAnfr_SocStart 0;
BA_ "Fehlerwert" SG_ 2527679715 pVS_EnergieAnfr_SocZiel 127;
BA_ "GenSigSwitchedByIgnition" SG_ 2527679715 pVS_EnergieAnfr_SocZiel 0;
BA_ "GenSigStartValue" SG_ 2527679715 pVS_EnergieAnfr_SocZiel 126;
BA_ "GenSigSendType" SG_ 2527679715 pVS_EnergieAnfr_SocZiel 0;
BA_ "Fehlerwert" SG_ 2527679715 pVS_Zielklimamodus_Range_pers 7;
BA_ "GenSigSwitchedByIgnition" SG_ 2527679715 pVS_Zielklimamodus_Range_pers 0;
BA_ "GenSigStartValue" SG_ 2527679715 pVS_Zielklimamodus_Range_pers 6;
BA_ "GenSigSendType" SG_ 2527679715 pVS_Zielklimamodus_Range_pers 3;
BA_ "Fehlerwert" SG_ 2527679715 pVS_Zielklimamodus_Range 7;
BA_ "GenSigSwitchedByIgnition" SG_ 2527679715 pVS_Zielklimamodus_Range 0;
BA_ "GenSigStartValue" SG_ 2527679715 pVS_Zielklimamodus_Range 6;
BA_ "GenSigSendType" SG_ 2527679715 pVS_Zielklimamodus_Range 3;
BA_ "Fehlerwert" SG_ 2527679715 pVS_LadegrenzeAnfr_Zaehler 15;
BA_ "GenSigSwitchedByIgnition" SG_ 2527679715 pVS_LadegrenzeAnfr_Zaehler 0;
BA_ "GenSigStartValue" SG_ 2527679715 pVS_LadegrenzeAnfr_Zaehler 14;
BA_ "GenSigSendType" SG_ 2527679715 pVS_LadegrenzeAnfr_Zaehler 0;
BA_ "Fehlerwert" SG_ 2527679715 pVS_LadegrenzeAnfr_Leistung 4095;
BA_ "GenSigSwitchedByIgnition" SG_ 2527679715 pVS_LadegrenzeAnfr_Leistung 0;
BA_ "GenSigStartValue" SG_ 2527679715 pVS_LadegrenzeAnfr_Leistung 4094;
BA_ "GenSigSendType" SG_ 2527679715 pVS_LadegrenzeAnfr_Leistung 0;
BA_ "GenSigSwitchedByIgnition" SG_ 1616 RA_Radio_on 0;
BA_ "GenSigSendType" SG_ 1616 RA_Radio_on 3;
BA_ "GenSigSwitchedByIgnition" SG_ 1616 RA_PowerAmpOn 0;
BA_ "GenSigSendType" SG_ 1616 RA_PowerAmpOn 3;
BA_ "GenSigSwitchedByIgnition" SG_ 1616 RA_Radio_mute 0;
BA_ "GenSigSendType" SG_ 1616 RA_Radio_mute 3;
BA_ "GenSigSwitchedByIgnition" SG_ 1616 RA_VNC_OFF 0;
BA_ "GenSigSendType" SG_ 1616 RA_VNC_OFF 3;
BA_ "GenSigSwitchedByIgnition" SG_ 1616 RA_Radio_Surround 0;
BA_ "GenSigSendType" SG_ 1616 RA_Radio_Surround 3;
BA_ "GenSigSwitchedByIgnition" SG_ 1616 RA_Radio_Error_Flag 0;
BA_ "GenSigSendType" SG_ 1616 RA_Radio_Error_Flag 3;
BA_ "GenSigSwitchedByIgnition" SG_ 1616 RA_Frequency 0;
BA_ "GenSigSendType" SG_ 1616 RA_Frequency 3;
BA_ "GenSigSwitchedByIgnition" SG_ 1616 RA_Frequency_unit 0;
BA_ "GenSigSendType" SG_ 1616 RA_Frequency_unit 3;
BA_ "GenSigSwitchedByIgnition" SG_ 1616 RA_AM_Tuning 0;
BA_ "GenSigSendType" SG_ 1616 RA_AM_Tuning 3;
BA_ "Fehlerwert" SG_ 1525 RW_Gesamt_Reichweite_Max_Anzeige 2047;
BA_ "GenSigSwitchedByIgnition" SG_ 1525 RW_Gesamt_Reichweite_Max_Anzeige 0;
BA_ "GenSigStartValue" SG_ 1525 RW_Gesamt_Reichweite_Max_Anzeige 2046;
BA_ "GenSigSendType" SG_ 1525 RW_Gesamt_Reichweite_Max_Anzeige 0;
BA_ "GenSigSwitchedByIgnition" SG_ 1525 RW_Reservewarnung_2_aktiv 0;
BA_ "GenSigSendType" SG_ 1525 RW_Reservewarnung_2_aktiv 0;
BA_ "Fehlerwert" SG_ 1525 RW_RWDS_Lastprofil 2047;
BA_ "GenSigSwitchedByIgnition" SG_ 1525 RW_RWDS_Lastprofil 0;
BA_ "GenSigStartValue" SG_ 1525 RW_RWDS_Lastprofil 2046;
BA_ "GenSigSendType" SG_ 1525 RW_RWDS_Lastprofil 0;
BA_ "Fehlerwert" SG_ 1525 RW_Gesamt_Reichweite 2047;
BA_ "GenSigSwitchedByIgnition" SG_ 1525 RW_Gesamt_Reichweite 0;
BA_ "GenSigSendType" SG_ 1525 RW_Gesamt_Reichweite 0;
BA_ "GenSigSwitchedByIgnition" SG_ 1525 RW_Prim_Reichweitenverbrauch 0;
BA_ "GenSigStartValue" SG_ 1525 RW_Prim_Reichweitenverbrauch 2047;
BA_ "GenSigSendType" SG_ 1525 RW_Prim_Reichweitenverbrauch 0;
BA_ "GenSigSwitchedByIgnition" SG_ 1525 RW_Prim_Reichweitenv_Einheit 0;
BA_ "GenSigStartValue" SG_ 1525 RW_Prim_Reichweitenv_Einheit 3;
BA_ "GenSigSendType" SG_ 1525 RW_Prim_Reichweitenv_Einheit 0;
BA_ "Fehlerwert" SG_ 1525 RW_Primaer_Reichweite 2047;
BA_ "GenSigSwitchedByIgnition" SG_ 1525 RW_Primaer_Reichweite 0;
BA_ "GenSigStartValue" SG_ 1525 RW_Primaer_Reichweite 2046;
BA_ "GenSigSendType" SG_ 1525 RW_Primaer_Reichweite 0;
BA_ "GenSigSwitchedByIgnition" SG_ 1527 RW_Tendenz 0;
BA_ "GenSigSendType" SG_ 1527 RW_Tendenz 0;
BA_ "GenSigSwitchedByIgnition" SG_ 1527 RW_Texte 0;
BA_ "GenSigSendType" SG_ 1527 RW_Texte 3;
BA_ "GenSigSwitchedByIgnition" SG_ 1527 RW_Reservewarnung_aktiv 0;
BA_ "GenSigSendType" SG_ 1527 RW_Reservewarnung_aktiv 0;
BA_ "GenSigSwitchedByIgnition" SG_ 1527 RW_Reichweite_Einheit_Anzeige 0;
BA_ "GenSigSendType" SG_ 1527 RW_Reichweite_Einheit_Anzeige 0;
BA_ "Fehlerwert" SG_ 1527 RW_Gesamt_Reichweite_Anzeige 2047;
BA_ "GenSigSwitchedByIgnition" SG_ 1527 RW_Gesamt_Reichweite_Anzeige 0;
BA_ "GenSigStartValue" SG_ 1527 RW_Gesamt_Reichweite_Anzeige 2046;
BA_ "GenSigSendType" SG_ 1527 RW_Gesamt_Reichweite_Anzeige 0;
BA_ "Fehlerwert" SG_ 1527 RW_Primaer_Reichweite_Anzeige 2047;
BA_ "GenSigSwitchedByIgnition" SG_ 1527 RW_Primaer_Reichweite_Anzeige 0;
BA_ "GenSigStartValue" SG_ 1527 RW_Primaer_Reichweite_Anzeige 2046;
BA_ "GenSigSendType" SG_ 1527 RW_Primaer_Reichweite_Anzeige 0;
BA_ "Fehlerwert" SG_ 1527 RW_Sekundaer_Reichweite_Anzeige 2047;
BA_ "GenSigSwitchedByIgnition" SG_ 1527 RW_Sekundaer_Reichweite_Anzeige 0;
BA_ "GenSigStartValue" SG_ 1527 RW_Sekundaer_Reichweite_Anzeige 2046;
BA_ "GenSigSendType" SG_ 1527 RW_Sekundaer_Reichweite_Anzeige 0;
BA_ "Fehlerwert" SG_ 1527 RW_Sekundaer_Reichweite 2047;
BA_ "GenSigSwitchedByIgnition" SG_ 1527 RW_Sekundaer_Reichweite 0;
BA_ "GenSigStartValue" SG_ 1527 RW_Sekundaer_Reichweite 2046;
BA_ "GenSigSendType" SG_ 1527 RW_Sekundaer_Reichweite 0;
BA_ "GenSigSwitchedByIgnition" SG_ 1527 RW_Sek_Reichweitenv_Einheit 0;
BA_ "GenSigStartValue" SG_ 1527 RW_Sek_Reichweitenv_Einheit 3;
BA_ "GenSigSendType" SG_ 1527 RW_Sek_Reichweitenv_Einheit 0;
BA_ "GenSigSwitchedByIgnition" SG_ 1527 RW_Sek_Reichweitenverbrauch 0;
BA_ "GenSigStartValue" SG_ 1527 RW_Sek_Reichweitenverbrauch 2047;
BA_ "GenSigSendType" SG_ 1527 RW_Sek_Reichweitenverbrauch 0;
BA_ "GenSigSwitchedByIgnition" SG_ 2463978658 Rezi_Status_Spgfreiheit 0;
BA_ "GenSigSendType" SG_ 2463978658 Rezi_Status_Spgfreiheit 3;
BA_ "GenSigSwitchedByIgnition" SG_ 2463978658 Rezi_Warnung_Uebertemperatur 0;
BA_ "GenSigSendType" SG_ 2463978658 Rezi_Warnung_Uebertemperatur 0;
BA_ "Fehlerwert" SG_ 2463978658 Rezi_IstSpannung 511;
BA_ "GenSigSwitchedByIgnition" SG_ 2463978658 Rezi_IstSpannung 0;
BA_ "GenSigSendType" SG_ 2463978658 Rezi_IstSpannung 0;
BA_ "Fehlerwert" SG_ 2463978658 Rezi_Fehler_Blockiert 1;
BA_ "GenSigSwitchedByIgnition" SG_ 2463978658 Rezi_Fehler_Blockiert 0;
BA_ "GenSigSendType" SG_ 2463978658 Rezi_Fehler_Blockiert 0;
BA_ "Fehlerwert" SG_ 2463978658 Rezi_Fehler_Bauteil_Defekt 1;
BA_ "GenSigSwitchedByIgnition" SG_ 2463978658 Rezi_Fehler_Bauteil_Defekt 0;
BA_ "GenSigSendType" SG_ 2463978658 Rezi_Fehler_Bauteil_Defekt 0;
BA_ "Fehlerwert" SG_ 2463978658 Rezi_Fehler_Ueberspannung_HV 1;
BA_ "GenSigSwitchedByIgnition" SG_ 2463978658 Rezi_Fehler_Ueberspannung_HV 0;
BA_ "GenSigSendType" SG_ 2463978658 Rezi_Fehler_Ueberspannung_HV 0;
BA_ "Fehlerwert" SG_ 2463978658 Rezi_Fehler_Ueberspannung_NV 1;
BA_ "GenSigSwitchedByIgnition" SG_ 2463978658 Rezi_Fehler_Ueberspannung_NV 0;
BA_ "GenSigSendType" SG_ 2463978658 Rezi_Fehler_Ueberspannung_NV 0;
BA_ "Fehlerwert" SG_ 2463978658 Rezi_Fehler_Uebertemperatur 1;
BA_ "GenSigSwitchedByIgnition" SG_ 2463978658 Rezi_Fehler_Uebertemperatur 0;
BA_ "GenSigSendType" SG_ 2463978658 Rezi_Fehler_Uebertemperatur 0;
BA_ "Fehlerwert" SG_ 2463978658 Rezi_Fehler_Unterspannung_HV 1;
BA_ "GenSigSwitchedByIgnition" SG_ 2463978658 Rezi_Fehler_Unterspannung_HV 0;
BA_ "GenSigSendType" SG_ 2463978658 Rezi_Fehler_Unterspannung_HV 0;
BA_ "Fehlerwert" SG_ 2463978658 Rezi_IstDrehzahl 16383;
BA_ "GenSigSwitchedByIgnition" SG_ 2463978658 Rezi_IstDrehzahl 0;
BA_ "GenSigSendType" SG_ 2463978658 Rezi_IstDrehzahl 0;
BA_ "GenSigSwitchedByIgnition" SG_ 2463978658 Rezi_Error_NW_Timeout 0;
BA_ "GenSigSendType" SG_ 2463978658 Rezi_Error_NW_Timeout 0;
BA_ "Fehlerwert" SG_ 2463978658 Rezi_IstStrom 255;
BA_ "GenSigSwitchedByIgnition" SG_ 2463978658 Rezi_IstStrom 0;
BA_ "GenSigSendType" SG_ 2463978658 Rezi_IstStrom 0;
BA_ "GenSigSwitchedByIgnition" SG_ 1126 RTM_Warnstatus 0;
BA_ "GenSigSendType" SG_ 1126 RTM_Warnstatus 3;
BA_ "GenSigSwitchedByIgnition" SG_ 2527679790 RTM_02_Dummy 0;
BA_ "GenSigSendType" SG_ 2527679790 RTM_02_Dummy 3;
BA_ "GenSigSwitchedByIgnition" SG_ 2527679791 RTM_03_Dummy 0;
BA_ "GenSigSendType" SG_ 2527679791 RTM_03_Dummy 0;
BA_ "GenSigSwitchedByIgnition" SG_ 2527679792 RTM_04_Dummy 0;
BA_ "GenSigSendType" SG_ 2527679792 RTM_04_Dummy 3;
BA_ "GenSigSwitchedByIgnition" SG_ 1313 STH_Funk_ein 0;
BA_ "GenSigSendType" SG_ 1313 STH_Funk_ein 0;
BA_ "GenSigSwitchedByIgnition" SG_ 1313 STH_Funk_aus 0;
BA_ "GenSigSendType" SG_ 1313 STH_Funk_aus 0;
BA_ "GenSigSwitchedByIgnition" SG_ 1313 STH_Zusatzheizung 0;
BA_ "GenSigSendType" SG_ 1313 STH_Zusatzheizung 0;
BA_ "GenSigSwitchedByIgnition" SG_ 1313 STH_LED 0;
BA_ "GenSigSendType" SG_ 1313 STH_LED 0;
BA_ "GenSigSwitchedByIgnition" SG_ 1313 STH_Pumpe_ein 0;
BA_ "GenSigSendType" SG_ 1313 STH_Pumpe_ein 0;
BA_ "GenSigSwitchedByIgnition" SG_ 1313 STH_Geblaese 0;
BA_ "GenSigSendType" SG_ 1313 STH_Geblaese 0;
BA_ "GenSigSwitchedByIgnition" SG_ 1313 STH_EKP_Anst 0;
BA_ "GenSigSendType" SG_ 1313 STH_EKP_Anst 0;
BA_ "GenSigSendType" SG_ 1313 STH_Start_folgt 0;
BA_ "GenSigSwitchedByIgnition" SG_ 1313 STH_Ventiloeffnungszeit 0;
BA_ "GenSigSendType" SG_ 1313 STH_Ventiloeffnungszeit 0;
BA_ "GenSigSwitchedByIgnition" SG_ 1313 STH_Ventil_Status 0;
BA_ "GenSigSendType" SG_ 1313 STH_Ventil_Status 0;
BA_ "Fehlerwert" SG_ 1313 STH_Fehler_ElWaPu 1;
BA_ "GenSigSwitchedByIgnition" SG_ 1313 STH_Fehler_ElWaPu 0;
BA_ "GenSigSendType" SG_ 1313 STH_Fehler_ElWaPu 0;
BA_ "GenSigSwitchedByIgnition" SG_ 1313 STH_Waermeeintrag 0;
BA_ "GenSigSendType" SG_ 1313 STH_Waermeeintrag 0;
BA_ "GenSigSendType" SG_ 1313 STH_Pumpen_Anf_extern 0;
BA_ "GenSigSendType" SG_ 1313 STH_KL_HUP 0;
BA_ "GenSigSwitchedByIgnition" SG_ 1313 STH_KVS 0;
BA_ "GenSigSendType" SG_ 1313 STH_KVS 0;
BA_ "GenSigSwitchedByIgnition" SG_ 1313 STH_Fehlerstatus 0;
BA_ "GenSigSendType" SG_ 1313 STH_Fehlerstatus 0;
BA_ "GenSigSwitchedByIgnition" SG_ 1313 STH_Heizleistung 0;
BA_ "GenSigSendType" SG_ 1313 STH_Heizleistung 0;
BA_ "Fehlerwert" SG_ 1313 STH_Wassertemp 255;
BA_ "GenSigSwitchedByIgnition" SG_ 1313 STH_Wassertemp 0;
BA_ "GenSigStartValue" SG_ 1313 STH_Wassertemp 254;
BA_ "GenSigSendType" SG_ 1313 STH_Wassertemp 0;
BA_ "GenSigSwitchedByIgnition" SG_ 1313 STH_Texte 0;
BA_ "GenSigSendType" SG_ 1313 STH_Texte 0;
BA_ "GenSigSwitchedByIgnition" SG_ 1313 STH_Motorvorwaermung 0;
BA_ "GenSigSendType" SG_ 1313 STH_Motorvorwaermung 0;
BA_ "GenSigSwitchedByIgnition" SG_ 1313 STH_Servicemode 0;
BA_ "GenSigSendType" SG_ 1313 STH_Servicemode 0;
BA_ "GenSigSwitchedByIgnition" SG_ 1313 STH_war_aktiv 0;
BA_ "GenSigSendType" SG_ 1313 STH_war_aktiv 0;
BA_ "GenSigSwitchedByIgnition" SG_ 1313 STH_KVS_Ueberlauf 0;
BA_ "GenSigSendType" SG_ 1313 STH_KVS_Ueberlauf 0;
BA_ "GenSigSendType" SG_ 1313 STH_SH_ZH 0;
BA_ "GenSigFuncType" SG_ 505 STP_03_CRC 2;
BA_ "GenSigSendType" SG_ 505 STP_03_CRC 0;
BA_ "GenSigFuncType" SG_ 505 STP_03_BZ 1;
BA_ "GenSigSendType" SG_ 505 STP_03_BZ 0;
BA_ "GenSigSendType" SG_ 505 STP_Slave_Status 0;
BA_ "GenSigStartValue" SG_ 505 FZE_STP_Abschaltbedingung 1;
BA_ "GenSigSendType" SG_ 505 FZE_STP_Abschaltbedingung 0;
BA_ "GenSigSendType" SG_ 505 ACA_HF_Grund_AV_AB 0;
BA_ "GenSigSendType" SG_ 505 FZE_STP_Status 0;
BA_ "GenSigSendType" SG_ 505 STP_Notlaufaktivierung 0;
BA_ "GenSigSendType" SG_ 505 STP_Funktion_freigegeben 0;
BA_ "GenSigSendType" SG_ 505 ACA_QF_Status_Anzeige 0;
BA_ "GenSigSwitchedByIgnition" SG_ 505 ACF_SwuFahrerUnaufmerksam 0;
BA_ "GenSigSendType" SG_ 505 ACF_SwuFahrerUnaufmerksam 0;
BA_ "GenSigSendType" SG_ 505 ACA_QF_Fahreruebernahme 0;
BA_ "GenSigStartValue" SG_ 505 ACA_HF_Status 1;
BA_ "GenSigSendType" SG_ 505 ACA_HF_Status 0;
BA_ "GenSigSendType" SG_ 505 FZE_Spurwechsel_erkannt_li 0;
BA_ "GenSigSendType" SG_ 505 FZE_Spurwechsel_erkannt_re 0;
BA_ "GenSigSendType" SG_ 505 ACF_Spurwechsel_moeglich 0;
BA_ "GenSigSendType" SG_ 505 ACF_Spurwechsel_wahrscheinlich 0;
BA_ "GenSigSwitchedByIgnition" SG_ 505 FZE_STP_Aktivierverhinderung 0;
BA_ "GenSigSendType" SG_ 505 FZE_STP_Aktivierverhinderung 0;
BA_ "Fehlerwert" SG_ 1001 Thermo_Pred_T_dyn_Innen 255;
BA_ "GenSigSwitchedByIgnition" SG_ 1001 Thermo_Pred_T_dyn_Innen 0;
BA_ "GenSigStartValue" SG_ 1001 Thermo_Pred_T_dyn_Innen 254;
BA_ "GenSigSendType" SG_ 1001 Thermo_Pred_T_dyn_Innen 0;
BA_ "GenSigSwitchedByIgnition" SG_ 1001 Thermo_Pred_Innen_Kunde_Anf 0;
BA_ "GenSigSendType" SG_ 1001 Thermo_Pred_Innen_Kunde_Anf 0;
BA_ "Fehlerwert" SG_ 1001 Thermo_Pred_P_dyn_Innen 2047;
BA_ "GenSigSwitchedByIgnition" SG_ 1001 Thermo_Pred_P_dyn_Innen 0;
BA_ "GenSigStartValue" SG_ 1001 Thermo_Pred_P_dyn_Innen 2046;
BA_ "GenSigSendType" SG_ 1001 Thermo_Pred_P_dyn_Innen 0;
BA_ "Fehlerwert" SG_ 1001 Thermo_Pred_P_stat_Innen 2047;
BA_ "GenSigSwitchedByIgnition" SG_ 1001 Thermo_Pred_P_stat_Innen 0;
BA_ "GenSigStartValue" SG_ 1001 Thermo_Pred_P_stat_Innen 2046;
BA_ "GenSigSendType" SG_ 1001 Thermo_Pred_P_stat_Innen 0;
BA_ "GenSigSwitchedByIgnition" SG_ 1001 Thermo_Verbrauch_BTL 0;
BA_ "GenSigSendType" SG_ 1001 Thermo_Verbrauch_BTL 0;
BA_ "GenSigSwitchedByIgnition" SG_ 1001 Thermo_Verbrauch_BTL_Ueberlauf 0;
BA_ "GenSigSendType" SG_ 1001 Thermo_Verbrauch_BTL_Ueberlauf 0;
BA_ "GenSigSwitchedByIgnition" SG_ 1001 Thermo_Pred_Innen_System_Anf 0;
BA_ "GenSigSendType" SG_ 1001 Thermo_Pred_Innen_System_Anf 0;
BA_ "GenSigSwitchedByIgnition" SG_ 1001 Thermo_Verbrauch_Innen 0;
BA_ "GenSigSendType" SG_ 1001 Thermo_Verbrauch_Innen 0;
BA_ "GenSigSwitchedByIgnition" SG_ 1001 Thermo_Verbrauch_Innen_Ueberlauf 0;
BA_ "GenSigSendType" SG_ 1001 Thermo_Verbrauch_Innen_Ueberlauf 0;
BA_ "Fehlerwert" SG_ 1015 KL_HV_Energie_Anf 255;
BA_ "GenSigSwitchedByIgnition" SG_ 1015 KL_HV_Energie_Anf 0;
BA_ "GenSigStartValue" SG_ 1015 KL_HV_Energie_Anf 254;
BA_ "GenSigSendType" SG_ 1015 KL_HV_Energie_Anf 0;
BA_ "Fehlerwert" SG_ 1015 TME_Kuehlerluefer_3 127;
BA_ "GenSigSwitchedByIgnition" SG_ 1015 TME_Kuehlerluefer_3 0;
BA_ "GenSigStartValue" SG_ 1015 TME_Kuehlerluefer_3 126;
BA_ "GenSigSendType" SG_ 1015 TME_Kuehlerluefer_3 0;
BA_ "GenSigSwitchedByIgnition" SG_ 1015 TME_StartStopp_Info_Prio 0;
BA_ "GenSigSendType" SG_ 1015 TME_StartStopp_Info_Prio 0;
BA_ "Fehlerwert" SG_ 1015 TME_HVEM_HV_Anf 3;
BA_ "GenSigSwitchedByIgnition" SG_ 1015 TME_HVEM_HV_Anf 0;
BA_ "GenSigSendType" SG_ 1015 TME_HVEM_HV_Anf 0;
BA_ "Fehlerwert" SG_ 1015 TME_StartStopp_Info 3;
BA_ "GenSigSendType" SG_ 1015 TME_StartStopp_Info 0;
BA_ "GenSigSwitchedByIgnition" SG_ 1015 TME_OBD_Lampe_Anf 0;
BA_ "GenSigSendType" SG_ 1015 TME_OBD_Lampe_Anf 0;
BA_ "Fehlerwert" SG_ 1015 TME_HVPTC_Istmodus 5;
BA_ "GenSigSwitchedByIgnition" SG_ 1015 TME_HVPTC_Istmodus 0;
BA_ "GenSigStartValue" SG_ 1015 TME_HVPTC_Istmodus 7;
BA_ "GenSigSendType" SG_ 1015 TME_HVPTC_Istmodus 0;
BA_ "GenSigSwitchedByIgnition" SG_ 1015 TME_HVPTC_Fehlerstatus 0;
BA_ "GenSigStartValue" SG_ 1015 TME_HVPTC_Fehlerstatus 7;
BA_ "GenSigSendType" SG_ 1015 TME_HVPTC_Fehlerstatus 0;
BA_ "Fehlerwert" SG_ 1015 TME_EKK_Istmodus 5;
BA_ "GenSigSwitchedByIgnition" SG_ 1015 TME_EKK_Istmodus 0;
BA_ "GenSigStartValue" SG_ 1015 TME_EKK_Istmodus 7;
BA_ "GenSigSendType" SG_ 1015 TME_EKK_Istmodus 0;
BA_ "GenSigSwitchedByIgnition" SG_ 1015 TME_EKK_Fehlerstatus 0;
BA_ "GenSigStartValue" SG_ 1015 TME_EKK_Fehlerstatus 7;
BA_ "GenSigSendType" SG_ 1015 TME_EKK_Fehlerstatus 0;
BA_ "Fehlerwert" SG_ 1015 TME_HVK_EKK_SOLL 3;
BA_ "GenSigSwitchedByIgnition" SG_ 1015 TME_HVK_EKK_SOLL 0;
BA_ "GenSigSendType" SG_ 1015 TME_HVK_EKK_SOLL 0;
BA_ "Fehlerwert" SG_ 1015 TME_Strom_Kuehlerluefter 31;
BA_ "GenSigSwitchedByIgnition" SG_ 1015 TME_Strom_Kuehlerluefter 0;
BA_ "GenSigStartValue" SG_ 1015 TME_Strom_Kuehlerluefter 30;
BA_ "GenSigSendType" SG_ 1015 TME_Strom_Kuehlerluefter 0;
BA_ "Fehlerwert" SG_ 1015 TME_PWM_Pumpe1_tNT_Soll 127;
BA_ "GenSigSwitchedByIgnition" SG_ 1015 TME_PWM_Pumpe1_tNT_Soll 0;
BA_ "GenSigStartValue" SG_ 1015 TME_PWM_Pumpe1_tNT_Soll 126;
BA_ "GenSigSendType" SG_ 1015 TME_PWM_Pumpe1_tNT_Soll 0;
BA_ "Fehlerwert" SG_ 1017 TME_NT_Kreis_Status 1;
BA_ "GenSigSwitchedByIgnition" SG_ 1017 TME_NT_Kreis_Status 0;
BA_ "GenSigSendType" SG_ 1017 TME_NT_Kreis_Status 0;
BA_ "GenSigSwitchedByIgnition" SG_ 1017 TME_Ventil1_Status 0;
BA_ "GenSigSendType" SG_ 1017 TME_Ventil1_Status 0;
BA_ "Fehlerwert" SG_ 1017 TME_Fehler_ElWaPu1 1;
BA_ "GenSigSwitchedByIgnition" SG_ 1017 TME_Fehler_ElWaPu1 0;
BA_ "GenSigSendType" SG_ 1017 TME_Fehler_ElWaPu1 0;
BA_ "GenSigSwitchedByIgnition" SG_ 1017 TME_Pumpe1_Status 0;
BA_ "GenSigSendType" SG_ 1017 TME_Pumpe1_Status 0;
BA_ "GenSigSwitchedByIgnition" SG_ 1017 TME_Nachlaufzeit 0;
BA_ "GenSigSendType" SG_ 1017 TME_Nachlaufzeit 0;
BA_ "Fehlerwert" SG_ 1017 TME_Anf_KL 127;
BA_ "GenSigSwitchedByIgnition" SG_ 1017 TME_Anf_KL 0;
BA_ "GenSigStartValue" SG_ 1017 TME_Anf_KL 126;
BA_ "GenSigSendType" SG_ 1017 TME_Anf_KL 0;
BA_ "GenSigSwitchedByIgnition" SG_ 1017 TME_Status_KL 0;
BA_ "GenSigSendType" SG_ 1017 TME_Status_KL 0;
BA_ "Fehlerwert" SG_ 1017 TME_EM1_IstVolumenstrom 31;
BA_ "GenSigSwitchedByIgnition" SG_ 1017 TME_EM1_IstVolumenstrom 0;
BA_ "GenSigStartValue" SG_ 1017 TME_EM1_IstVolumenstrom 30;
BA_ "GenSigSendType" SG_ 1017 TME_EM1_IstVolumenstrom 0;
BA_ "Fehlerwert" SG_ 1017 TME_EM2_IstVolumenstrom 31;
BA_ "GenSigSwitchedByIgnition" SG_ 1017 TME_EM2_IstVolumenstrom 0;
BA_ "GenSigStartValue" SG_ 1017 TME_EM2_IstVolumenstrom 30;
BA_ "GenSigSendType" SG_ 1017 TME_EM2_IstVolumenstrom 0;
BA_ "Fehlerwert" SG_ 1017 TME_EM3_IstVolumenstrom 31;
BA_ "GenSigSwitchedByIgnition" SG_ 1017 TME_EM3_IstVolumenstrom 0;
BA_ "GenSigStartValue" SG_ 1017 TME_EM3_IstVolumenstrom 30;
BA_ "GenSigSendType" SG_ 1017 TME_EM3_IstVolumenstrom 0;
BA_ "Fehlerwert" SG_ 1017 TME_PWM_Pumpe2_HK_Soll 127;
BA_ "GenSigSwitchedByIgnition" SG_ 1017 TME_PWM_Pumpe2_HK_Soll 0;
BA_ "GenSigStartValue" SG_ 1017 TME_PWM_Pumpe2_HK_Soll 126;
BA_ "GenSigSendType" SG_ 1017 TME_PWM_Pumpe2_HK_Soll 0;
BA_REL_ "GenSigTimeoutTime" BU_SG_REL_ AWC SG_ 2600468546 NM_TME_SNI 2000;
BA_REL_ "GenSigTimeoutTime" BU_SG_REL_ BMC_MLBevo SG_ 2600468546 NM_TME_SNI 2000;
BA_REL_ "GenSigTimeoutTime" BU_SG_REL_ BMS_MV SG_ 2600468546 NM_TME_SNI 2000;
BA_REL_ "GenSigTimeoutTime" BU_SG_REL_ BMS_NV SG_ 2600468546 NM_TME_SNI 2000;
BA_REL_ "GenSigTimeoutTime" BU_SG_REL_ DCDC_800V_PAG SG_ 2600468546 NM_TME_SNI 2000;
BA_REL_ "GenSigTimeoutTime" BU_SG_REL_ DCDC_HV SG_ 2600468546 NM_TME_SNI 2000;
BA_REL_ "GenSigTimeoutTime" BU_SG_REL_ DCDC_HV_02 SG_ 2600468546 NM_TME_SNI 2000;
BA_REL_ "GenSigTimeoutTime" BU_SG_REL_ DCDC_IHEV SG_ 2600468546 NM_TME_SNI 2000;
BA_REL_ "GenSigTimeoutTime" BU_SG_REL_ FCU_MLBevo_FCEV SG_ 2600468546 NM_TME_SNI 2000;
BA_REL_ "GenSigTimeoutTime" BU_SG_REL_ Gateway SG_ 2600468546 NM_TME_SNI 2000;
BA_REL_ "GenSigTimeoutTime" BU_SG_REL_ Gateway_PAG SG_ 2600468546 NM_TME_SNI 2000;
BA_REL_ "GenSigTimeoutTime" BU_SG_REL_ Ladegeraet_2 SG_ 2600468546 NM_TME_SNI 2000;
BA_REL_ "GenSigTimeoutTime" BU_SG_REL_ Ladegeraet_Konzern SG_ 2600468546 NM_TME_SNI 2000;
BA_REL_ "GenSigTimeoutTime" BU_SG_REL_ LE1 SG_ 2600468546 NM_TME_SNI 2000;
BA_REL_ "GenSigTimeoutTime" BU_SG_REL_ LE2 SG_ 2600468546 NM_TME_SNI 2000;
BA_REL_ "GenSigTimeoutTime" BU_SG_REL_ LE2_3_MLBevo_LB SG_ 2600468546 NM_TME_SNI 2000;
BA_REL_ "GenSigTimeoutTime" BU_SG_REL_ LE_MLBevo SG_ 2600468546 NM_TME_SNI 2000;
BA_REL_ "GenSigTimeoutTime" BU_SG_REL_ Sub_Gateway SG_ 2600468546 NM_TME_SNI 2000;
BA_REL_ "GenSigTimeoutTime" BU_SG_REL_ Gateway SG_ 2600468546 NM_TME_CBV_AWB 2000;
BA_REL_ "GenSigTimeoutTime" BU_SG_REL_ Gateway_PAG SG_ 2600468546 NM_TME_CBV_AWB 2000;
BA_REL_ "GenSigTimeoutTime" BU_SG_REL_ AWC SG_ 2600468546 NM_TME_CBV_CRI 2000;
BA_REL_ "GenSigTimeoutTime" BU_SG_REL_ BMC_MLBevo SG_ 2600468546 NM_TME_CBV_CRI 2000;
BA_REL_ "GenSigTimeoutTime" BU_SG_REL_ BMS_MV SG_ 2600468546 NM_TME_CBV_CRI 2000;
BA_REL_ "GenSigTimeoutTime" BU_SG_REL_ BMS_NV SG_ 2600468546 NM_TME_CBV_CRI 2000;
BA_REL_ "GenSigTimeoutTime" BU_SG_REL_ DCDC_800V_PAG SG_ 2600468546 NM_TME_CBV_CRI 2000;
BA_REL_ "GenSigTimeoutTime" BU_SG_REL_ DCDC_HV SG_ 2600468546 NM_TME_CBV_CRI 2000;
BA_REL_ "GenSigTimeoutTime" BU_SG_REL_ DCDC_HV_02 SG_ 2600468546 NM_TME_CBV_CRI 2000;
BA_REL_ "GenSigTimeoutTime" BU_SG_REL_ DCDC_IHEV SG_ 2600468546 NM_TME_CBV_CRI 2000;
BA_REL_ "GenSigTimeoutTime" BU_SG_REL_ FCU_MLBevo_FCEV SG_ 2600468546 NM_TME_CBV_CRI 2000;
BA_REL_ "GenSigTimeoutTime" BU_SG_REL_ Gateway SG_ 2600468546 NM_TME_CBV_CRI 2000;
BA_REL_ "GenSigTimeoutTime" BU_SG_REL_ Gateway_PAG SG_ 2600468546 NM_TME_CBV_CRI 2000;
BA_REL_ "GenSigTimeoutTime" BU_SG_REL_ Ladegeraet_2 SG_ 2600468546 NM_TME_CBV_CRI 2000;
BA_REL_ "GenSigTimeoutTime" BU_SG_REL_ Ladegeraet_Konzern SG_ 2600468546 NM_TME_CBV_CRI 2000;
BA_REL_ "GenSigTimeoutTime" BU_SG_REL_ LE1 SG_ 2600468546 NM_TME_CBV_CRI 2000;
BA_REL_ "GenSigTimeoutTime" BU_SG_REL_ LE2 SG_ 2600468546 NM_TME_CBV_CRI 2000;
BA_REL_ "GenSigTimeoutTime" BU_SG_REL_ LE2_3_MLBevo_LB SG_ 2600468546 NM_TME_CBV_CRI 2000;
BA_REL_ "GenSigTimeoutTime" BU_SG_REL_ LE_MLBevo SG_ 2600468546 NM_TME_CBV_CRI 2000;
BA_REL_ "GenSigTimeoutTime" BU_SG_REL_ Sub_Gateway SG_ 2600468546 NM_TME_CBV_CRI 2000;
BA_REL_ "GenSigTimeoutTime" BU_SG_REL_ Gateway SG_ 2600468546 NM_TME_Car_Wakeup 2000;
BA_REL_ "GenSigTimeoutTime" BU_SG_REL_ Gateway_PAG SG_ 2600468546 NM_TME_Car_Wakeup 2000;
BA_REL_ "GenSigTimeoutTime" BU_SG_REL_ AWC SG_ 2600468546 NM_TME_CAB 2000;
BA_REL_ "GenSigTimeoutTime" BU_SG_REL_ BMC_MLBevo SG_ 2600468546 NM_TME_CAB 2000;
BA_REL_ "GenSigTimeoutTime" BU_SG_REL_ BMS_MV SG_ 2600468546 NM_TME_CAB 2000;
BA_REL_ "GenSigTimeoutTime" BU_SG_REL_ BMS_NV SG_ 2600468546 NM_TME_CAB 2000;
BA_REL_ "GenSigTimeoutTime" BU_SG_REL_ DCDC_800V_PAG SG_ 2600468546 NM_TME_CAB 2000;
BA_REL_ "GenSigTimeoutTime" BU_SG_REL_ DCDC_HV SG_ 2600468546 NM_TME_CAB 2000;
BA_REL_ "GenSigTimeoutTime" BU_SG_REL_ DCDC_HV_02 SG_ 2600468546 NM_TME_CAB 2000;
BA_REL_ "GenSigTimeoutTime" BU_SG_REL_ DCDC_IHEV SG_ 2600468546 NM_TME_CAB 2000;
BA_REL_ "GenSigTimeoutTime" BU_SG_REL_ FCU_MLBevo_FCEV SG_ 2600468546 NM_TME_CAB 2000;
BA_REL_ "GenSigTimeoutTime" BU_SG_REL_ Gateway SG_ 2600468546 NM_TME_CAB 2000;
BA_REL_ "GenSigTimeoutTime" BU_SG_REL_ Gateway_PAG SG_ 2600468546 NM_TME_CAB 2000;
BA_REL_ "GenSigTimeoutTime" BU_SG_REL_ Ladegeraet_2 SG_ 2600468546 NM_TME_CAB 2000;
BA_REL_ "GenSigTimeoutTime" BU_SG_REL_ Ladegeraet_Konzern SG_ 2600468546 NM_TME_CAB 2000;
BA_REL_ "GenSigTimeoutTime" BU_SG_REL_ LE1 SG_ 2600468546 NM_TME_CAB 2000;
BA_REL_ "GenSigTimeoutTime" BU_SG_REL_ LE2 SG_ 2600468546 NM_TME_CAB 2000;
BA_REL_ "GenSigTimeoutTime" BU_SG_REL_ LE2_3_MLBevo_LB SG_ 2600468546 NM_TME_CAB 2000;
BA_REL_ "GenSigTimeoutTime" BU_SG_REL_ LE_MLBevo SG_ 2600468546 NM_TME_CAB 2000;
BA_REL_ "GenSigTimeoutTime" BU_SG_REL_ Sub_Gateway SG_ 2600468546 NM_TME_CAB 2000;
BA_REL_ "GenSigTimeoutTime" BU_SG_REL_ AWC SG_ 1635 BEM_02_Abschaltstufen 1000;
BA_REL_ "GenSigTimeoutTime" BU_SG_REL_ BMC_MLBevo SG_ 1635 BEM_02_Abschaltstufen 1000;
BA_REL_ "GenSigTimeoutTime" BU_SG_REL_ DCDC_800V_PAG SG_ 1635 BEM_02_Abschaltstufen 1000;
BA_REL_ "GenSigTimeoutTime" BU_SG_REL_ DCDC_HV SG_ 1635 BEM_02_Abschaltstufen 1000;
BA_REL_ "GenSigTimeoutTime" BU_SG_REL_ DCDC_HV_02 SG_ 1635 BEM_02_Abschaltstufen 1000;
BA_REL_ "GenSigTimeoutTime" BU_SG_REL_ Ladegeraet_2 SG_ 1635 BEM_02_Abschaltstufen 1000;
BA_REL_ "GenSigTimeoutTime" BU_SG_REL_ Ladegeraet_Konzern SG_ 1635 BEM_02_Abschaltstufen 1000;
BA_REL_ "GenSigTimeoutTime" BU_SG_REL_ TME SG_ 1635 BEM_02_Abschaltstufen 1000;
BA_REL_ "GenSigTimeoutTime" BU_SG_REL_ TME SG_ 1635 BEM_STH_Zielzeit 1000;
BA_REL_ "GenSigTimeoutTime" BU_SG_REL_ TME SG_ 1635 BEM_Red_Innengeblaese 1000;
BA_REL_ "GenSigTimeoutTime" BU_SG_REL_ TME SG_ 1635 BEM_STH_Einschaltverbot 1000;
BA_REL_ "GenSigTimeoutTime" BU_SG_REL_ AWC SG_ 1635 BEM_UBDM 1000;
BA_REL_ "GenSigTimeoutTime" BU_SG_REL_ Ladegeraet_2 SG_ 1635 BEM_UBDM 1000;
BA_REL_ "GenSigTimeoutTime" BU_SG_REL_ Ladegeraet_Konzern SG_ 1635 BEM_UBDM 1000;
BA_REL_ "GenSigTimeoutTime" BU_SG_REL_ AWC SG_ 1635 NVEM_Freigabe_OnlineUpdate 1000;
BA_REL_ "GenSigTimeoutTime" BU_SG_REL_ DCDC_800V_PAG SG_ 869 BEM_Batt_Ab 500;
BA_REL_ "GenSigTimeoutTime" BU_SG_REL_ DCDC_IHEV SG_ 869 BEM_Batt_Ab 500;
BA_REL_ "GenSigTimeoutTime" BU_SG_REL_ TME SG_ 869 NVEM_Red_KL 500;
BA_REL_ "GenSigTimeoutTime" BU_SG_REL_ DCDC_800V_PAG SG_ 869 BEM_HYB_DC_uSollLV 500;
BA_REL_ "GenSigTimeoutTime" BU_SG_REL_ DCDC_HV SG_ 869 BEM_HYB_DC_uSollLV 500;
BA_REL_ "GenSigTimeoutTime" BU_SG_REL_ LE_MLBevo SG_ 869 BEM_HYB_DC_uSollLV 500;
BA_REL_ "GenSigTimeoutTime" BU_SG_REL_ BMS_NV SG_ 2527679508 NVEM_Min_Spannung_Start 1000;
BA_REL_ "GenSigTimeoutTime" BU_SG_REL_ DCDC_IHEV SG_ 2527679508 NVEM_MV_DC_uMinLV 1000;
BA_REL_ "GenSigTimeoutTime" BU_SG_REL_ DCDC_IHEV SG_ 2527679508 NVEM_MV_DC_uSollLV 1000;
BA_REL_ "GenSigTimeoutTime" BU_SG_REL_ BMS_NV SG_ 2527679509 NVEM_07_CRC 5000;
BA_REL_ "GenSigTimeoutTime" BU_SG_REL_ BMS_NV SG_ 2527679509 NVEM_07_BZ 5000;
BA_REL_ "GenSigTimeoutTime" BU_SG_REL_ BMS_NV SG_ 2527679509 NVEM_BMS_NV_Imax_RSG_Anf 5000;
BA_REL_ "GenSigTimeoutTime" BU_SG_REL_ BMS_NV SG_ 2527679509 NVEM_BMS_NV_Umin_RSG_Anf 5000;
BA_REL_ "GenSigTimeoutTime" BU_SG_REL_ BMS_NV SG_ 2527679509 NVEM_BMS_NV_Nachlaufzeit_Vorgabe 5000;
BA_REL_ "GenSigTimeoutTime" BU_SG_REL_ BMS_NV SG_ 2527679509 NVEM_BMS_NV_Umin_Anf 5000;
BA_REL_ "GenSigTimeoutTime" BU_SG_REL_ BMS_NV SG_ 2527679509 NVEM_FMAus_I_Verbrauch 5000;
BA_REL_ "GenSigTimeoutTime" BU_SG_REL_ BMS_NV SG_ 2527679509 NVEM_BMS_NV_Impuls_Abfrage 5000;
BA_REL_ "GenSigTimeoutTime" BU_SG_REL_ BMS_NV SG_ 2527679509 NVEM_BMS_NV_Sollmodus 5000;
BA_REL_ "GenSigTimeoutTime" BU_SG_REL_ DCDC_HV SG_ 527 NVEM_DC_uSoll_NV 500;
BA_REL_ "GenSigTimeoutTime" BU_SG_REL_ BMC_MLBevo SG_ 913 OBD_Calc_Load_Val 800;
BA_REL_ "GenSigTimeoutTime" BU_SG_REL_ BMS_MV SG_ 913 OBD_Calc_Load_Val 800;
BA_REL_ "GenSigTimeoutTime" BU_SG_REL_ FCU_MLBevo_FCEV SG_ 913 OBD_Calc_Load_Val 800;
BA_REL_ "GenSigTimeoutTime" BU_SG_REL_ TME SG_ 913 OBD_Calc_Load_Val 800;
BA_REL_ "GenSigTimeoutTime" BU_SG_REL_ BMC_MLBevo SG_ 913 OBD_Eng_Cool_Temp 800;
BA_REL_ "GenSigTimeoutTime" BU_SG_REL_ BMS_MV SG_ 913 OBD_Eng_Cool_Temp 800;
BA_REL_ "GenSigTimeoutTime" BU_SG_REL_ FCU_MLBevo_FCEV SG_ 913 OBD_Eng_Cool_Temp 800;
BA_REL_ "GenSigTimeoutTime" BU_SG_REL_ TME SG_ 913 OBD_Eng_Cool_Temp 800;
BA_REL_ "GenSigTimeoutTime" BU_SG_REL_ BMC_MLBevo SG_ 913 OBD_Abs_Throttle_Pos 800;
BA_REL_ "GenSigTimeoutTime" BU_SG_REL_ BMS_MV SG_ 913 OBD_Abs_Throttle_Pos 800;
BA_REL_ "GenSigTimeoutTime" BU_SG_REL_ TME SG_ 913 OBD_Abs_Throttle_Pos 800;
BA_REL_ "GenSigTimeoutTime" BU_SG_REL_ BMC_MLBevo SG_ 913 OBD_Abs_Load_Val 800;
BA_REL_ "GenSigTimeoutTime" BU_SG_REL_ BMS_MV SG_ 913 OBD_Abs_Load_Val 800;
BA_REL_ "GenSigTimeoutTime" BU_SG_REL_ TME SG_ 913 OBD_Abs_Load_Val 800;
BA_REL_ "GenSigTimeoutTime" BU_SG_REL_ BMC_MLBevo SG_ 913 OBD_Abs_Pedal_Pos 800;
BA_REL_ "GenSigTimeoutTime" BU_SG_REL_ BMS_MV SG_ 913 OBD_Abs_Pedal_Pos 800;
BA_REL_ "GenSigTimeoutTime" BU_SG_REL_ FCU_MLBevo_FCEV SG_ 913 OBD_Abs_Pedal_Pos 800;
BA_REL_ "GenSigTimeoutTime" BU_SG_REL_ TME SG_ 913 OBD_Abs_Pedal_Pos 800;
BA_REL_ "GenSigTimeoutTime" BU_SG_REL_ BMC_MLBevo SG_ 913 OBD_ClearMem_Inhibit 800;
BA_REL_ "GenSigTimeoutTime" BU_SG_REL_ FCU_MLBevo_FCEV SG_ 913 OBD_ClearMem_Inhibit 800;
BA_REL_ "GenSigTimeoutTime" BU_SG_REL_ TME SG_ 913 OBD_ClearMem_Inhibit 800;
BA_REL_ "GenSigTimeoutTime" BU_SG_REL_ FCU_MLBevo_FCEV SG_ 913 OBD_Sperrung_Kaltstart_Denom 800;
BA_REL_ "GenSigTimeoutTime" BU_SG_REL_ TME SG_ 913 OBD_Sperrung_Kaltstart_Denom 800;
BA_REL_ "GenSigTimeoutTime" BU_SG_REL_ BMC_MLBevo SG_ 913 MO_QBit_Aussen_Temp 800;
BA_REL_ "GenSigTimeoutTime" BU_SG_REL_ Ladegeraet_Konzern SG_ 913 MO_QBit_Aussen_Temp 800;
BA_REL_ "GenSigTimeoutTime" BU_SG_REL_ TME SG_ 913 MO_QBit_Aussen_Temp 800;
BA_REL_ "GenSigTimeoutTime" BU_SG_REL_ AWC SG_ 913 OBD_Sperrung_IUMPR 800;
BA_REL_ "GenSigTimeoutTime" BU_SG_REL_ BMC_MLBevo SG_ 913 OBD_Sperrung_IUMPR 800;
BA_REL_ "GenSigTimeoutTime" BU_SG_REL_ BMS_MV SG_ 913 OBD_Sperrung_IUMPR 800;
BA_REL_ "GenSigTimeoutTime" BU_SG_REL_ FCU_MLBevo_FCEV SG_ 913 OBD_Sperrung_IUMPR 800;
BA_REL_ "GenSigTimeoutTime" BU_SG_REL_ Ladegeraet_2 SG_ 913 OBD_Sperrung_IUMPR 800;
BA_REL_ "GenSigTimeoutTime" BU_SG_REL_ Ladegeraet_Konzern SG_ 913 OBD_Sperrung_IUMPR 800;
BA_REL_ "GenSigTimeoutTime" BU_SG_REL_ TME SG_ 913 OBD_Sperrung_IUMPR 800;
BA_REL_ "GenSigTimeoutTime" BU_SG_REL_ BMC_MLBevo SG_ 913 OBD_Kaltstart_Denominator 800;
BA_REL_ "GenSigTimeoutTime" BU_SG_REL_ BMS_MV SG_ 913 OBD_Kaltstart_Denominator 800;
BA_REL_ "GenSigTimeoutTime" BU_SG_REL_ FCU_MLBevo_FCEV SG_ 913 OBD_Kaltstart_Denominator 800;
BA_REL_ "GenSigTimeoutTime" BU_SG_REL_ TME SG_ 913 OBD_Kaltstart_Denominator 800;
BA_REL_ "GenSigTimeoutTime" BU_SG_REL_ AWC SG_ 913 OBD_Minimum_Trip 800;
BA_REL_ "GenSigTimeoutTime" BU_SG_REL_ BMC_MLBevo SG_ 913 OBD_Minimum_Trip 800;
BA_REL_ "GenSigTimeoutTime" BU_SG_REL_ BMS_MV SG_ 913 OBD_Minimum_Trip 800;
BA_REL_ "GenSigTimeoutTime" BU_SG_REL_ FCU_MLBevo_FCEV SG_ 913 OBD_Minimum_Trip 800;
BA_REL_ "GenSigTimeoutTime" BU_SG_REL_ Ladegeraet_2 SG_ 913 OBD_Minimum_Trip 800;
BA_REL_ "GenSigTimeoutTime" BU_SG_REL_ Ladegeraet_Konzern SG_ 913 OBD_Minimum_Trip 800;
BA_REL_ "GenSigTimeoutTime" BU_SG_REL_ TME SG_ 913 OBD_Minimum_Trip 800;
BA_REL_ "GenSigTimeoutTime" BU_SG_REL_ AWC SG_ 913 OBD_Driving_Cycle 800;
BA_REL_ "GenSigTimeoutTime" BU_SG_REL_ BMC_MLBevo SG_ 913 OBD_Driving_Cycle 800;
BA_REL_ "GenSigTimeoutTime" BU_SG_REL_ BMS_MV SG_ 913 OBD_Driving_Cycle 800;
BA_REL_ "GenSigTimeoutTime" BU_SG_REL_ FCU_MLBevo_FCEV SG_ 913 OBD_Driving_Cycle 800;
BA_REL_ "GenSigTimeoutTime" BU_SG_REL_ Ladegeraet_2 SG_ 913 OBD_Driving_Cycle 800;
BA_REL_ "GenSigTimeoutTime" BU_SG_REL_ Ladegeraet_Konzern SG_ 913 OBD_Driving_Cycle 800;
BA_REL_ "GenSigTimeoutTime" BU_SG_REL_ TME SG_ 913 OBD_Driving_Cycle 800;
BA_REL_ "GenSigTimeoutTime" BU_SG_REL_ AWC SG_ 913 OBD_Warm_Up_Cycle 800;
BA_REL_ "GenSigTimeoutTime" BU_SG_REL_ BMC_MLBevo SG_ 913 OBD_Warm_Up_Cycle 800;
BA_REL_ "GenSigTimeoutTime" BU_SG_REL_ BMS_MV SG_ 913 OBD_Warm_Up_Cycle 800;
BA_REL_ "GenSigTimeoutTime" BU_SG_REL_ DCDC_HV_02 SG_ 913 OBD_Warm_Up_Cycle 800;
BA_REL_ "GenSigTimeoutTime" BU_SG_REL_ DCDC_IHEV SG_ 913 OBD_Warm_Up_Cycle 800;
BA_REL_ "GenSigTimeoutTime" BU_SG_REL_ FCU_MLBevo_FCEV SG_ 913 OBD_Warm_Up_Cycle 800;
BA_REL_ "GenSigTimeoutTime" BU_SG_REL_ Ladegeraet_2 SG_ 913 OBD_Warm_Up_Cycle 800;
BA_REL_ "GenSigTimeoutTime" BU_SG_REL_ Ladegeraet_Konzern SG_ 913 OBD_Warm_Up_Cycle 800;
BA_REL_ "GenSigTimeoutTime" BU_SG_REL_ TME SG_ 913 OBD_Warm_Up_Cycle 800;
BA_REL_ "GenSigTimeoutTime" BU_SG_REL_ AWC SG_ 913 OBD_Normed_Trip 800;
BA_REL_ "GenSigTimeoutTime" BU_SG_REL_ BMC_MLBevo SG_ 913 OBD_Normed_Trip 800;
BA_REL_ "GenSigTimeoutTime" BU_SG_REL_ BMS_MV SG_ 913 OBD_Normed_Trip 800;
BA_REL_ "GenSigTimeoutTime" BU_SG_REL_ FCU_MLBevo_FCEV SG_ 913 OBD_Normed_Trip 800;
BA_REL_ "GenSigTimeoutTime" BU_SG_REL_ Ladegeraet_2 SG_ 913 OBD_Normed_Trip 800;
BA_REL_ "GenSigTimeoutTime" BU_SG_REL_ Ladegeraet_Konzern SG_ 913 OBD_Normed_Trip 800;
BA_REL_ "GenSigTimeoutTime" BU_SG_REL_ TME SG_ 913 OBD_Normed_Trip 800;
BA_REL_ "GenSigTimeoutTime" BU_SG_REL_ AWC SG_ 2589283656 ORU_Status 5000;
BA_REL_ "GenSigTimeoutTime" BU_SG_REL_ BMC_MLBevo SG_ 2589283656 ORU_Status 5000;
BA_REL_ "GenSigTimeoutTime" BU_SG_REL_ DCDC_800V_PAG SG_ 2589283656 ORU_Status 5000;
BA_REL_ "GenSigTimeoutTime" BU_SG_REL_ DCDC_HV SG_ 2589283656 ORU_Status 5000;
BA_REL_ "GenSigTimeoutTime" BU_SG_REL_ DCDC_HV_02 SG_ 2589283656 ORU_Status 5000;
BA_REL_ "GenSigTimeoutTime" BU_SG_REL_ Ladegeraet_2 SG_ 2589283656 ORU_Status 5000;
BA_REL_ "GenSigTimeoutTime" BU_SG_REL_ Ladegeraet_Konzern SG_ 2589283656 ORU_Status 5000;
BA_REL_ "GenSigTimeoutTime" BU_SG_REL_ TME SG_ 2589283656 ORU_Status 5000;
BA_REL_ "GenSigTimeoutTime" BU_SG_REL_ AWC SG_ 872 PH2_Visualisierung 5000;
BA_REL_ "GenSigTimeoutTime" BU_SG_REL_ AWC SG_ 872 PH2_Abschaltursache 5000;
BA_REL_ "GenSigTimeoutTime" BU_SG_REL_ AWC SG_ 872 PH2_Systemzustand 5000;
BA_REL_ "GenSigTimeoutTime" BU_SG_REL_ AWC SG_ 2463978617 PH2_Aufschaltursache 5000;
BA_REL_ "GenSigTimeoutTime" BU_SG_REL_ AWC SG_ 1175 PH_Visualisierung 5000;
BA_REL_ "GenSigTimeoutTime" BU_SG_REL_ AWC SG_ 1175 PH_Abschaltursache 5000;
BA_REL_ "GenSigTimeoutTime" BU_SG_REL_ AWC SG_ 1175 PH_Systemzustand 5000;
BA_REL_ "GenSigTimeoutTime" BU_SG_REL_ AWC SG_ 1355 PH_Aufschaltursache 5000;
BA_REL_ "GenSigTimeoutTime" BU_SG_REL_ TME SG_ 617 PIF_Toggle 800;
BA_REL_ "GenSigTimeoutTime" BU_SG_REL_ TME SG_ 617 PIF_ST_Status 800;
BA_REL_ "GenSigTimeoutTime" BU_SG_REL_ TME SG_ 617 PIF_MT_Status 800;
BA_REL_ "GenSigTimeoutTime" BU_SG_REL_ TME SG_ 617 PIF_LT_Status 800;
BA_REL_ "GenSigTimeoutTime" BU_SG_REL_ TME SG_ 617 PIF_Identifier 800;
BA_REL_ "GenSigTimeoutTime" BU_SG_REL_ TME SG_ 617 PIF_ST_Bin_0 800;
BA_REL_ "GenSigTimeoutTime" BU_SG_REL_ TME SG_ 617 PIF_ST_Bin_1 800;
BA_REL_ "GenSigTimeoutTime" BU_SG_REL_ TME SG_ 617 PIF_ST_Bin_2 800;
BA_REL_ "GenSigTimeoutTime" BU_SG_REL_ TME SG_ 617 PIF_ST_Bin_3 800;
BA_REL_ "GenSigTimeoutTime" BU_SG_REL_ TME SG_ 617 PIF_ST_Bin_4 800;
BA_REL_ "GenSigTimeoutTime" BU_SG_REL_ TME SG_ 617 PIF_ST_Bin_5 800;
BA_REL_ "GenSigTimeoutTime" BU_SG_REL_ TME SG_ 617 PIF_ST_Bin_6 800;
BA_REL_ "GenSigTimeoutTime" BU_SG_REL_ TME SG_ 617 PIF_ST_Bin_7 800;
BA_REL_ "GenSigTimeoutTime" BU_SG_REL_ TME SG_ 617 PIF_ST_Bin_8 800;
BA_REL_ "GenSigTimeoutTime" BU_SG_REL_ TME SG_ 617 PIF_MT_Bin_0 800;
BA_REL_ "GenSigTimeoutTime" BU_SG_REL_ TME SG_ 617 PIF_MT_Bin_1 800;
BA_REL_ "GenSigTimeoutTime" BU_SG_REL_ TME SG_ 617 PIF_MT_Bin_2 800;
BA_REL_ "GenSigTimeoutTime" BU_SG_REL_ TME SG_ 617 PIF_MT_Bin_3 800;
BA_REL_ "GenSigTimeoutTime" BU_SG_REL_ TME SG_ 617 PIF_MT_Bin_4 800;
BA_REL_ "GenSigTimeoutTime" BU_SG_REL_ TME SG_ 617 PIF_MT_Bin_5 800;
BA_REL_ "GenSigTimeoutTime" BU_SG_REL_ TME SG_ 617 PIF_MT_Bin_6 800;
BA_REL_ "GenSigTimeoutTime" BU_SG_REL_ TME SG_ 617 PIF_MT_Bin_7 800;
BA_REL_ "GenSigTimeoutTime" BU_SG_REL_ TME SG_ 617 PIF_MT_Bin_8 800;
BA_REL_ "GenSigTimeoutTime" BU_SG_REL_ TME SG_ 617 PIF_LT_Bin_0 800;
BA_REL_ "GenSigTimeoutTime" BU_SG_REL_ TME SG_ 617 PIF_LT_Bin_1 800;
BA_REL_ "GenSigTimeoutTime" BU_SG_REL_ TME SG_ 617 PIF_LT_Bin_2 800;
BA_REL_ "GenSigTimeoutTime" BU_SG_REL_ TME SG_ 617 PIF_LT_Bin_3 800;
BA_REL_ "GenSigTimeoutTime" BU_SG_REL_ TME SG_ 617 PIF_LT_Bin_4 800;
BA_REL_ "GenSigTimeoutTime" BU_SG_REL_ TME SG_ 617 PIF_LT_Bin_5 800;
BA_REL_ "GenSigTimeoutTime" BU_SG_REL_ TME SG_ 617 PIF_LT_Bin_6 800;
BA_REL_ "GenSigTimeoutTime" BU_SG_REL_ TME SG_ 617 PIF_LT_Bin_7 800;
BA_REL_ "GenSigTimeoutTime" BU_SG_REL_ TME SG_ 617 PIF_LT_Bin_8 800;
BA_REL_ "GenSigTimeoutTime" BU_SG_REL_ BMC_MLBevo SG_ 2527679715 pVS_EnergieAnfr_Zaehler 5000;
BA_REL_ "GenSigTimeoutTime" BU_SG_REL_ BMC_MLBevo SG_ 2527679715 pVS_EnergieAnfr_SocStart 5000;
BA_REL_ "GenSigTimeoutTime" BU_SG_REL_ BMC_MLBevo SG_ 2527679715 pVS_EnergieAnfr_SocZiel 5000;
BA_REL_ "GenSigTimeoutTime" BU_SG_REL_ BMC_MLBevo SG_ 2527679715 pVS_LadegrenzeAnfr_Zaehler 5000;
BA_REL_ "GenSigTimeoutTime" BU_SG_REL_ BMC_MLBevo SG_ 2527679715 pVS_LadegrenzeAnfr_Leistung 5000;
BA_REL_ "GenSigTimeoutTime" BU_SG_REL_ DCDC_800V_PAG SG_ 1616 RA_Radio_on 5000;
BA_REL_ "GenSigTimeoutTime" BU_SG_REL_ DCDC_IHEV SG_ 1616 RA_Radio_on 5000;
BA_REL_ "GenSigTimeoutTime" BU_SG_REL_ DCDC_800V_PAG SG_ 1616 RA_Frequency 5000;
BA_REL_ "GenSigTimeoutTime" BU_SG_REL_ DCDC_IHEV SG_ 1616 RA_Frequency 5000;
BA_REL_ "GenSigTimeoutTime" BU_SG_REL_ DCDC_800V_PAG SG_ 1616 RA_Frequency_unit 5000;
BA_REL_ "GenSigTimeoutTime" BU_SG_REL_ DCDC_IHEV SG_ 1616 RA_Frequency_unit 5000;
BA_REL_ "GenSigTimeoutTime" BU_SG_REL_ DCDC_800V_PAG SG_ 1616 RA_AM_Tuning 5000;
BA_REL_ "GenSigTimeoutTime" BU_SG_REL_ DCDC_IHEV SG_ 1616 RA_AM_Tuning 5000;
BA_REL_ "GenSigTimeoutTime" BU_SG_REL_ TME SG_ 1525 RW_Reservewarnung_2_aktiv 5000;
BA_REL_ "GenSigTimeoutTime" BU_SG_REL_ BMC_MLBevo SG_ 1525 RW_RWDS_Lastprofil 5000;
BA_REL_ "GenSigTimeoutTime" BU_SG_REL_ Ladegeraet_Konzern SG_ 1525 RW_Gesamt_Reichweite 5000;
BA_REL_ "GenSigTimeoutTime" BU_SG_REL_ Ladegeraet_Konzern SG_ 1525 RW_Prim_Reichweitenverbrauch 5000;
BA_REL_ "GenSigTimeoutTime" BU_SG_REL_ Ladegeraet_Konzern SG_ 1525 RW_Primaer_Reichweite 5000;
BA_REL_ "GenSigTimeoutTime" BU_SG_REL_ TME SG_ 1527 RW_Reservewarnung_aktiv 5000;
BA_REL_ "GenSigTimeoutTime" BU_SG_REL_ Ladegeraet_Konzern SG_ 1527 RW_Primaer_Reichweite_Anzeige 5000;
BA_REL_ "GenSigTimeoutTime" BU_SG_REL_ Ladegeraet_Konzern SG_ 1527 RW_Sekundaer_Reichweite 5000;
BA_REL_ "GenSigTimeoutTime" BU_SG_REL_ Gateway SG_ 2463978658 Rezi_Status_Spgfreiheit 1000;
BA_REL_ "GenSigTimeoutTime" BU_SG_REL_ Gateway SG_ 2463978658 Rezi_IstSpannung 1000;
BA_REL_ "GenSigTimeoutTime" BU_SG_REL_ Ladegeraet_Konzern SG_ 1313 STH_Funk_ein 2000;
BA_REL_ "GenSigTimeoutTime" BU_SG_REL_ Ladegeraet_Konzern SG_ 1313 STH_Funk_aus 2000;
BA_REL_ "GenSigTimeoutTime" BU_SG_REL_ TME SG_ 1313 STH_Zusatzheizung 2000;
BA_REL_ "GenSigTimeoutTime" BU_SG_REL_ TME SG_ 1313 STH_LED 2000;
BA_REL_ "GenSigTimeoutTime" BU_SG_REL_ TME SG_ 1313 STH_Pumpe_ein 2000;
BA_REL_ "GenSigTimeoutTime" BU_SG_REL_ TME SG_ 1313 STH_Geblaese 2000;
BA_REL_ "GenSigTimeoutTime" BU_SG_REL_ TME SG_ 1313 STH_Ventil_Status 2000;
BA_REL_ "GenSigTimeoutTime" BU_SG_REL_ TME SG_ 1313 STH_Fehler_ElWaPu 2000;
BA_REL_ "GenSigTimeoutTime" BU_SG_REL_ TME SG_ 1313 STH_Fehlerstatus 2000;
BA_REL_ "GenSigTimeoutTime" BU_SG_REL_ TME SG_ 1313 STH_Wassertemp 2000;
BA_REL_ "GenSigTimeoutTime" BU_SG_REL_ TME SG_ 1313 STH_Texte 2000;
BA_REL_ "GenSigTimeoutTime" BU_SG_REL_ TME SG_ 505 STP_Funktion_freigegeben 5000;
BA_REL_ "GenSigTimeoutTime" BU_SG_REL_ Gateway SG_ 1001 Thermo_Pred_T_dyn_Innen 1000;
BA_REL_ "GenSigTimeoutTime" BU_SG_REL_ Gateway_PAG SG_ 1001 Thermo_Pred_T_dyn_Innen 1000;
BA_REL_ "GenSigTimeoutTime" BU_SG_REL_ Gateway SG_ 1001 Thermo_Pred_Innen_Kunde_Anf 1000;
BA_REL_ "GenSigTimeoutTime" BU_SG_REL_ Gateway_PAG SG_ 1001 Thermo_Pred_Innen_Kunde_Anf 1000;
BA_REL_ "GenSigTimeoutTime" BU_SG_REL_ Gateway SG_ 1001 Thermo_Pred_P_dyn_Innen 1000;
BA_REL_ "GenSigTimeoutTime" BU_SG_REL_ Gateway_PAG SG_ 1001 Thermo_Pred_P_dyn_Innen 1000;
BA_REL_ "GenSigTimeoutTime" BU_SG_REL_ Gateway SG_ 1001 Thermo_Pred_P_stat_Innen 1000;
BA_REL_ "GenSigTimeoutTime" BU_SG_REL_ Gateway_PAG SG_ 1001 Thermo_Pred_P_stat_Innen 1000;
BA_REL_ "GenSigTimeoutTime" BU_SG_REL_ Gateway SG_ 1001 Thermo_Verbrauch_BTL 1000;
BA_REL_ "GenSigTimeoutTime" BU_SG_REL_ Gateway_PAG SG_ 1001 Thermo_Verbrauch_BTL 1000;
BA_REL_ "GenSigTimeoutTime" BU_SG_REL_ Gateway SG_ 1001 Thermo_Verbrauch_BTL_Ueberlauf 1000;
BA_REL_ "GenSigTimeoutTime" BU_SG_REL_ Gateway_PAG SG_ 1001 Thermo_Verbrauch_BTL_Ueberlauf 1000;
BA_REL_ "GenSigTimeoutTime" BU_SG_REL_ Gateway SG_ 1001 Thermo_Pred_Innen_System_Anf 1000;
BA_REL_ "GenSigTimeoutTime" BU_SG_REL_ Gateway_PAG SG_ 1001 Thermo_Pred_Innen_System_Anf 1000;
BA_REL_ "GenSigTimeoutTime" BU_SG_REL_ Gateway SG_ 1001 Thermo_Verbrauch_Innen 1000;
BA_REL_ "GenSigTimeoutTime" BU_SG_REL_ Gateway_PAG SG_ 1001 Thermo_Verbrauch_Innen 1000;
BA_REL_ "GenSigTimeoutTime" BU_SG_REL_ Gateway SG_ 1001 Thermo_Verbrauch_Innen_Ueberlauf 1000;
BA_REL_ "GenSigTimeoutTime" BU_SG_REL_ Gateway_PAG SG_ 1001 Thermo_Verbrauch_Innen_Ueberlauf 1000;
BA_REL_ "GenSigTimeoutTime" BU_SG_REL_ Gateway SG_ 1015 KL_HV_Energie_Anf 1000;
BA_REL_ "GenSigTimeoutTime" BU_SG_REL_ Gateway_PAG SG_ 1015 KL_HV_Energie_Anf 1000;
BA_REL_ "GenSigTimeoutTime" BU_SG_REL_ Ladegeraet_Konzern SG_ 1015 KL_HV_Energie_Anf 1000;
BA_REL_ "GenSigTimeoutTime" BU_SG_REL_ Gateway SG_ 1015 TME_HVEM_HV_Anf 1000;
BA_REL_ "GenSigTimeoutTime" BU_SG_REL_ Gateway_PAG SG_ 1015 TME_HVEM_HV_Anf 1000;
BA_REL_ "GenSigTimeoutTime" BU_SG_REL_ Gateway SG_ 1015 TME_StartStopp_Info 1000;
BA_REL_ "GenSigTimeoutTime" BU_SG_REL_ Gateway_PAG SG_ 1015 TME_StartStopp_Info 1000;
BA_REL_ "GenSigTimeoutTime" BU_SG_REL_ Gateway SG_ 1015 TME_HVPTC_Istmodus 1000;
BA_REL_ "GenSigTimeoutTime" BU_SG_REL_ Gateway_PAG SG_ 1015 TME_HVPTC_Istmodus 1000;
BA_REL_ "GenSigTimeoutTime" BU_SG_REL_ Gateway SG_ 1015 TME_HVPTC_Fehlerstatus 1000;
BA_REL_ "GenSigTimeoutTime" BU_SG_REL_ Gateway_PAG SG_ 1015 TME_HVPTC_Fehlerstatus 1000;
BA_REL_ "GenSigTimeoutTime" BU_SG_REL_ Gateway SG_ 1015 TME_EKK_Istmodus 1000;
BA_REL_ "GenSigTimeoutTime" BU_SG_REL_ Gateway_PAG SG_ 1015 TME_EKK_Istmodus 1000;
BA_REL_ "GenSigTimeoutTime" BU_SG_REL_ Gateway SG_ 1015 TME_EKK_Fehlerstatus 1000;
BA_REL_ "GenSigTimeoutTime" BU_SG_REL_ Gateway_PAG SG_ 1015 TME_EKK_Fehlerstatus 1000;
BA_REL_ "GenSigTimeoutTime" BU_SG_REL_ Gateway SG_ 1015 TME_HVK_EKK_SOLL 1000;
BA_REL_ "GenSigTimeoutTime" BU_SG_REL_ Gateway_PAG SG_ 1015 TME_HVK_EKK_SOLL 1000;
BA_REL_ "GenSigTimeoutTime" BU_SG_REL_ Gateway SG_ 1015 TME_Strom_Kuehlerluefter 1000;
BA_REL_ "GenSigTimeoutTime" BU_SG_REL_ Gateway_PAG SG_ 1015 TME_Strom_Kuehlerluefter 1000;
BA_REL_ "GenSigTimeoutTime" BU_SG_REL_ BMC_MLBevo SG_ 1015 TME_PWM_Pumpe1_tNT_Soll 1000;
BA_REL_ "GenSigTimeoutTime" BU_SG_REL_ DCDC_800V_PAG SG_ 1017 TME_NT_Kreis_Status 2000;
BA_REL_ "GenSigTimeoutTime" BU_SG_REL_ DCDC_HV SG_ 1017 TME_NT_Kreis_Status 2000;
BA_REL_ "GenSigTimeoutTime" BU_SG_REL_ LE1 SG_ 1017 TME_NT_Kreis_Status 2000;
BA_REL_ "GenSigTimeoutTime" BU_SG_REL_ LE2 SG_ 1017 TME_NT_Kreis_Status 2000;
BA_REL_ "GenSigTimeoutTime" BU_SG_REL_ LE_MLBevo SG_ 1017 TME_NT_Kreis_Status 2000;
VAL_ 2600468546 NM_TME_SNI 66 "TME" ;
VAL_ 2600468546 NM_TME_CBV_AWB 0 "Passiver_WakeUp" 1 "Aktiver_WakeUp" ;
VAL_ 2600468546 NM_TME_CBV_CRI 0 "Standard_Layout" 1 "TNB_Layout" ;
VAL_ 2600468546 NM_TME_NM_State 0 "Init" 1 "NM_RM_aus_BSM" 2 "NM_RM_aus_PBSM" 4 "NM_NO_aus_RM" 8 "NM_NO_aus_RS" 16 "NM_RM_aus_RS" 32 "NM_RM_aus_NO" ;
VAL_ 2600468546 NM_TME_Car_Wakeup 0 "Inaktiv" 1 "Car_Wakeup" ;
VAL_ 2600468546 NM_TME_UDS_CC 0 "Init" 1 "CC_aktiv" ;
VAL_ 2600468546 NM_TME_NM_aktiv_KL15 0 "Inaktiv" 1 "KL15_EIN" ;
VAL_ 2600468546 NM_TME_NM_aktiv_Diagnose 0 "Init" 1 "Diagnose_aktiv" ;
VAL_ 2600468546 NM_TME_NM_aktiv_Tmin 0 "Inaktiv" 1 "Mindestaktivzeit" ;
VAL_ 2600468546 NM_TME_NM_aktiv_Berechnung 0 "inaktiv" 1 "Berechnung_Vorkond_aktiv" ;
VAL_ 2600468546 NM_TME_NM_aktiv_Vorkondition 0 "Vorkonditionierung_nicht_aktiv" 1 "Vorkonditionierung_aktiv" ;
VAL_ 2600468546 NM_TME_NM_aktiv_HV_Auszeitber 0 "inaktiv" 1 "Nachlauf_aufgrund_HV_Auszeitberechnung_aktiv" ;
VAL_ 2600468546 NM_TME_NM_aktiv_Ventilsteuerung 0 "Inaktiv" 1 "Ventilsteuerung_aktiv" ;
VAL_ 2600468546 NM_TME_NM_aktiv_Kuehlung 0 "inaktiv" 1 "Kuehlung_aktiv" ;
VAL_ 2600468546 NM_TME_CAB 0 "inaktiv" 1 "CAB_01__Tueren" 2 "CAB_02__Anhaenger_KCAN" 4 "CAB_03__Nightvision" 8 "CAB_04__Sitzverstellung" 16 "CAB_05__Klappen" 32 "CAB_06__Infotainment" 64 "CAB_07__Sub_Infotainment" 128 "CAB_08__Anzeige" 256 "CAB_09__Laden_HCAN" 512 "CAB_10__Klima" 1024 "CAB_11__FlexRay" 262144 "CAB_19__VLAN_RemoteFC" 524288 "CAB_20__VLAN_Komfort" 1048576 "CAB_21__VLAN_Internet" 2097152 "CAB_22__VLAN_Connect" 4194304 "CAB_23__VLAN_Infotainment" 8388608 "CAB_24__VLAN_FAS" ;
VAL_ 1635 BEM_02_Abschaltstufen 0 "Stufe 0 (keine Einschraenkungen)" 1 "Stufe 1" 2 "Stufe 2" 3 "Stufe 3" 4 "Transportmodus" 7 "Ruhestrommessmodus" ;
VAL_ 1635 BEM_STH_Zielzeit 14 "Init" 15 "Fehler" ;
VAL_ 1635 BEM_MMI_Vorwarnung 0 "keine Anzeige" 1 "Anzeige MMI-Vorwarnung" ;
VAL_ 1635 NVEM_Anf_SD_schalten 0 "Anf_SD_Nachlauf_nicht_aktiv" 1 "Anf_SD_Nachlauf_aktiv" ;
VAL_ 1635 BEM_Generatordiagnose 0 "keine Anzeige" 1 "Ladekontrollanzeige ein (Vorhalt)" 2 "rotes Batteriesymbol und Text (Generator defekt)" 3 "Hybrid_DCDC_Wandler_defekt" ;
VAL_ 1635 BEM_Red_Innengeblaese 0 "keine Reduzierung" 1 "Reduzierung Stufe 1" 2 "Reduzierung Stufe 2" 3 "Reduzierung Stufe 2 und Abschaltung Kompressor" ;
VAL_ 1635 BEM_STH_Einschaltverbot 0 "volle Verfuegbarkeit Standheizung/-lueftung" 1 "Standheizung/-lueftung nicht aktivierbar" ;
VAL_ 1635 BEM_HL_Regelung_Status 0 "HL_Regelung_inaktiv_(vor_und_waehrend_Motorstart)" 1 "HL_Regelung_Stufe_1" 2 "HL_Regelung_Stufe_2" 3 "HL_Regelung_Stufe_3" 4 "Verbrauchernotabschaltung_(VNA)" 5 "HL_Regelung_Stufe_5" 7 "Default" ;
VAL_ 1635 BEM_Ladezustand 14 "Init" 15 "Fehler" ;
VAL_ 1635 BEM_Batteriediagnose 0 "keine_Anzeige" 1 "nicht_belegt" 2 "Anzeige_aberkannte_Batterie" 3 "Anzeige_schwache_Batterie" 4 "Anzeige_Batterie_OK" 5 "Anzeige_Batterie_Laden" 6 "Anzeige_Batterie_Pruefen" 7 "Fehler" ;
VAL_ 1635 MIB_Stromsparmodus 0 "inaktiv" 1 "aktiv" ;
VAL_ 1635 BEM_REK_aktiv 0 "keine_Rekuperationsfreigabe" 1 "Rekuperationsfreigabe" ;
VAL_ 1635 NVEM_Last_Anf 0 "keine Anforderung" 1 "Verbraucher_Anforderung_Stufe_1" 2 "Verbraucher_Anforderung_Stufe_2" 3 "Verbraucher_Anforderung_Stufe_3" ;
VAL_ 1635 BEM_UBDM 0 "Init" 255 "Fehler" ;
VAL_ 1635 BEM_Anf_KL15_schalten 0 "Keine_Einschraenkung_Kl15" 1 "Empfehlung_auto_Abschaltung_Kl15" 2 "Veto_auto_Abschaltung_Kl15" 3 "Veto_auto_Abschaltung_Fahrtbetrieb" ;
VAL_ 1635 NVEM_Batterie_Service 0 "kein_Service" 1 "Service_Information1" 2 "Service_Information2" 3 "Service_Information3" ;
VAL_ 1635 NVEM_Freigabe_OnlineUpdate 0 "keine_Freigabe" 1 "Freigabe" ;
VAL_ 1635 NVEM_Freigabe_ORU4 0 "Init" 1 "keine_Freigabe" 2 "Freigabe_erteilt" 3 "Veto_Freigabe" ;
VAL_ 869 NVEM_Pilot_Info 0 "Init" 1 "keine_Einschraenkung" 2 "Veto_1" 3 "Veto_2" ;
VAL_ 869 NVEM_P_Generator_Status 0 "gefiltert" 1 "ungefiltert" ;
VAL_ 869 BEM_P_Generator 255 "Fehler" ;
VAL_ 869 BEM_n_LLA 0 "keine_Erhoehung" 1 "Stufe_1" 2 "Stufe_2" 3 "Stufe_3" ;
VAL_ 869 BEM_Anf_KL 0 "keine Anforderung" 1 "Anforderung Kühlerlüfter Ansteuerung" ;
VAL_ 869 BEM_StartStopp_Info 0 "Motorlauf_nicht_notwendig_(Stoppfreigabe)" 1 "Motoranlauf_nicht_zwingend_notwendig_(Stoppverbot,keine_Startanforderung)" 2 "Motoranlauf_zwingend_notwendig_(Startanforderung)" 3 "Systemfehler" ;
VAL_ 869 BEM_Batt_Ab 0 "verbunden" 1 "nicht_verbunden" ;
VAL_ 869 BEM_Hybrid_Info 0 "keine_Einschraenkung_durch_Energiemanagement" 1 "Motorstart_ueber_12V_Starter_nur_bei_0kmh_moeglich" 2 "kein_Motorstart_ueber_12V_Starter_nach_el_Fahrtbetrieb" 3 "Systemfehler" ;
VAL_ 869 NVEM_Red_KL 0 "Init" 1 "Abschaltung_KL" 2 "Reduzierung_KL" ;
VAL_ 869 NVEM_Freilauf_Info 0 "Freilauf_freigegeben" 1 "Weiches_Veto_uebertippbar" 2 "Hartes_Veto_Abbruch" 3 "Freilauf_Anforderung" ;
VAL_ 869 BEM_HYB_DC_uMinLV 254 "Init" 255 "Fehler" ;
VAL_ 2527679508 NVEM_Max_Rampenzeit 0 "No_LRC" 1 "250ms" 2 "500ms" 3 "750ms" 4 "1s" 5 "2s" 6 "3s" 7 "4s" 8 "5s" 9 "6s" 10 "7s" 11 "8s" 12 "9s" 13 "10s" 14 "12s" 15 "15s" ;
VAL_ 2527679508 NVEM_Min_Spannung 126 "Init" 127 "Fehler" ;
VAL_ 2527679508 NVEM_Min_Spannung_Start 62 "Init" 63 "Fehler" ;
VAL_ 2527679508 NVEM_Max_Spannung 126 "Init" 127 "Fehler" ;
VAL_ 2527679508 NVEM_Energie_Klima_Vorgabe 254 "Init" 255 "Fehler" ;
VAL_ 2527679508 NVEM_MV_DC_uMinLV 126 "Init" 127 "Fehler" ;
VAL_ 2527679508 NVEM_MV_DC_uSollLV 126 "Init" 127 "Fehler" ;
VAL_ 2527679508 NVEM_Bordnetzdiagnose 0 "kein_Fehler" 1 "Warnung_1" 2 "Warnung_2" 3 "Warnung_3" ;
VAL_ 2527679509 NVEM_BMS_NV_Imax_RSG_Anf 62 "Init" 63 "Fehler" ;
VAL_ 2527679509 NVEM_BMS_NV_Umin_RSG_Anf 62 "Init" 63 "Fehler" ;
VAL_ 2527679509 NVEM_BMS_NV_Nachlaufzeit_Vorgabe 62 "Init" 63 "Fehler" ;
VAL_ 2527679509 NVEM_BMS_NV_Umin_Anf 62 "Init" 63 "Fehler" ;
VAL_ 2527679509 NVEM_FMAus_I_Verbrauch 30 "Init" 31 "Fehler" ;
VAL_ 2527679509 NVEM_BMS_NV_Impuls_Abfrage 0 "inaktiv" 1 "aktiv" ;
VAL_ 2527679509 NVEM_BMS_NV_Sollmodus 0 "TE_oeffnen" 1 "TE_schliessen" 3 "Init" ;
VAL_ 527 NVEM_DC_uSoll_NV 255 "Fehler" ;
VAL_ 913 MO_Servicemodus 0 "nicht_aktiv" 1 "Service_Mode_1" 2 "Service_Mode_2" 3 "Service_Mode_3" 4 "Service_Mode_4" 5 "Service_Mode_5" 6 "Service_Mode_6" 7 "Service_Mode_7" 8 "Service_Mode_8" 9 "Service_Mode_9" 10 "Service_Mode_10" 11 "Service_Mode_11" 12 "Service_Mode_12" 13 "Service_Mode_13" 14 "Service_Mode_14" 15 "Service_Mode_15" ;
VAL_ 913 OBD_ClearMem_Inhibit 0 "FSP_Loeschen_zulaessig" 1 "FSP_Loeschen_nicht_zulaessig" ;
VAL_ 913 OBD_Sperrung_Kaltstart_Denom 0 "EVAP_Berechnung_freigegeben" 1 "EVAP_Berechnung_gesperrt" ;
VAL_ 913 MO_QBit_Aussen_Temp 0 "gueltiger_Wert" 1 "Ersatz_Init_oder_Fehlerwert" ;
VAL_ 913 OBD_Sperrung_IUMPR 0 "IUMPR_Berechnung_freigegeben" 1 "IUMPR_Berechnung_gesperrt" ;
VAL_ 913 OBD_Kaltstart_Denominator 0 "Denominator_nicht_hochzaehlen" 1 "Bedingungen_zum_Inkr_des_Kaltstart_Denom_erf" ;
VAL_ 913 OBD_Minimum_Trip 0 "kein_Min_Normed_Trip" 1 "Min_Normed_Trip" ;
VAL_ 913 OBD_Driving_Cycle 0 "kein Driving Cycle erkannt" 1 "DC erkannt" ;
VAL_ 913 OBD_Warm_Up_Cycle 0 "kein Warm Up Cycle erkannt" 1 "Warm Up Cycle erkannt" ;
VAL_ 913 OBD_Normed_Trip 0 "kein Normed Trip" 1 "Normed Trip erfüllt" ;
VAL_ 2589283656 ORU_Warnung 0 "keine_Anzeige" 1 "Update_unvollstaendig_Prio1" 2 "Update_fehlgeschlagen_Prio1" 3 "reserviert" ;
VAL_ 2589283656 ORU_Status 0 "IDLE" 1 "PENDING" 2 "PREPARATION" 3 "PREPARATION_HV" 4 "RUNNING" 5 "RUNNING_HV" 6 "PENDING_NOTREADY" ;
VAL_ 872 PH2_Visualisierung 0 "Aus" 1 "Angefragt" 2 "InAnzeige" 3 "Abgefordert" 6 "Init" 7 "Fehler" ;
VAL_ 872 PDC2_Tonausgabe_Front 0 "kein_Ton" 1 "Intervallton_1" 2 "Intervallton_2" 3 "Intervallton_3" 4 "Intervallton_4" 5 "Intervallton_5" 6 "Dauerton" 7 "Fehlerton" 8 "FCTAton" ;
VAL_ 872 PDC2_Tonausgabe_Heck 0 "kein_Ton" 1 "Intervallton_1" 2 "Intervallton_2" 3 "Intervallton_3" 4 "Intervallton_4" 5 "Intervallton_5" 6 "Dauerton" 7 "Fehlerton" 8 "Erstwarnton_hinten" 9 "RCTATon" ;
VAL_ 872 PH2_nachtr_Stopp_An 0 "nicht_angefordert" 1 "angefordert" ;
VAL_ 872 PH2_Abschaltursache 0 "keine, bzw. System aktiv" 1 "Abschaltung durch Herausnahme R-Gang" 2 "Abschaltung ueber Geschwindigkeit" 3 "Abschaltung ueber PDC-Taster" 4 "Abschaltung wegen PLA" 5 "Abschaltung durch KL 15 Bit = 0" 6 "tbd." 7 "Fehler-/gestört Zustand, System noch aktiv" ;
VAL_ 872 PH2_Opt_Anzeige_V_ein 0 "optische Anzeige vorne nicht aktiv" 1 "optische Anzeige vorne aktiviert" ;
VAL_ 872 PH2_Opt_Anzeige_H_ein 0 "Optische Anzeige aus" 1 "optische Anzeige hinten aktiviert" ;
VAL_ 872 PH2_Opt_Anz_V_Hindernis 0 "optische Anzeige vorne meldet kein Hindernis" 1 "optische Anzeige vorne meldet Hindernis im Warnbereich" ;
VAL_ 872 PH2_Opt_Anz_H_Hindernis 0 "optische Anzeige hinten meldet kein Hindernis" 1 "optische Anzeige hinten meldet Hindernis im Warnbereich" ;
VAL_ 872 PH2_Tongeber_V_aktiv 0 "Tongeber vorne nicht aktiv" 1 "Tongeber vorne  aktiv" ;
VAL_ 872 PH2_Tongeber_H_aktiv 0 "Tongeber hinten nicht aktiv" 1 "Tongeber hinten aktiv" ;
VAL_ 872 PH2_Tongeber_mute 0 "Tongeber nicht stummgeschaltet" 1 "Tongeber stummgeschaltet" ;
VAL_ 872 PH2_Anf_Audioabsenkung 0 "keine Absenkung der Lautstärke" 1 "Anforderung an das Audiosystem für Absenkung der Lautstärke" ;
VAL_ 872 PH2_Tongeber_H_verfuegbar 0 "nicht verfügbar" 1 "verfügbar" ;
VAL_ 872 PH2_Taster 0 "Taster_nicht_gedrueckt" 1 "Taster_gedrueckt" 2 "reserviert" 3 "Fehler" ;
VAL_ 872 PH2_Anf_Verdeck 0 "Verdeckbetrieb_freigegeben" 1 "Verdeckbetrieb_sperren" 2 "reserviert" 3 "reserviert" ;
VAL_ 872 PH2_StartStopp_Info 0 "Motorlauf_nicht_notwendig_(Stoppfreigabe)" 1 "Motoranlauf_nicht_zwingend_notwendig_(Stoppverbot,keine_Startanforderung)" 2 "Motoranlauf_zwingend_notwendig_(Startanforderung)" 3 "Systemfehler" ;
VAL_ 872 PH2_Stoermeldung 0 "keine_Anzeige_kein_Gong" 1 "Textmeldung_PDC_hinten_gestoert_mit_Gong" 2 "Textmeldung_PDC_hinten_gestoert_ohne_Gong" 3 "Textmeldung_PDC_vorn_gestoert_mit_Gong" 4 "Textmeldung_PDC_vorn_gestoert_ohne_Gong" 5 "Textmeldung_PDC_gestoert_mit_Gong" 6 "Textmeldung_PDC_gestoert_ohne_Gong" 7 "Textmeldung_PDC_seitlich_gestoert_mit_Gong" 8 "Textmeldung_PDC_seitlich_gestoert_ohne_Gong" ;
VAL_ 872 PH2_defekt 0 "PH aktiv" 1 "PH wurde aufgrund eines Defektes deaktiviert" ;
VAL_ 872 PH2_gestoert 0 "PH aktiv" 1 "PH wurde auf Grund einer Stoerung tempraer deaktiviert" ;
VAL_ 872 PH2_Systemzustand 0 "Anlage aus" 1 "Anlage durch einlegen R-Gang aktiviert" 2 "Anlage manuell durch Taster aktiviert" 3 "Anlage automatisch aktiviert" 4 "Anlage_durch_ARA_aktiviert" 6 "Init_Initialisierungsphase_nach_Kl15_ein_oder_Reset" 7 "Fehler-/gestört Zustand, System noch aktiv" ;
VAL_ 872 PH2_Display_Kundenwunsch 0 "Anzeige aus" 1 "Grafik" 2 "Rear View" 3 "automatisch" ;
VAL_ 2463978617 PH2_Verschmutzungsmeldung 0 "keine_Anzeige_kein_Gong" 1 "Textmeldung_PDC_hinten_verschmutzt_mit_Gong" 2 "Textmeldung_PDC_hinten_verschmutzt_ohne_Gong" 3 "Textmeldung_PDC_vorn_verschmutzt_mit_Gong" 4 "Textmeldung_PDC_vorn_verschmutzt_ohne_Gong" 5 "Textmeldung_PDC_verschmutzt_mit_Gong" 6 "Textmeldung_PDC_verschmutzt_ohne_Gong" 7 "Textmeldung_PDC_seitlich_verschmutzt_mit_Gong" 8 "Textmeldung_PDC_seitlich_verschmutzt_ohne_Gong" ;
VAL_ 2463978617 PH2_Aufschaltursache 0 "Anlage aus" 1 "Anlage durch einlegen R-Gang aktiviert" 2 "Anlage manuell durch Taster aktiviert" 3 "Anlage automatisch aktiviert" 4 "Anlage durch ARA aktiviert" 5 "Rueckwaertsrollen" 6 "Anlage_durch_PLA_aktiviert" 7 "Anlage_durch_IPA_aktiviert" 8 "Anlage_durch_FA_aktiviert" 9 "Anlage_durch_RBF_oder_MA_aktiviert" 10 "Anlage_durch_Smartphone_aktiviert" 11 "Anlage_durch_Jokertaste_aktiviert" 12 "Anlage_durch_Favoritentasten_aktiviert" 13 "Anlage_durch_SideViewTaster_aktiviert" 14 "Anlage_durch_RCTA_aktiviert" 15 "Anlage_durch_KAS_aktiviert" 16 "Anlage_durch_AWC_aktiviert" 30 "Init_Initialisierungsphase_nach_Kl_15_ein_oder_Reset" 31 "Fehler_gestoerter_Zustand_System_noch_aktiv" ;
VAL_ 2463978617 PH2_WAH_Meldung 0 "Init" 1 "Fehlermeldung_bei_Nichtverfuegbarkeit_mit_Gong" 2 "Fehlermeldung_bei_Nichtverfuegbarkeit_ohne_Gong" 3 "Anzeige_dass_Fahrzeug_erkannt_wurde_und_Funktion_aktiv_ist" 4 "Wiederanfahrhinweis_mit_Gong" 5 "Wiederanfahrhinweis_ohne_Gong" ;
VAL_ 1175 PH_Visualisierung 0 "Aus" 1 "Angefragt" 2 "InAnzeige" 3 "Abgefordert" 6 "Init" 7 "Fehler" ;
VAL_ 1175 PDC_Tonausgabe_Front 0 "kein_Ton" 1 "Intervallton_1" 2 "Intervallton_2" 3 "Intervallton_3" 4 "Intervallton_4" 5 "Intervallton_5" 6 "Dauerton" 7 "Fehlerton" 8 "RCTATon" ;
VAL_ 1175 PDC_Tonausgabe_Heck 0 "kein_Ton" 1 "Intervallton_1" 2 "Intervallton_2" 3 "Intervallton_3" 4 "Intervallton_4" 5 "Intervallton_5" 6 "Dauerton" 7 "Fehlerton" 8 "Erstwarnton_hinten" 9 "RCTATon" ;
VAL_ 1175 PH_nachtr_Stopp_Anf 0 "nicht_angefordert" 1 "angefordert" ;
VAL_ 1175 PH_Abschaltursache 0 "keine, bzw. System aktiv" 1 "Abschaltung durch Herausnahme R-Gang" 2 "Abschaltung ueber Geschwindigkeit" 3 "Abschaltung ueber PDC-Taster" 4 "Abschaltung wegen PLA" 5 "Abschaltung durch KL 15 Bit = 0" 6 "tbd." 7 "Fehler-/gestört Zustand, System noch aktiv" ;
VAL_ 1175 PH_Opt_Anzeige_V_ein 0 "optische Anzeige vorne nicht aktiv" 1 "optische Anzeige vorne aktiviert" ;
VAL_ 1175 PH_Opt_Anzeige_H_ein 0 "Optische Anzeige aus" 1 "optische Anzeige hinten aktiviert" ;
VAL_ 1175 PH_Opt_Anz_V_Hindernis 0 "optische Anzeige vorne meldet kein Hindernis" 1 "optische Anzeige vorne meldet Hindernis im Warnbereich" ;
VAL_ 1175 PH_Opt_Anz_H_Hindernis 0 "optische Anzeige hinten meldet kein Hindernis" 1 "optische Anzeige hinten meldet Hindernis im Warnbereich" ;
VAL_ 1175 PH_Tongeber_V_aktiv 0 "Tongeber vorne nicht aktiv" 1 "Tongeber vorne  aktiv" ;
VAL_ 1175 PH_Tongeber_H_aktiv 0 "Tongeber hinten nicht aktiv" 1 "Tongeber hinten aktiv" ;
VAL_ 1175 PH_Tongeber_mute 0 "Tongeber nicht stummgeschaltet" 1 "Tongeber stummgeschaltet" ;
VAL_ 1175 PH_Anf_Audioabsenkung 0 "keine Absenkung der Lautstärke" 1 "Anforderung an das Audiosystem für Absenkung der Lautstärke" ;
VAL_ 1175 PH_Tongeber_H_verfuegbar 0 "nicht verfügbar" 1 "verfügbar" ;
VAL_ 1175 PLA_Anf_Aufschaltung_RVC 0 "Keine_RVC_Aufschalteanf" 1 "RVC_Aufschalteanforderung" ;
VAL_ 1175 PH_Taster 0 "Taster_nicht_gedrueckt" 1 "Taster_gedrueckt" 2 "reserviert" 3 "Fehler" ;
VAL_ 1175 PH_Anf_Verdeck 0 "Verdeckbetrieb_freigegeben" 1 "Verdeckbetrieb_sperren" 2 "reserviert" 3 "reserviert" ;
VAL_ 1175 PH_StartStopp_Info 0 "Motorlauf_nicht_notwendig_(Stoppfreigabe)" 1 "Motoranlauf_nicht_zwingend_notwendig_(Stoppverbot,keine_Startanforderung)" 2 "Motoranlauf_zwingend_notwendig_(Startanforderung)" 3 "Systemfehler" ;
VAL_ 1175 PH_Stoermeldung 0 "keine_Anzeige_kein_Gong" 1 "Textmeldung_PDC_hinten_gestoert_mit_Gong" 2 "Textmeldung_PDC_hinten_gestoert_ohne_Gong" 3 "Textmeldung_PDC_vorn_gestoert_mit_Gong" 4 "Textmeldung_PDC_vorn_gestoert_ohne_Gong" 5 "Textmeldung_PDC_gestoert_mit_Gong" 6 "Textmeldung_PDC_gestoert_ohne_Gong" 7 "Textmeldung_PDC_seitlich_gestoert_mit_Gong" 8 "Textmeldung_PDC_seitlich_gestoert_ohne_Gong" ;
VAL_ 1175 PH_defekt 0 "PH aktiv" 1 "PH wurde aufgrund eines Defektes deaktiviert" ;
VAL_ 1175 PH_gestoert 0 "PH aktiv" 1 "PH wurde auf Grund einer Stoerung tempraer deaktiviert" ;
VAL_ 1175 PH_Systemzustand 0 "Anlage aus" 1 "Anlage durch einlegen R-Gang aktiviert" 2 "Anlage manuell durch Taster aktiviert" 3 "Anlage automatisch aktiviert" 4 "Anlage durch ARA aktiviert" 6 "Init - Initialisierungsphase nach Kl. 15 ein / Reset" 7 "Fehler-/gestört Zustand, System noch aktiv" ;
VAL_ 1175 PH_Display_Kundenwunsch 0 "Anzeige aus" 1 "Grafik" 2 "Rear View" 3 "automatisch" ;
VAL_ 1355 PH_Verschmutzungsmeldung 0 "keine_Anzeige_kein_Gong" 1 "Textmeldung_PDC_hinten_verschmutzt_mit_Gong" 2 "Textmeldung_PDC_hinten_verschmutzt_ohne_Gong" 3 "Textmeldung_PDC_vorn_verschmutzt_mit_Gong" 4 "Textmeldung_PDC_vorn_verschmutzt_ohne_Gong" 5 "Textmeldung_PDC_verschmutzt_mit_Gong" 6 "Textmeldung_PDC_verschmutzt_ohne_Gong" 7 "Textmeldung_PDC_seitlich_verschmutzt_mit_Gong" 8 "Textmeldung_PDC_seitlich_verschmutzt_ohne_Gong" ;
VAL_ 1355 PH_Aufschaltursache 0 "Anlage aus" 1 "Anlage durch einlegen R-Gang aktiviert" 2 "Anlage manuell durch Taster aktiviert" 3 "Anlage automatisch aktiviert" 4 "Anlage durch ARA aktiviert" 5 "Rueckwaertsrollen" 6 "Anlage_durch_PLA_aktiviert" 7 "Anlage_durch_IPA_aktiviert" 8 "Anlage_durch_FA_aktiviert" 9 "Anlage_durch_RBF_oder_MA_aktiviert" 10 "Anlage_durch_Smartphone_aktiviert" 11 "Anlage_durch_Jokertaste_aktiviert" 12 "Anlage_durch_Favoritentasten_aktiviert" 13 "Anlage_durch_SideViewTaster_aktiviert" 14 "Anlage_durch_RCTA_aktiviert" 15 "Anlage_durch_KAS_aktiviert" 16 "Anlage_durch_AWC_aktiviert" 30 "Init_Initialisierungsphase_nach_Kl_15_ein_oder_Reset" 31 "Fehler_gestoerter_Zustand_System_noch_aktiv" ;
VAL_ 1355 PH_Ton_Ausgabe 0 "Init" 1 "Intervallton_vorne" 2 "Intervallton_hinten" 3 "Dauerton_vorne" 4 "Dauerton_hinten" 5 "Quittierungston" 6 "Reserviert" 7 "Fehler" ;
VAL_ 1355 PH_Ton_Pausenlaenge 0 "Init" 1 "Pause_5ms" 2 "Pause_10ms" 3 "Pause_15ms" 100 "Pause_500ms" 101 "Reserviert" 126 "Reserviert" 127 "Fehler" ;
VAL_ 1355 PH_Ton_Richtung 0 "vorne" 1 "vorne_rechts" 2 "rechts" 3 "rechts_hinten" 4 "hinten" 5 "hinten_links" 6 "links" 7 "vorne_links" ;
VAL_ 1355 PH_Ton_Lautstaerke 0 "Minimallautstaerke" 1 "Lautstaerke_1" 2 "Lautstaerke_2" 3 "Lautstaerke_3" 4 "Lautstaerke_4" 5 "Lautstaerke_5" 6 "Lautstaerke_6" 7 "Maximallautstaerke" ;
VAL_ 1355 BCM_WAH_Meldung 0 "Init" 1 "Fehlermeldung_bei_Nichtverfuegbarkeit_mit_Gong" 2 "Fehlermeldung_bei_Nichtverfuegbarkeit_ohne_Gong" 3 "Anzeige_dass_Fahrzeug_erkannt_wurde_und_Funktion_aktiv_ist" 4 "Wiederanfahrhinweis_mit_Gong" 5 "Wiederanfahrhinweis_ohne_Gong" ;
VAL_ 1355 PDC_Charisma_Status 0 "Init" 1 "verfuegbar" 2 "nicht_verfuegbar" 3 "asynchron_durch_Fahrerwunsch" ;
VAL_ 1355 PDC_Charisma_FahrPr 0 "keine_Funktion" 1 "Programm_1" 2 "Programm_2" 3 "Programm_3" 4 "Programm_4" 5 "Programm_5" 6 "Programm_6" 7 "Programm_7" 8 "Programm_8" 9 "Programm_9" 10 "Programm_10" 11 "Programm_11" 12 "Programm_12" 13 "Programm_13" 14 "Programm_14" 15 "Programm_15" ;
VAL_ 617 PIF_Toggle 0 "aktiv" 1 "aktiv" ;
VAL_ 617 PIF_ST_Status 0 "Init" 1 "Invalid" 2 "valid" 3 "reserviert" ;
VAL_ 617 PIF_MT_Status 0 "Init" 1 "Invalid" 2 "valid" 3 "reserviert" ;
VAL_ 617 PIF_LT_Status 0 "Init" 1 "Invalid" 2 "valid" 3 "reserviert" ;
VAL_ 617 PIF_Identifier 0 "Init" 1 "PIF_Geschwindigkeit" 2 "PIF_Laengsbeschleunigung" 3 "PIF_Leistung" 4 "PIF_Querbeschleunigung" 5 "PIF_Strassenklasse" 6 "reserviert" 7 "reserviert" ;
VAL_ 617 PIF_ST_Bin_0 0 "ausgeschlossen" 1 "unwahrscheinlich" 2 "wahrscheinlich" 3 "sehr_wahrscheinlich" ;
VAL_ 617 PIF_ST_Bin_1 0 "ausgeschlossen" 1 "unwahrscheinlich" 2 "wahrscheinlich" 3 "sehr_wahrscheinlich" ;
VAL_ 617 PIF_ST_Bin_2 0 "ausgeschlossen" 1 "unwahrscheinlich" 2 "wahrscheinlich" 3 "sehr_wahrscheinlich" ;
VAL_ 617 PIF_ST_Bin_3 0 "ausgeschlossen" 1 "unwahrscheinlich" 2 "wahrscheinlich" 3 "sehr_wahrscheinlich" ;
VAL_ 617 PIF_ST_Bin_4 0 "ausgeschlossen" 1 "unwahrscheinlich" 2 "wahrscheinlich" 3 "sehr_wahrscheinlich" ;
VAL_ 617 PIF_ST_Bin_5 0 "ausgeschlossen" 1 "unwahrscheinlich" 2 "wahrscheinlich" 3 "sehr_wahrscheinlich" ;
VAL_ 617 PIF_ST_Bin_6 0 "ausgeschlossen" 1 "unwahrscheinlich" 2 "wahrscheinlich" 3 "sehr_wahrscheinlich" ;
VAL_ 617 PIF_ST_Bin_7 0 "ausgeschlossen" 1 "unwahrscheinlich" 2 "wahrscheinlich" 3 "sehr_wahrscheinlich" ;
VAL_ 617 PIF_ST_Bin_8 0 "ausgeschlossen" 1 "unwahrscheinlich" 2 "wahrscheinlich" 3 "sehr_wahrscheinlich" ;
VAL_ 617 PIF_MT_Bin_0 0 "ausgeschlossen" 1 "unwahrscheinlich" 2 "wahrscheinlich" 3 "sehr_wahrscheinlich" ;
VAL_ 617 PIF_MT_Bin_1 0 "ausgeschlossen" 1 "unwahrscheinlich" 2 "wahrscheinlich" 3 "sehr_wahrscheinlich" ;
VAL_ 617 PIF_MT_Bin_2 0 "ausgeschlossen" 1 "unwahrscheinlich" 2 "wahrscheinlich" 3 "sehr_wahrscheinlich" ;
VAL_ 617 PIF_MT_Bin_3 0 "ausgeschlossen" 1 "unwahrscheinlich" 2 "wahrscheinlich" 3 "sehr_wahrscheinlich" ;
VAL_ 617 PIF_MT_Bin_4 0 "ausgeschlossen" 1 "unwahrscheinlich" 2 "wahrscheinlich" 3 "sehr_wahrscheinlich" ;
VAL_ 617 PIF_MT_Bin_5 0 "ausgeschlossen" 1 "unwahrscheinlich" 2 "wahrscheinlich" 3 "sehr_wahrscheinlich" ;
VAL_ 617 PIF_MT_Bin_6 0 "ausgeschlossen" 1 "unwahrscheinlich" 2 "wahrscheinlich" 3 "sehr_wahrscheinlich" ;
VAL_ 617 PIF_MT_Bin_7 0 "ausgeschlossen" 1 "unwahrscheinlich" 2 "wahrscheinlich" 3 "sehr_wahrscheinlich" ;
VAL_ 617 PIF_MT_Bin_8 0 "ausgeschlossen" 1 "unwahrscheinlich" 2 "wahrscheinlich" 3 "sehr_wahrscheinlich" ;
VAL_ 617 PIF_LT_Bin_0 0 "ausgeschlossen" 1 "unwahrscheinlich" 2 "wahrscheinlich" 3 "sehr_wahrscheinlich" ;
VAL_ 617 PIF_LT_Bin_1 0 "ausgeschlossen" 1 "unwahrscheinlich" 2 "wahrscheinlich" 3 "sehr_wahrscheinlich" ;
VAL_ 617 PIF_LT_Bin_2 0 "ausgeschlossen" 1 "unwahrscheinlich" 2 "wahrscheinlich" 3 "sehr_wahrscheinlich" ;
VAL_ 617 PIF_LT_Bin_3 0 "ausgeschlossen" 1 "unwahrscheinlich" 2 "wahrscheinlich" 3 "sehr_wahrscheinlich" ;
VAL_ 617 PIF_LT_Bin_4 0 "ausgeschlossen" 1 "unwahrscheinlich" 2 "wahrscheinlich" 3 "sehr_wahrscheinlich" ;
VAL_ 617 PIF_LT_Bin_5 0 "ausgeschlossen" 1 "unwahrscheinlich" 2 "wahrscheinlich" 3 "sehr_wahrscheinlich" ;
VAL_ 617 PIF_LT_Bin_6 0 "ausgeschlossen" 1 "unwahrscheinlich" 2 "wahrscheinlich" 3 "sehr_wahrscheinlich" ;
VAL_ 617 PIF_LT_Bin_7 0 "ausgeschlossen" 1 "unwahrscheinlich" 2 "wahrscheinlich" 3 "sehr_wahrscheinlich" ;
VAL_ 617 PIF_LT_Bin_8 0 "ausgeschlossen" 1 "unwahrscheinlich" 2 "wahrscheinlich" 3 "sehr_wahrscheinlich" ;
VAL_ 2527679715 pVS_EnergieAnfr_Zaehler 14 "Init" 15 "Fehler" ;
VAL_ 2527679715 pVS_EnergieAnfr_SocStart 126 "Init" 127 "Fehler" ;
VAL_ 2527679715 pVS_EnergieAnfr_SocZiel 126 "Init" 127 "Fehler" ;
VAL_ 2527679715 pVS_Zielklimamodus_Range_pers 0 "noch_nicht_berechnet" 1 "Keine_Einschraenkung" 2 "ECO" 3 "ECO_plus_AC_off" 4 "reserved" 5 "FANonly" 6 "Init" 7 "Fehler" ;
VAL_ 2527679715 pVS_Zielklimamodus_Range 0 "noch_nicht_berechnet" 1 "Keine_Einschraenkung" 2 "ECO" 3 "ECO_plus_AC_off" 4 "reserved" 5 "FANonly" 6 "Init" 7 "Fehler" ;
VAL_ 2527679715 pVS_LadegrenzeAnfr_Zaehler 14 "Init" 15 "Fehler" ;
VAL_ 2527679715 pVS_LadegrenzeAnfr_Leistung 4094 "Init" 4095 "Fehler" ;
VAL_ 1616 RA_Radio_Error_Flag 0 "kein_KD_Fehler" 1 "KD_Fehler" ;
VAL_ 1616 RA_Frequency_unit 0 "1_kHz" 1 "100_kHz" ;
VAL_ 1616 RA_AM_Tuning 0 "frequency_locked" 1 "AM_tuning" ;
VAL_ 1525 RW_Gesamt_Reichweite_Max_Anzeige 2045 "nicht_verbaut" 2046 "Init" 2047 "Fehler" ;
VAL_ 1525 RW_Reservewarnung_2_aktiv 0 "Init" 1 "inaktiv" 2 "aktiv" 3 "reserviert" ;
VAL_ 1525 RW_RWDS_Lastprofil 2046 "Init" 2047 "Fehler" ;
VAL_ 1525 RW_Gesamt_Reichweite 2045 "nicht_verbaut" 2046 "Init" 2047 "Fehler" ;
VAL_ 1525 RW_Prim_Reichweitenverbrauch 2047 "Init" ;
VAL_ 1525 RW_Prim_Reichweitenv_Einheit 0 "Liter_pro_100km" 1 "kWh_pro_100km" 2 "Kg_pro_100km" 3 "nicht_verbaut" ;
VAL_ 1525 RW_Primaer_Reichweite 2045 "nicht_verbaut" 2046 "Init" 2047 "Fehler" ;
VAL_ 1527 RW_Tendenz 0 "keine_Tendenz" 1 "konstant" 2 "steigend" 3 "sinkend" ;
VAL_ 1527 RW_Texte 0 "kein_Text" 1 "Text_1" 2 "Text_2" 3 "Text_3" ;
VAL_ 1527 RW_Reservewarnung_aktiv 0 "inaktiv" 1 "aktiv" ;
VAL_ 1527 RW_Reichweite_Einheit_Anzeige 0 "km" 1 "miles" ;
VAL_ 1527 RW_Gesamt_Reichweite_Anzeige 2045 "nicht_verbaut" 2046 "Init" 2047 "Fehler" ;
VAL_ 1527 RW_Primaer_Reichweite_Anzeige 2045 "nicht_verbaut" 2046 "Init" 2047 "Fehler" ;
VAL_ 1527 RW_Sekundaer_Reichweite_Anzeige 2045 "nicht_verbaut" 2046 "Init" 2047 "Fehler" ;
VAL_ 1527 RW_Sekundaer_Reichweite 2045 "nicht_verbaut" 2046 "Init" 2047 "Fehler" ;
VAL_ 1527 RW_Sek_Reichweitenv_Einheit 0 "Liter_pro_100km" 1 "kWh_pro_100km" 2 "Kg_pro_100km" 3 "nicht_verbaut" ;
VAL_ 1527 RW_Sek_Reichweitenverbrauch 2047 "Init" ;
VAL_ 2463978658 Rezi_Status_Spgfreiheit 0 "Init" 1 "HV_Komponente_spannungsfrei" 2 "HV_Komp_nicht_spannungsfrei" 3 "Fehler_nicht_spannungsfrei" ;
VAL_ 2463978658 Rezi_Warnung_Uebertemperatur 0 "keine_Warnung" 1 "Warnung" ;
VAL_ 2463978658 Rezi_IstSpannung 511 "Fehler" ;
VAL_ 2463978658 Rezi_Fehler_Blockiert 0 "kein_Fehler" 1 "Fehler" ;
VAL_ 2463978658 Rezi_Fehler_Bauteil_Defekt 0 "kein_Fehler" 1 "Fehler" ;
VAL_ 2463978658 Rezi_Fehler_Ueberspannung_HV 0 "kein_Fehler" 1 "Fehler" ;
VAL_ 2463978658 Rezi_Fehler_Ueberspannung_NV 0 "kein_Fehler" 1 "Fehler" ;
VAL_ 2463978658 Rezi_Fehler_Uebertemperatur 0 "kein_Fehler" 1 "Fehler" ;
VAL_ 2463978658 Rezi_Fehler_Unterspannung_HV 0 "kein_Fehler" 1 "Fehler" ;
VAL_ 2463978658 Rezi_IstDrehzahl 16383 "Fehler" ;
VAL_ 2463978658 Rezi_Error_NW_Timeout 0 "TestNotCompleted_TOC" 1 "TestCompleted_TOC_PASS" 3 "TestCompleted_TOC_FAIL" ;
VAL_ 2463978658 Rezi_IstStrom 255 "Fehler" ;
VAL_ 1126 RTM_Warnstatus 0 "keine_Warnung" 1 "Warnstufe_ChNational" 2 "reserviert" 3 "reserviert" ;
VAL_ 1313 STH_Funk_ein 0 "kein Funkbefehl zum Einschalten" 1 "Funkbefehl zum Einschalten erhalten" ;
VAL_ 1313 STH_Funk_aus 0 "kein Funkbefehl" 1 "Funkbefehl zum Ausschalten erhalten" ;
VAL_ 1313 STH_Zusatzheizung 0 "Zuheizer aus" 1 "Zuheizer ein" ;
VAL_ 1313 STH_LED 0 "keine Rückmeldung" 1 "Rueckmeldung Standheizung in Betrieb" ;
VAL_ 1313 STH_Geblaese 0 "kein Einschaltbefehl an die Klimaanlage, Gebläse" 1 "Einschaltbefehl an die Klimaanlage, Gebläse" ;
VAL_ 1313 STH_EKP_Anst 0 "EKP nicht ansteuern" 1 "EKP ansteuern" ;
VAL_ 1313 STH_Start_folgt 0 "kein_Start_folgt" 1 "Start_folgt" ;
VAL_ 1313 STH_Ventil_Status 0 "Ventil_offen__grosser_Kreislauf" 1 "Ventil_geschlossen__kleiner_Kreislauf" ;
VAL_ 1313 STH_Fehler_ElWaPu 0 "kein_Fehler" 1 "Fehler" ;
VAL_ 1313 STH_Pumpen_Anf_extern 0 "nicht_angefordert" 1 "angefordert" ;
VAL_ 1313 STH_KL_HUP 0 "Aus" 1 "Ein" ;
VAL_ 1313 STH_Fehlerstatus 0 "kein_Fehler" 1 "Unterspannung" 2 "Tankfuellstand_zu_gering" 3 "Fehler_Betrieb_verhindert" 4 "Heizgeraet_verriegelt" 5 "Fehler_Betrieb_nicht_verhindert" 6 "Emissionsüberschreitung" ;
VAL_ 1313 STH_Wassertemp 254 "Init" 255 "Fehler" ;
VAL_ 1313 STH_Texte 0 "keine_Anzeige" 1 "Batteriemanagementeinschraenkung" 2 "Kraftstoffmangel" 3 "interner_Systemfehler" 4 "Heizzeitueberschreitung" ;
VAL_ 1313 STH_Motorvorwaermung 0 "keine Motorvorwärmung erfolgt" 1 "Aufheizung mit Motorvorwärmung erfolgt" ;
VAL_ 1313 STH_war_aktiv 0 "war inaktiv" 1 "Standheizung war letzte halbe Stunde aktiv" ;
VAL_ 1313 STH_KVS_Ueberlauf 0 "kein Überlauf" 1 "Kraftstoffverbrauchssignal, mindestens ein Überlauf hat stattgefunden" ;
VAL_ 1313 STH_SH_ZH 0 "Heizgeraet_WZH" 1 "Heizgeraet_ZH" ;
VAL_ 505 STP_Slave_Status 0 "STP_Slave_Init" 1 "STP_Slave_Deaktiviert" 2 "STP_Slave_Ready" 3 "Vorhalt" 4 "STP_Slave_Aktivierverhinderung" 5 "STP_Slave_Aktiv" 6 "STP_Slave_ESK_Uebernahme" 7 "STP_Slave_Uebergabe" 8 "STP_Slave_ESK0_Anf" 9 "STP_Slave_ESK1_Anf" 10 "STP_Slave_ESK2_Anf" 11 "STP_Slave_ESK3_Anf" 12 "STP_Slave_stabiler_Zustand" 13 "STP_Slave_Notlauf_Aktiv" 14 "STP_Slave_nicht_verfuegbar" 15 "STP_Slave_Error" ;
VAL_ 505 FZE_STP_Abschaltbedingung 0 "Vorhalt" 1 "STP_Abschaltbedingung_liegt_nicht_an" 2 "Vorhalt" 3 "STP_ESK0" 4 "STP_ESK1" 5 "STP_ESK2" 6 "STP_ESK3" 7 "STP_NL" ;
VAL_ 505 ACA_HF_Grund_AV_AB 0 "Liegt_nicht_an_oder_init" 1 "LRR_Kriterium" 2 "Fahrerbeobachtung" 3 "Fahrerlenkeingriff" 4 "Vorhalt" 5 "Vorhalt" 6 "Vorhalt" 7 "Vorhalt" ;
VAL_ 505 FZE_STP_Status 0 "Init" 1 "Ready" 2 "Fehler_reversible" 3 "Fehler_irreversible" ;
VAL_ 505 STP_Notlaufaktivierung 0 "Notlauf_nicht_angefordert" 1 "Notlauf_angefordert" ;
VAL_ 505 STP_Funktion_freigegeben 0 "nicht_freigegeben" 1 "freigegeben" ;
VAL_ 505 ACA_QF_Status_Anzeige 0 "ACA_QF_nicht_codiert" 1 "ACA_QF_INIT" 2 "ACA_QF_AUS" 3 "ACA_QF_PASSIV" 4 "ACA_QF_AKTIV" 5 "ACA_QF_UEBERLENKT" 6 "ACA_QF_Abschaltreaktion" 7 "ACA_QF_reversibler_Fehler" 8 "ACA_QF_irreversibler_Fehler" 9 "ACA_QF_Sensor_Blindheit" ;
VAL_ 505 ACF_SwuFahrerUnaufmerksam 0 "Swu_Fahrer_Nicht_unaufmerksam" 1 "Swu_Fahrer_unaufmerksam" ;
VAL_ 505 ACA_QF_Fahreruebernahme 0 "keine" 1 "Uebernahme_1" 2 "Uebernahme_2" 3 "Uebernahme_3" ;
VAL_ 505 ACA_HF_Status 0 "ACA_HF_nicht_codiert" 1 "ACA_HF_Init" 2 "ACA_HF_aus" 3 "ACA_HF_nicht_verfuegbar" 4 "ACA_HF_verfuegbar" 5 "ACA_HF_aktiv" 6 "Vorhalt" 7 "ACA_HF_reversibler_Fehler" 8 "ACA_HF_irreversibler_Fehler" 9 "ACA_HF_Uebernahme_1" 10 "ACA_HF_Uebernahme_2" 11 "Vorhalt" 12 "Vorhalt" 13 "Vorhalt" 14 "Vorhalt" 15 "Vorhalt" ;
VAL_ 505 FZE_Spurwechsel_erkannt_li 0 "kein_Spurwechsel_erkannt" 1 "Spurwechsel_erkannt_links" ;
VAL_ 505 FZE_Spurwechsel_erkannt_re 0 "kein_Spurwechsel_erkannt" 1 "Spurwechsel_erkannt_rechts" ;
VAL_ 505 ACF_Spurwechsel_moeglich 0 "keine_Spurwechselmoeglichkeit_vorhanden" 1 "Spurwechselmoeglichkeit_vorhanden" ;
VAL_ 505 ACF_Spurwechsel_wahrscheinlich 0 "kein_Spurwechsel" 1 "Spurwechsel_wahrscheinlich" ;
VAL_ 505 FZE_STP_Aktivierverhinderung 0 "liegt_nicht_an" 1 "Fahrer_nicht_erkannt" 2 "Vorhalt" 3 "Vorhalt" ;
VAL_ 1001 Thermo_Pred_T_dyn_Innen 254 "Init" 255 "Fehler" ;
VAL_ 1001 Thermo_Pred_P_dyn_Innen 2046 "Init" 2047 "Fehler" ;
VAL_ 1001 Thermo_Pred_P_stat_Innen 2046 "Init" 2047 "Fehler" ;
VAL_ 1001 Thermo_Verbrauch_BTL_Ueberlauf 0 "kein_Ueberlauf" 1 "Ueberlauf" ;
VAL_ 1001 Thermo_Verbrauch_Innen_Ueberlauf 0 "kein_Ueberlauf" 1 "Ueberlauf" ;
VAL_ 1015 KL_HV_Energie_Anf 253 "nicht_berechnet" 254 "Init" 255 "Fehler" ;
VAL_ 1015 TME_Kuehlerluefer_3 126 "Init" 127 "Fehler" ;
VAL_ 1015 TME_StartStopp_Info_Prio 0 "Motorlauf_zwingend" 1 "Motorlauf_nicht_zwingend" ;
VAL_ 1015 TME_HVEM_HV_Anf 0 "INIT" 1 "HV_Netz_nicht_angefordert" 2 "HV_Netz_angefordert" 3 "Fehler" ;
VAL_ 1015 TME_StartStopp_Info 0 "Stoppfreigabe" 1 "Stoppverbot" 2 "Startanforderung" 3 "Fehler" ;
VAL_ 1015 TME_OBD_Lampe_Anf 0 "kein_MIL_Request" 1 "MIL_Request" ;
VAL_ 1015 TME_HVPTC_Istmodus 0 "Standby" 1 "Regelung_aktiv" 2 "Freigabe_ausgesetzt" 5 "Fehler" 7 "Init" ;
VAL_ 1015 TME_HVPTC_Fehlerstatus 0 "Komponente_IO" 1 "Keine_HV_Spannung" 3 "Eingeschr_KompFkt_Interlock" 6 "Keine_Komponentenfunktion" 7 "Init" ;
VAL_ 1015 TME_EKK_Istmodus 0 "Standby" 1 "Regelung_aktiv" 2 "Freigabe_ausgesetzt" 5 "Fehler" 7 "Init" ;
VAL_ 1015 TME_EKK_Fehlerstatus 0 "Komponente_IO" 1 "Keine_HV_Spannung" 3 "Eingeschr_KompFkt_Interlock" 6 "Keine_Komponentenfunktion" 7 "Init" ;
VAL_ 1015 TME_HVK_EKK_SOLL 0 "Init" 1 "Off" 2 "On" 3 "Fehler" ;
VAL_ 1015 TME_Strom_Kuehlerluefter 30 "Init" 31 "Fehler" ;
VAL_ 1015 TME_PWM_Pumpe1_tNT_Soll 126 "Init" 127 "Fehler" ;
VAL_ 1017 TME_NT_Kreis_Status 0 "kein_Fehler" 1 "Fehler" ;
VAL_ 1017 TME_Ventil1_Status 0 "Ventil_offen__grosser_Kreislauf" 1 "Ventil_geschlossen__kleiner_Kreislauf" ;
VAL_ 1017 TME_Fehler_ElWaPu1 0 "kein_Fehler" 1 "Fehler" ;
VAL_ 1017 TME_Pumpe1_Status 0 "inaktiv" 1 "aktiv" ;
VAL_ 1017 TME_Nachlaufzeit 0 "Init" ;
VAL_ 1017 TME_Anf_KL 126 "Init" 127 "Fehler" ;
VAL_ 1017 TME_Status_KL 0 "kein_Fehler" 1 "Fehler_KL_1" 2 "Fehler_KL_2" 3 "Fehler_KL_1_und_KL_2" ;
VAL_ 1017 TME_EM1_IstVolumenstrom 30 "Init" 31 "Fehler" ;
VAL_ 1017 TME_EM2_IstVolumenstrom 30 "Init" 31 "Fehler" ;
VAL_ 1017 TME_EM3_IstVolumenstrom 30 "Init" 31 "Fehler" ;
VAL_ 1017 TME_PWM_Pumpe2_HK_Soll 126 "Init" 127 "Fehler" ;
